VERSION ""

NS_ :

BS_:

BU_: AHLM ASBS CBC DIAGNOST DPDM DTCM ECM EHPS ESC ESL ESM ETM GPF HCP IC IRCM OCM ORC PTS RF_HUB SCCM SGW TBM TCM TPM

BO_ 1026 NM_IC: 8 IC
 SG_ Awake_Diag_Actv m15 : 33|1@1+ (1,0) [0|0] ""  CBC,EHPS,ESC,ESL,ESM,HCP,IC,RF_HUB,SCCM,SGW,TPM
 SG_ Awake_NwSt m15 : 32|1@1+ (1,0) [0|0] ""  CBC,EHPS,ESC,ESL,ESM,HCP,IC,RF_HUB,SCCM,SGW,TPM
 SG_ NM_Mode : 0|8@1+ (1,0) [0|0] ""  CBC,EHPS,ESC,ESL,ESM,HCP,IC,RF_HUB,SCCM,SGW,TPM
 SG_ NM_Sleep_Ack : 22|1@1+ (1,0) [0|0] ""  CBC,EHPS,ESC,ESL,ESM,HCP,IC,RF_HUB,SCCM,SGW,TPM
 SG_ NM_Sleep_Ind : 23|1@1+ (1,0) [0|0] ""  CBC,EHPS,ESC,ESL,ESM,HCP,IC,RF_HUB,SCCM,SGW,TPM
 SG_ NM_Successor : 8|8@1+ (1,0) [0|63] ""  CBC,EHPS,ESC,ESL,ESM,HCP,IC,RF_HUB,SCCM,SGW,TPM
 SG_ NM_Ud_Launch : 16|6@1+ (1,0) [0|0] ""  CBC,EHPS,ESC,ESL,ESM,HCP,IC,RF_HUB,SCCM,SGW,TPM
 SG_ NM_Ud_Srv M : 24|8@1+ (1,0) [0|0] ""  CBC,EHPS,ESC,ESL,ESM,HCP,IC,RF_HUB,SCCM,SGW,TPM
 SG_ Nw_Id : 56|8@1+ (1,0) [0|0] ""  CBC,EHPS,ESC,ESL,ESM,HCP,IC,RF_HUB,SCCM,SGW,TPM
 SG_ WakeupCnt m2 : 40|8@1+ (1,0) [0|254] ""  CBC,EHPS,ESC,ESL,ESM,HCP,IC,RF_HUB,SCCM,SGW,TPM
 SG_ WakeupRsn_IC m2 : 32|8@1+ (1,0) [0|0] ""  CBC,EHPS,ESC,ESL,ESM,HCP,IC,RF_HUB,SCCM,SGW,TPM

BO_ 1024 NM_RF_HUB: 8 RF_HUB
 SG_ Awake_Diag_Actv m15 : 33|1@1+ (1,0) [0|0] ""  CBC,EHPS,ESC,ESL,ESM,HCP,IC,RF_HUB,SCCM,SGW,TPM
 SG_ Awake_NwSt m15 : 32|1@1+ (1,0) [0|0] ""  CBC,EHPS,ESC,ESL,ESM,HCP,IC,RF_HUB,SCCM,SGW,TPM
 SG_ NM_Mode : 0|8@1+ (1,0) [0|0] ""  CBC,EHPS,ESC,ESL,ESM,HCP,IC,RF_HUB,SCCM,SGW,TPM
 SG_ NM_Sleep_Ack : 22|1@1+ (1,0) [0|0] ""  CBC,EHPS,ESC,ESL,ESM,HCP,IC,RF_HUB,SCCM,SGW,TPM
 SG_ NM_Sleep_Ind : 23|1@1+ (1,0) [0|0] ""  CBC,EHPS,ESC,ESL,ESM,HCP,IC,RF_HUB,SCCM,SGW,TPM
 SG_ NM_Successor : 8|8@1+ (1,0) [0|63] ""  CBC,EHPS,ESC,ESL,ESM,HCP,IC,RF_HUB,SCCM,SGW,TPM
 SG_ NM_Ud_Launch : 16|6@1+ (1,0) [0|0] ""  CBC,EHPS,ESC,ESL,ESM,HCP,IC,RF_HUB,SCCM,SGW,TPM
 SG_ NM_Ud_Srv M : 24|8@1+ (1,0) [0|0] ""  CBC,EHPS,ESC,ESL,ESM,HCP,IC,RF_HUB,SCCM,SGW,TPM
 SG_ Nw_Id : 56|8@1+ (1,0) [0|0] ""  CBC,EHPS,ESC,ESL,ESM,HCP,IC,RF_HUB,SCCM,SGW,TPM
 SG_ WakeupCnt m2 : 40|8@1+ (1,0) [0|254] ""  CBC,EHPS,ESC,ESL,ESM,HCP,IC,RF_HUB,SCCM,SGW,TPM
 SG_ WakeupRsn_RF_HUB m2 : 32|8@1+ (1,0) [0|0] ""  CBC,EHPS,ESC,ESL,ESM,HCP,IC,RF_HUB,SCCM,SGW,TPM

BO_ 1033 NM_SBWM: 8 ESM
 SG_ Awake_Diag_Actv m15 : 33|1@1+ (1,0) [0|0] ""  CBC,EHPS,ESC,ESL,ESM,HCP,IC,RF_HUB,SCCM,SGW,TPM
 SG_ Awake_EEPROM m15 : 35|1@1+ (1,0) [0|0] ""  CBC,EHPS,ESC,ESL,ESM,HCP,IC,RF_HUB,SCCM,SGW,TPM
 SG_ Awake_Ignition_On m15 : 34|1@1+ (1,0) [0|0] ""  CBC,EHPS,ESC,ESL,ESM,HCP,IC,RF_HUB,SCCM,SGW,TPM
 SG_ Awake_NwSt m15 : 32|1@1+ (1,0) [0|0] ""  CBC,EHPS,ESC,ESL,ESM,HCP,IC,RF_HUB,SCCM,SGW,TPM
 SG_ Awake_URS m15 : 36|1@1+ (1,0) [0|0] ""  CBC,EHPS,ESC,ESL,ESM,HCP,IC,RF_HUB,SCCM,SGW,TPM
 SG_ NM_Mode : 0|8@1+ (1,0) [0|0] ""  CBC,EHPS,ESC,ESL,ESM,HCP,IC,RF_HUB,SCCM,SGW,TPM
 SG_ NM_Sleep_Ack : 22|1@1+ (1,0) [0|0] ""  CBC,EHPS,ESC,ESL,ESM,HCP,IC,RF_HUB,SCCM,SGW,TPM
 SG_ NM_Sleep_Ind : 23|1@1+ (1,0) [0|0] ""  CBC,EHPS,ESC,ESL,ESM,HCP,IC,RF_HUB,SCCM,SGW,TPM
 SG_ NM_Successor : 8|8@1+ (1,0) [0|63] ""  CBC,EHPS,ESC,ESL,ESM,HCP,IC,RF_HUB,SCCM,SGW,TPM
 SG_ NM_Ud_Launch : 16|6@1+ (1,0) [0|0] ""  CBC,EHPS,ESC,ESL,ESM,HCP,IC,RF_HUB,SCCM,SGW,TPM
 SG_ NM_Ud_Srv M : 24|8@1+ (1,0) [0|0] ""  CBC,EHPS,ESC,ESL,ESM,HCP,IC,RF_HUB,SCCM,SGW,TPM
 SG_ Nw_Id : 56|8@1+ (1,0) [0|0] ""  CBC,EHPS,ESC,ESL,ESM,HCP,IC,RF_HUB,SCCM,SGW,TPM
 SG_ WakeupCnt m2 : 40|8@1+ (1,0) [0|254] ""  CBC,EHPS,ESC,ESL,ESM,HCP,IC,RF_HUB,SCCM,SGW,TPM
 SG_ WakeupRsn_SBWM m2 : 32|8@1+ (1,0) [0|0] ""  CBC,EHPS,ESC,ESL,ESM,HCP,IC,RF_HUB,SCCM,SGW,TPM

BO_ 1059 NM_SCCM: 8 SCCM
 SG_ Awake_Diag_Actv m15 : 33|1@1+ (1,0) [0|0] ""  CBC,EHPS,ESC,ESL,ESM,HCP,IC,RF_HUB,SCCM,SGW,TPM
 SG_ Awake_EEPROM m15 : 36|1@1+ (1,0) [0|0] ""  CBC,EHPS,ESC,ESL,ESM,HCP,IC,RF_HUB,SCCM,SGW,TPM
 SG_ Awake_FTP_Psd m15 : 38|1@1+ (1,0) [0|0] ""  CBC,EHPS,ESC,ESL,ESM,HCP,IC,RF_HUB,SCCM,SGW,TPM
 SG_ Awake_HrnSwt_Actv m15 : 39|1@1+ (1,0) [0|0] ""  CBC,EHPS,ESC,ESL,ESM,HCP,IC,RF_HUB,SCCM,SGW,TPM
 SG_ Awake_Ignition_On m15 : 35|1@1+ (1,0) [0|0] ""  CBC,EHPS,ESC,ESL,ESM,HCP,IC,RF_HUB,SCCM,SGW,TPM
 SG_ Awake_NwSt m15 : 32|1@1+ (1,0) [0|0] ""  CBC,EHPS,ESC,ESL,ESM,HCP,IC,RF_HUB,SCCM,SGW,TPM
 SG_ Awake_StwSw_Actv m15 : 34|1@1+ (1,0) [0|0] ""  CBC,EHPS,ESC,ESL,ESM,HCP,IC,RF_HUB,SCCM,SGW,TPM
 SG_ Awake_tilt_tel_Psd m15 : 37|1@1+ (1,0) [0|0] ""  CBC,EHPS,ESC,ESL,ESM,HCP,IC,RF_HUB,SCCM,SGW,TPM
 SG_ NM_Mode : 0|8@1+ (1,0) [0|0] ""  CBC,EHPS,ESC,ESL,ESM,HCP,IC,RF_HUB,SCCM,SGW,TPM
 SG_ NM_Sleep_Ack : 22|1@1+ (1,0) [0|0] ""  CBC,EHPS,ESC,ESL,ESM,HCP,IC,RF_HUB,SCCM,SGW,TPM
 SG_ NM_Sleep_Ind : 23|1@1+ (1,0) [0|0] ""  CBC,EHPS,ESC,ESL,ESM,HCP,IC,RF_HUB,SCCM,SGW,TPM
 SG_ NM_Successor : 8|8@1+ (1,0) [0|63] ""  CBC,EHPS,ESC,ESL,ESM,HCP,IC,RF_HUB,SCCM,SGW,TPM
 SG_ NM_Ud_Launch : 16|6@1+ (1,0) [0|0] ""  CBC,EHPS,ESC,ESL,ESM,HCP,IC,RF_HUB,SCCM,SGW,TPM
 SG_ NM_Ud_Srv M : 24|8@1+ (1,0) [0|0] ""  CBC,EHPS,ESC,ESL,ESM,HCP,IC,RF_HUB,SCCM,SGW,TPM
 SG_ Nw_Id : 56|8@1+ (1,0) [0|0] ""  CBC,EHPS,ESC,ESL,ESM,HCP,IC,RF_HUB,SCCM,SGW,TPM
 SG_ WakeupCnt m2 : 40|8@1+ (1,0) [0|254] ""  CBC,EHPS,ESC,ESL,ESM,HCP,IC,RF_HUB,SCCM,SGW,TPM
 SG_ WakeupRsn_SCCM m2 : 32|8@1+ (1,0) [0|0] ""  CBC,EHPS,ESC,ESL,ESM,HCP,IC,RF_HUB,SCCM,SGW,TPM

BO_ 1027 NM_TPM: 8 TPM
 SG_ Awake_Diag_Actv m15 : 33|1@1+ (1,0) [0|0] ""  CBC,EHPS,ESC,ESL,ESM,HCP,IC,RF_HUB,SCCM,SGW,TPM
 SG_ Awake_NwSt m15 : 32|1@1+ (1,0) [0|0] ""  CBC,EHPS,ESC,ESL,ESM,HCP,IC,RF_HUB,SCCM,SGW,TPM
 SG_ NM_Mode : 0|8@1+ (1,0) [0|0] ""  CBC,EHPS,ESC,ESL,ESM,HCP,IC,RF_HUB,SCCM,SGW,TPM
 SG_ NM_Sleep_Ack : 22|1@1+ (1,0) [0|0] ""  CBC,EHPS,ESC,ESL,ESM,HCP,IC,RF_HUB,SCCM,SGW,TPM
 SG_ NM_Sleep_Ind : 23|1@1+ (1,0) [0|0] ""  CBC,EHPS,ESC,ESL,ESM,HCP,IC,RF_HUB,SCCM,SGW,TPM
 SG_ NM_Successor : 8|8@1+ (1,0) [0|63] ""  CBC,EHPS,ESC,ESL,ESM,HCP,IC,RF_HUB,SCCM,SGW,TPM
 SG_ NM_Ud_Launch : 16|6@1+ (1,0) [0|0] ""  CBC,EHPS,ESC,ESL,ESM,HCP,IC,RF_HUB,SCCM,SGW,TPM
 SG_ NM_Ud_Srv M : 24|8@1+ (1,0) [0|0] ""  CBC,EHPS,ESC,ESL,ESM,HCP,IC,RF_HUB,SCCM,SGW,TPM
 SG_ Nw_Id : 56|8@1+ (1,0) [0|0] ""  CBC,EHPS,ESC,ESL,ESM,HCP,IC,RF_HUB,SCCM,SGW,TPM
 SG_ WakeupCnt m2 : 40|8@1+ (1,0) [0|254] ""  CBC,EHPS,ESC,ESL,ESM,HCP,IC,RF_HUB,SCCM,SGW,TPM
 SG_ WakeupRsn_TPM m2 : 32|8@1+ (1,0) [0|0] ""  CBC,EHPS,ESC,ESL,ESM,HCP,IC,RF_HUB,SCCM,SGW,TPM

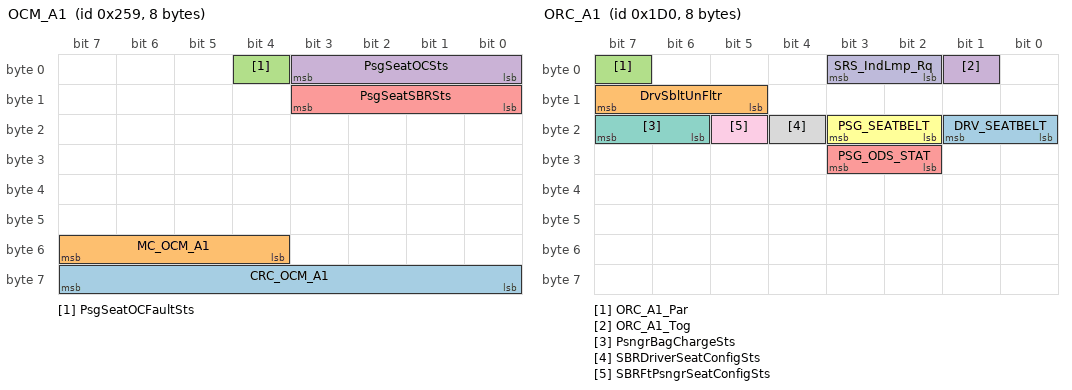
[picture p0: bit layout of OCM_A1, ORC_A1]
BO_ 601 OCM_A1: 8 OCM
 SG_ CRC_OCM_A1 : 56|8@1+ (1,0) [0|0] ""  ORC,SGW
 SG_ MC_OCM_A1 : 52|4@1+ (1,0) [0|15] ""  ORC,SGW
 SG_ PsgSeatOCFaultSts : 4|1@1+ (1,0) [0|0] ""  ORC,SGW
 SG_ PsgSeatOCSts : 0|4@1+ (1,0) [0|0] ""  ORC,RF_HUB,SGW
 SG_ PsgSeatSBRSts : 8|4@1+ (1,0) [0|0] ""  ORC,SGW

BO_ 464 ORC_A1: 8 ORC
 SG_ DRV_SEATBELT : 16|2@1+ (1,0) [0|0] ""  ESC,ETM,HCP,IC,IRCM,SGW,TBM,TCM
 SG_ DrvSbltUnFltr : 13|3@1+ (1,0) [0|0] ""  ECM,SGW
 SG_ ORC_A1_Par : 7|1@1+ (1,0) [0|0] ""  IRCM,SGW
 SG_ ORC_A1_Tog : 1|1@1+ (1,0) [0|0] ""  IRCM,SGW
 SG_ PSG_ODS_STAT : 26|2@1+ (1,0) [0|0] ""  ETM,IC,RF_HUB,SGW,TBM
 SG_ PSG_SEATBELT : 18|2@1+ (1,0) [0|0] ""  ESC,ETM,IC,OCM,SGW,TBM
 SG_ PsngrBagChargeSts : 22|2@1+ (1,0) [0|0] ""  IC,SGW
 SG_ SBRDriverSeatConfigSts : 20|1@1+ (1,0) [0|0] ""  IC,SGW
 SG_ SBRFtPsngrSeatConfigSts : 21|1@1+ (1,0) [0|0] ""  IC,SGW
 SG_ SRS_IndLmp_Rq : 2|2@1+ (1,0) [0|0] ""  ETM,IC,SGW,TBM

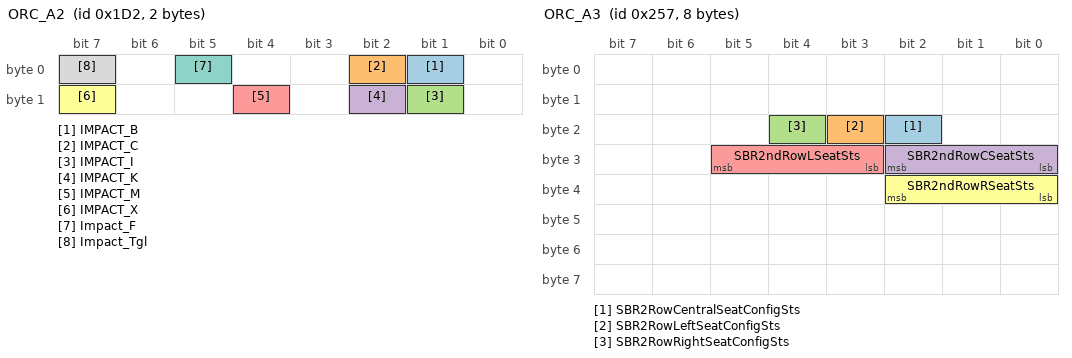
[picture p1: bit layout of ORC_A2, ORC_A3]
BO_ 466 ORC_A2: 2 ORC
 SG_ IMPACT_B : 1|1@1+ (1,0) [0|0] ""  ETM,SGW,TBM
 SG_ IMPACT_C : 2|1@1+ (1,0) [0|0] ""  ETM,SGW,TBM
 SG_ IMPACT_I : 9|1@1+ (1,0) [0|0] ""  ETM,SGW,TBM
 SG_ IMPACT_K : 10|1@1+ (1,0) [0|0] ""  ETM,SGW,TBM
 SG_ IMPACT_M : 12|1@1+ (1,0) [0|0] ""  ETM,SGW,TBM
 SG_ IMPACT_X : 15|1@1+ (1,0) [0|0] ""  CBC,ECM,ETM,HCP,OCM,SGW,TBM
 SG_ Impact_F : 5|1@1+ (1,0) [0|0] ""  ETM,SGW,TBM
 SG_ Impact_Tgl : 7|1@1+ (1,0) [0|0] ""  CBC,ECM,ETM,HCP,OCM,SGW,TBM

BO_ 599 ORC_A3: 8 ORC
 SG_ SBR2RowCentralSeatConfigSts : 18|1@1+ (1,0) [0|0] ""  IC,SGW
 SG_ SBR2RowLeftSeatConfigSts : 19|1@1+ (1,0) [0|0] ""  IC,SGW
 SG_ SBR2RowRightSeatConfigSts : 20|1@1+ (1,0) [0|0] ""  IC,SGW
 SG_ SBR2ndRowCSeatSts : 24|3@1+ (1,0) [0|0] ""  IC,SGW
 SG_ SBR2ndRowLSeatSts : 27|3@1+ (1,0) [0|0] ""  IC,SGW
 SG_ SBR2ndRowRSeatSts : 32|3@1+ (1,0) [0|0] ""  IC,SGW

BO_ 469 ORC_A4: 8 ORC
 SG_ ORC_Health : 23|1@1+ (1,0) [0|0] ""  HCP,SGW

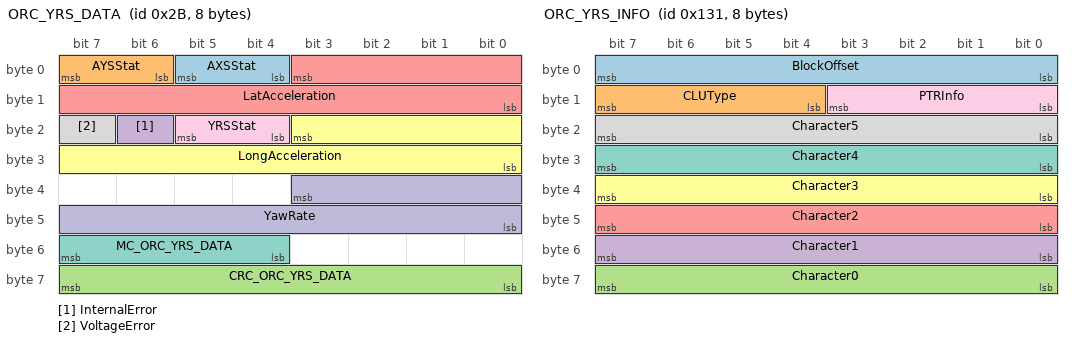
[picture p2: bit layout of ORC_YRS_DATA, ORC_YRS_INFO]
BO_ 43 ORC_YRS_DATA: 8 ORC
 SG_ AXSStat : 4|2@1+ (1,0) [0|0] ""  ESC,HCP,SGW
 SG_ AYSStat : 6|2@1+ (1,0) [0|0] ""  ESC,SGW
 SG_ CRC_ORC_YRS_DATA : 56|8@1+ (1,0) [0|0] ""  ESC,SGW
 SG_ InternalError : 22|1@1+ (1,0) [0|0] ""  ESC,SGW
 SG_ LatAcceleration : 3|12@0+ (0.02,-40.96) [-40.96|40.92] "m/s²"  ESC,SGW
 SG_ LongAcceleration : 19|12@0+ (0.02,-40.96) [-40.96|40.92] "m/s²"  ESC,HCP,SGW
 SG_ MC_ORC_YRS_DATA : 52|4@1+ (1,0) [0|15] ""  ESC,SGW
 SG_ VoltageError : 23|1@1+ (1,0) [0|0] ""  ESC,SGW
 SG_ YRSStat : 20|2@1+ (1,0) [0|0] ""  ESC,SGW
 SG_ YawRate : 35|12@0+ (0.08,-163.84) [-163.84|163.68] "°/s"  ESC,SGW

BO_ 305 ORC_YRS_INFO: 8 ORC
 SG_ BlockOffset : 0|8@1+ (1,0) [0|0] ""  ESC,SGW
 SG_ CLUType : 12|4@1+ (1,0) [0|0] ""  ESC,SGW
 SG_ Character0 : 56|8@1+ (1,0) [0|0] ""  ESC,SGW
 SG_ Character1 : 48|8@1+ (1,0) [0|0] ""  ESC,SGW
 SG_ Character2 : 40|8@1+ (1,0) [0|0] ""  ESC,SGW
 SG_ Character3 : 32|8@1+ (1,0) [0|0] ""  ESC,SGW
 SG_ Character4 : 24|8@1+ (1,0) [0|0] ""  ESC,SGW
 SG_ Character5 : 16|8@1+ (1,0) [0|0] ""  ESC,SGW
 SG_ PTRInfo : 8|4@1+ (1,0) [0|0] ""  ESC,SGW

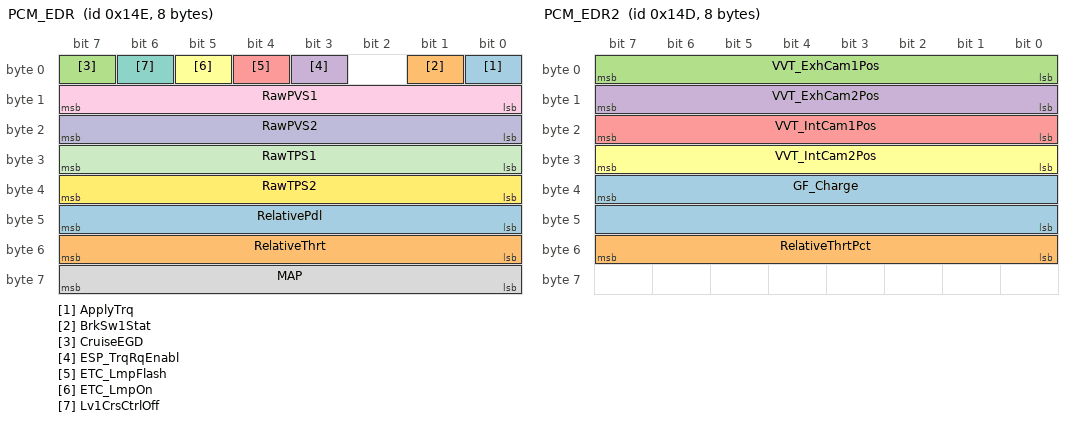
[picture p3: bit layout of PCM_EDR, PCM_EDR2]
BO_ 334 PCM_EDR: 8 ECM
 SG_ ApplyTrq : 0|1@1+ (1,0) [0|0] ""  SGW
 SG_ BrkSw1Stat : 1|1@1+ (1,0) [0|0] ""  ETM,SGW,TBM
 SG_ CruiseEGD : 7|1@1+ (1,0) [0|0] ""  SGW
 SG_ ESP_TrqRqEnabl : 3|1@1+ (1,0) [0|0] ""  ORC,SGW
 SG_ ETC_LmpFlash : 4|1@1+ (1,0) [0|0] ""  ORC,SGW
 SG_ ETC_LmpOn : 5|1@1+ (1,0) [0|0] ""  ORC,SGW
 SG_ Lv1CrsCtrlOff : 6|1@1+ (1,0) [0|0] ""  ORC,SGW
 SG_ MAP : 56|8@1+ (0.8,0) [0|203.2] "kPa"  ESC,SGW
 SG_ RawPVS1 : 8|8@1+ (0.019607843,0) [0|4.98] "Volts"  ORC,SGW
 SG_ RawPVS2 : 16|8@1+ (0.019607843,0) [0|4.98] "Volts"  ORC,SGW
 SG_ RawTPS1 : 24|8@1+ (0.019607843,0) [0|4.98] "Volts"  ORC,SGW
 SG_ RawTPS2 : 32|8@1+ (0.019607843,0) [0|4.98] "Volts"  ORC,SGW
 SG_ RelativePdl : 40|8@1+ (0.019607843,0) [0|4.98] "Volts"  SGW
 SG_ RelativeThrt : 48|8@1+ (0.019607843,0) [0|4.98] "Volts"  SGW

BO_ 333 PCM_EDR2: 8 ECM
 SG_ GF_Charge : 39|16@0+ (0.2,0) [0|13106.8] "mg/cycle/cyl"  ETM,ORC,SGW,TBM
 SG_ RelativeThrtPct : 48|8@1+ (0.4,0) [0|100] "%"  ORC,SGW
 SG_ VVT_ExhCam1Pos : 0|8@1+ (1,0) [1|255] "Degrees"  SGW
 SG_ VVT_ExhCam2Pos : 8|8@1+ (1,0) [1|255] "Degrees"  SGW
 SG_ VVT_IntCam1Pos : 16|8@1+ (1,0) [1|255] "Degrees"  SGW
 SG_ VVT_IntCam2Pos : 24|8@1+ (1,0) [1|255] "Degrees"  SGW

BO_ 584 PN14_STAT: 8 CBC
 SG_ Batt_ST_Crit : 42|1@1+ (1,0) [0|0] ""  IC,SGW
 SG_ PN14_LS_Actv : 0|1@1+ (1,0) [0|0] ""  IC,SGW

BO_ 502 PTS_1: 8 PTS
 SG_ PTS_AlrFC : 40|4@1+ (1,0) [0|0] ""  IC,SGW
 SG_ PTS_AlrFL : 8|4@1+ (1,0) [0|0] ""  IC,SGW
 SG_ PTS_AlrFR : 16|4@1+ (1,0) [0|0] ""  IC,SGW
 SG_ PTS_AlrRC : 48|4@1+ (1,0) [0|0] ""  CBC,IC,SGW
 SG_ PTS_AlrRL : 24|4@1+ (1,0) [0|0] ""  CBC,IC,SGW
 SG_ PTS_AlrRR : 32|4@1+ (1,0) [0|0] ""  CBC,IC,SGW
 SG_ PTS_CFG_STAT : 1|2@1+ (1,0) [0|0] ""  CBC,SGW
 SG_ PTS_FT_NA : 3|1@1+ (1,0) [0|0] ""  IC,SGW
 SG_ PTS_FT_SRV : 58|1@1+ (1,0) [0|0] ""  ETM,IC,SGW,TBM
 SG_ PTS_GraphicFC : 46|2@1+ (1,0) [0|0] ""  IC,SGW
 SG_ PTS_GraphicFL : 14|2@1+ (1,0) [0|0] ""  IC,SGW
 SG_ PTS_GraphicFR : 22|2@1+ (1,0) [0|0] ""  IC,SGW
 SG_ PTS_GraphicRC : 54|2@1+ (1,0) [0|0] ""  IC,SGW
 SG_ PTS_GraphicRL : 30|2@1+ (1,0) [0|0] ""  IC,SGW
 SG_ PTS_GraphicRR : 38|2@1+ (1,0) [0|0] ""  IC,SGW
 SG_ PTS_RR_NA : 4|1@1+ (1,0) [0|0] ""  IC,SGW
 SG_ PTS_RR_SRV : 59|1@1+ (1,0) [0|0] ""  ETM,IC,SGW,TBM
 SG_ PTS_SRV_RQ : 5|1@1+ (1,0) [0|0] ""  IC,SGW
 SG_ PTS_STAT : 60|2@1+ (1,0) [0|0] ""  CBC,SGW

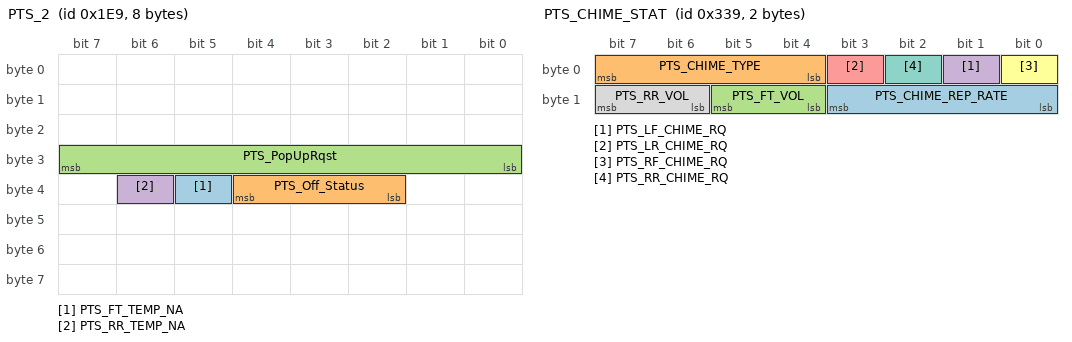
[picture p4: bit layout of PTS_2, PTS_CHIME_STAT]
BO_ 489 PTS_2: 8 PTS
 SG_ PTS_FT_TEMP_NA : 37|1@1+ (1,0) [0|0] ""  IC,SGW
 SG_ PTS_Off_Status : 34|3@1+ (1,0) [0|0] ""  IC,SGW
 SG_ PTS_PopUpRqst : 24|8@1+ (1,0) [0|0] ""  IC,SGW
 SG_ PTS_RR_TEMP_NA : 38|1@1+ (1,0) [0|0] ""  IC,SGW

BO_ 825 PTS_CHIME_STAT: 2 PTS
 SG_ PTS_CHIME_REP_RATE : 8|4@1+ (1,0) [0|15] "Hz"  CBC,SGW
 SG_ PTS_CHIME_TYPE : 4|4@1+ (1,0) [0|0] ""  CBC,SGW
 SG_ PTS_FT_VOL : 12|2@1+ (1,0) [0|0] ""  CBC,SGW
 SG_ PTS_LF_CHIME_RQ : 1|1@1+ (1,0) [0|0] ""  CBC,SGW
 SG_ PTS_LR_CHIME_RQ : 3|1@1+ (1,0) [0|0] ""  CBC,SGW
 SG_ PTS_RF_CHIME_RQ : 0|1@1+ (1,0) [0|0] ""  CBC,SGW
 SG_ PTS_RR_CHIME_RQ : 2|1@1+ (1,0) [0|0] ""  CBC,SGW
 SG_ PTS_RR_VOL : 14|2@1+ (1,0) [0|0] ""  CBC,SGW

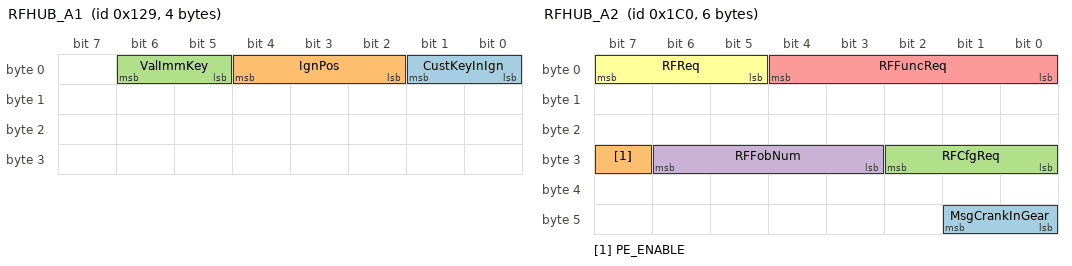
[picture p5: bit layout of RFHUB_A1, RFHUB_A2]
BO_ 297 RFHUB_A1: 4 RF_HUB
 SG_ CustKeyInIgn : 0|2@1+ (1,0) [0|0] ""  CBC,ETM,SGW,TBM
 SG_ IgnPos : 2|3@1+ (1,0) [0|0] ""  CBC,ETM,SGW,TBM
 SG_ ValImmKey : 5|2@1+ (1,0) [0|0] ""  SGW

BO_ 448 RFHUB_A2: 6 RF_HUB
 SG_ MsgCrankInGear : 40|2@1+ (1,0) [0|0] ""  IC,SGW
 SG_ PE_ENABLE : 31|1@1+ (1,0) [0|0] ""  CBC,SGW
 SG_ RFCfgReq : 24|3@1+ (1,0) [0|0] ""  CBC,SGW
 SG_ RFFobNum : 27|4@1+ (1,0) [0|0] ""  CBC,SGW
 SG_ RFFuncReq : 0|5@1+ (1,0) [0|0] ""  CBC,ETM,IC,SGW,TBM
 SG_ RFReq : 5|3@1+ (1,0) [0|0] ""  CBC,ETM,IC,SGW,TBM

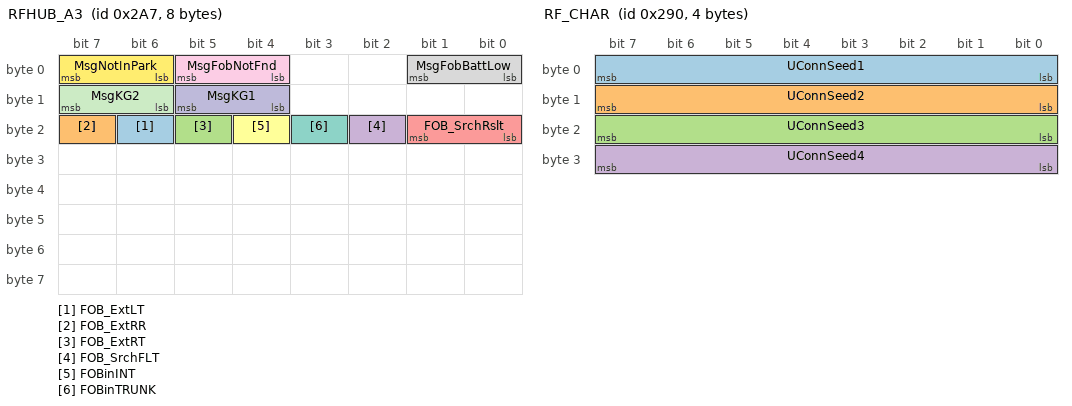
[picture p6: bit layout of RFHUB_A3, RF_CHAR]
BO_ 679 RFHUB_A3: 8 RF_HUB
 SG_ FOB_ExtLT : 22|1@1+ (1,0) [0|0] ""  CBC,SGW
 SG_ FOB_ExtRR : 23|1@1+ (1,0) [0|0] ""  CBC,SGW
 SG_ FOB_ExtRT : 21|1@1+ (1,0) [0|0] ""  CBC,SGW
 SG_ FOB_SrchFLT : 18|1@1+ (1,0) [0|0] ""  CBC,SGW
 SG_ FOB_SrchRslt : 16|2@1+ (1,0) [0|0] ""  CBC,SGW
 SG_ FOBinINT : 20|1@1+ (1,0) [0|0] ""  CBC,SGW
 SG_ FOBinTRUNK : 19|1@1+ (1,0) [0|0] ""  SGW
 SG_ MsgFobBattLow : 0|2@1+ (1,0) [0|0] ""  IC,SGW
 SG_ MsgFobNotFnd : 4|2@1+ (1,0) [0|0] ""  IC,SGW
 SG_ MsgKG1 : 12|2@1+ (1,0) [0|0] ""  IC,SGW
 SG_ MsgKG2 : 14|2@1+ (1,0) [0|0] ""  IC,SGW
 SG_ MsgNotInPark : 6|2@1+ (1,0) [0|0] ""  IC,SGW

BO_ 656 RF_CHAR: 4 RF_HUB
 SG_ UConnSeed1 : 0|8@1+ (1,0) [0|0] ""  ETM,SGW,TBM
 SG_ UConnSeed2 : 8|8@1+ (1,0) [0|0] ""  ETM,SGW,TBM
 SG_ UConnSeed3 : 16|8@1+ (1,0) [0|0] ""  ETM,SGW,TBM
 SG_ UConnSeed4 : 24|8@1+ (1,0) [0|0] ""  ETM,SGW,TBM

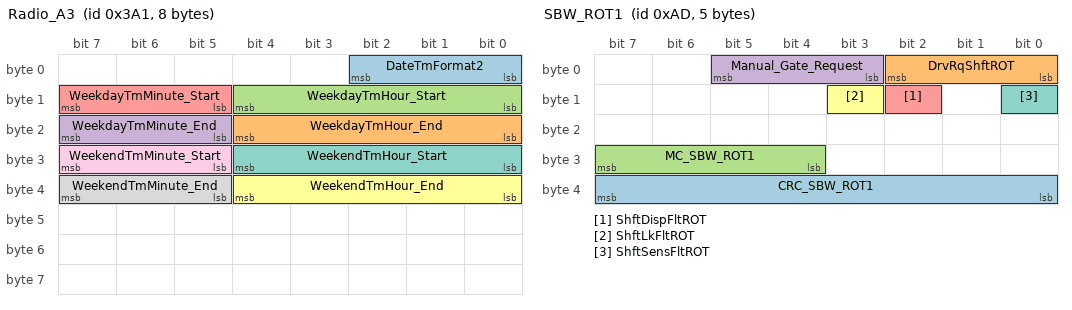
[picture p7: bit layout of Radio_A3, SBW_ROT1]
BO_ 929 Radio_A3: 8 CBC
 SG_ DateTmFormat2 : 0|3@1+ (1,0) [0|0] ""  HCP,IC,SGW
 SG_ WeekdayTmHour_End : 16|5@1+ (1,0) [0|24] "Hours"  IC,SGW
 SG_ WeekdayTmHour_Start : 8|5@1+ (1,0) [0|24] "Hours"  IC,SGW
 SG_ WeekdayTmMinute_End : 21|3@1+ (1,0) [0|0] "min"  IC,SGW
 SG_ WeekdayTmMinute_Start : 13|3@1+ (1,0) [0|0] "min"  IC,SGW
 SG_ WeekendTmHour_End : 32|5@1+ (1,0) [0|24] "Hours"  IC,SGW
 SG_ WeekendTmHour_Start : 24|5@1+ (1,0) [0|24] "Hours"  IC,SGW
 SG_ WeekendTmMinute_End : 37|3@1+ (1,0) [0|0] "min"  IC,SGW
 SG_ WeekendTmMinute_Start : 29|3@1+ (1,0) [0|0] "min"  IC,SGW

BO_ 302 Radio_A4: 8 CBC
 SG_ STFAFtAlertPress : 0|8@1+ (1,0) [0|126] "psi"  SGW,TPM
 SG_ STFARrAlertPress : 8|8@1+ (1,0) [0|126] "psi"  SGW,TPM

BO_ 173 SBW_ROT1: 5 ESM
 SG_ CRC_SBW_ROT1 : 32|8@1+ (1,0) [0|0] ""  ECM,HCP,SGW,TCM
 SG_ DrvRqShftROT : 0|3@1+ (1,0) [0|0] ""  CBC,DTCM,ECM,ETM,HCP,RF_HUB,SGW,TBM,TCM
 SG_ MC_SBW_ROT1 : 28|4@1+ (1,0) [0|15] ""  ECM,HCP,SGW,TCM
 SG_ Manual_Gate_Request : 3|3@1+ (1,0) [0|0] ""  ECM,SGW,TCM
 SG_ ShftDispFltROT : 10|1@1+ (1,0) [0|0] ""  SGW,TCM
 SG_ ShftLkFltROT : 11|1@1+ (1,0) [0|0] ""  SGW,TCM
 SG_ ShftSensFltROT : 8|1@1+ (1,0) [0|0] ""  IC,SGW,TCM

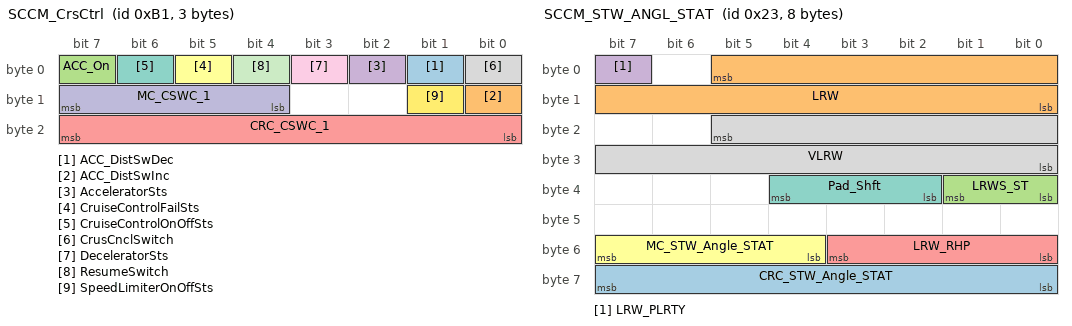
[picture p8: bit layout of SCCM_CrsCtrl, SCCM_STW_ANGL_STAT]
BO_ 177 SCCM_CrsCtrl: 3 SCCM
 SG_ ACC_DistSwDec : 1|1@1+ (1,0) [0|0] ""  ECM,ETM,IRCM,SGW,TBM
 SG_ ACC_DistSwInc : 8|1@1+ (1,0) [0|0] ""  ECM,ETM,IRCM,SGW,TBM
 SG_ ACC_On : 7|1@1+ (1,0) [0|0] ""  ECM,ESC,ETM,IRCM,SGW,TBM
 SG_ AcceleratorSts : 2|1@1+ (1,0) [0|0] ""  ECM,ESC,ETM,IRCM,SGW,TBM
 SG_ CRC_CSWC_1 : 16|8@1+ (1,0) [0|0] ""  ECM,IRCM,SGW
 SG_ CruiseControlFailSts : 5|1@1+ (1,0) [0|0] ""  ECM,ESC,IRCM,SGW
 SG_ CruiseControlOnOffSts : 6|1@1+ (1,0) [0|0] ""  ECM,ESC,ETM,IRCM,SGW,TBM
 SG_ CrusCnclSwitch : 0|1@1+ (1,0) [0|0] ""  ECM,ESC,ETM,IRCM,SGW,TBM
 SG_ DeceleratorSts : 3|1@1+ (1,0) [0|0] ""  ECM,ESC,ETM,IRCM,SGW,TBM
 SG_ MC_CSWC_1 : 12|4@1+ (1,0) [0|15] ""  ECM,IRCM,SGW
 SG_ ResumeSwitch : 4|1@1+ (1,0) [0|0] ""  ECM,ESC,ETM,IRCM,SGW,TBM
 SG_ SpeedLimiterOnOffSts : 9|1@1+ (1,0) [0|0] ""  ECM,IRCM,SGW

BO_ 35 SCCM_STW_ANGL_STAT: 8 SCCM
 SG_ CRC_STW_Angle_STAT : 56|8@1+ (1,0) [0|0] ""  ECM,ESC,ETM,IRCM,ORC,SGW,TCM
 SG_ LRW : 5|14@0+ (0.5,-2048) [-2048|2047] "Degrees"  CBC,DTCM,ECM,EHPS,ESC,IC,IRCM,ORC,SGW,TCM
 SG_ LRWS_ST : 32|2@1+ (1,0) [0|0] ""  CBC,DTCM,ECM,ESC,IC,IRCM,ORC,SGW
 SG_ LRW_PLRTY : 7|1@1+ (1,0) [0|0] ""  ESC,ETM,IC,IRCM,ORC,SGW
 SG_ LRW_RHP : 48|4@1+ (0.1,-0.4) [-0.4|0.4] "Degrees"  EHPS,SGW
 SG_ MC_STW_Angle_STAT : 52|4@1+ (1,0) [0|15] ""  ECM,ESC,ETM,IRCM,ORC,SGW,TCM
 SG_ Pad_Shft : 34|3@1+ (1,0) [0|0] ""  SGW,TCM
 SG_ VLRW : 21|14@0+ (0.5,-2048) [-2048|2047] "°/s"  DTCM,ECM,EHPS,ESC,IRCM,SGW

BO_ 1577 SD_RS_AHLM: 8 AHLM
 SG_ SD_RS_AHLM : 7|64@0+ (1,0) [0|0] ""  ETM,SGW,TBM

BO_ 1546 SD_RS_ASBS: 8 ASBS
 SG_ SD_RS_ASBS : 7|64@0+ (1,0) [0|0] ""  ETM,SGW,TBM

BO_ 1596 SD_RS_BSMO: 8 ESC
 SG_ SD_RS_BSMO : 7|64@0+ (1,0) [0|0] ""  ETM,SGW,TBM

BO_ 1537 SD_RS_CBC: 8 CBC
 SG_ SD_RS_CBC : 7|64@0+ (1,0) [0|0] ""  ETM,SGW,TBM

BO_ 1555 SD_RS_DASM: 8 IRCM
 SG_ SD_RS_DASM : 7|64@0+ (1,0) [0|0] ""  ETM,SGW,TBM

BO_ 1553 SD_RS_DPDM: 8 DPDM
 SG_ SD_RS_DPDM : 7|64@0+ (1,0) [0|0] ""  ETM,SGW,TBM

BO_ 1547 SD_RS_DTCM: 8 DTCM
 SG_ SD_RS_DTCM : 7|64@0+ (1,0) [0|0] ""  ETM,SGW,TBM

BO_ 1592 SD_RS_ECM: 8 ECM
 SG_ SD_RS_ECM : 7|64@0+ (1,0) [0|0] ""  DIAGNOST,ETM,SGW,TBM

CM_ SG_ 1026 Awake_Diag_Actv "Stay awake for diagnostics active; True = [1]";
CM_ SG_ 1026 Awake_NwSt "Stay awake for network startup; True = [1]";
CM_ SG_ 1026 NM_Mode "Network management mode";
CM_ SG_ 1026 NM_Sleep_Ack "Network management sleep acknowledge; True = [1]";
CM_ SG_ 1026 NM_Sleep_Ind "Network management sleep indication; True = [1]";
CM_ SG_ 1026 NM_Successor "Network management logical successor";
CM_ SG_ 1026 NM_Ud_Launch "Network management userdata launch type";
CM_ SG_ 1026 NM_Ud_Srv "Network management userdata service no.";
CM_ SG_ 1026 Nw_Id "Network identification no.";
CM_ SG_ 1026 WakeupCnt "Counter for module wakeup states during network sleep";
CM_ SG_ 1026 WakeupRsn_IC "Wakeup reason IC";
CM_ SG_ 1024 Awake_Diag_Actv "Stay awake for diagnostics active; True = [1]";
CM_ SG_ 1024 Awake_NwSt "Stay awake for network startup; True = [1]";
CM_ SG_ 1024 NM_Mode "Network management mode";
CM_ SG_ 1024 NM_Sleep_Ack "Network management sleep acknowledge; True = [1]";
CM_ SG_ 1024 NM_Sleep_Ind "Network management sleep indication; True = [1]";
CM_ SG_ 1024 NM_Successor "Network management logical successor";
CM_ SG_ 1024 NM_Ud_Launch "Network management userdata launch type";
CM_ SG_ 1024 NM_Ud_Srv "Network management userdata service no.";
CM_ SG_ 1024 Nw_Id "Network identification no.";
CM_ SG_ 1024 WakeupCnt "Counter for module wakeup states during network sleep";
CM_ SG_ 1024 WakeupRsn_RF_HUB "Wakeup reason RF_HUB";
CM_ SG_ 1033 Awake_Diag_Actv "Stay awake for diagnostics active; True = [1]";
CM_ SG_ 1033 Awake_EEPROM "Stay awake for EEPROM write access; True = [1]";
CM_ SG_ 1033 Awake_Ignition_On "Stay awake for ignition on; True = [1]";
CM_ SG_ 1033 Awake_NwSt "Stay awake for network startup; True = [1]";
CM_ SG_ 1033 Awake_URS "Stay awake for 'Unlock Run Start' hardwired input; True = [1]";
CM_ SG_ 1033 NM_Mode "Network management mode";
CM_ SG_ 1033 NM_Sleep_Ack "Network management sleep acknowledge; True = [1]";
CM_ SG_ 1033 NM_Sleep_Ind "Network management sleep indication; True = [1]";
CM_ SG_ 1033 NM_Successor "Network management logical successor";
CM_ SG_ 1033 NM_Ud_Launch "Network management userdata launch type";
CM_ SG_ 1033 NM_Ud_Srv "Network management userdata service no.";
CM_ SG_ 1033 Nw_Id "Network identification no.";
CM_ SG_ 1033 WakeupCnt "Counter for module wakeup states during network sleep";
CM_ SG_ 1033 WakeupRsn_SBWM "Wakeup reason SBWM";
CM_ SG_ 1059 Awake_Diag_Actv "Stay awake for diagnostics active; True = [1]";
CM_ SG_ 1059 Awake_EEPROM "Stay awake for EEPROM write access; True = [1]";
CM_ SG_ 1059 Awake_FTP_Psd "Stay awake for flash to pass lever actuated; True = [1]";
CM_ SG_ 1059 Awake_HrnSwt_Actv "Stay awake for  horn switch active; True = [1]";
CM_ SG_ 1059 Awake_Ignition_On "Stay awake for ignition on; True = [1]";
CM_ SG_ 1059 Awake_NwSt "Stay awake for network startup; True = [1]";
CM_ SG_ 1059 Awake_StwSw_Actv "Stay awake for steering wheel switches active; True = [1]";
CM_ SG_ 1059 Awake_tilt_tel_Psd "Stay awake for tilt/telescope switch actuated; True = [1]";
CM_ SG_ 1059 NM_Mode "Network management mode";
CM_ SG_ 1059 NM_Sleep_Ack "Network management sleep acknowledge; True = [1]";
CM_ SG_ 1059 NM_Sleep_Ind "Network management sleep indication; True = [1]";
CM_ SG_ 1059 NM_Successor "Network management logical successor";
CM_ SG_ 1059 NM_Ud_Launch "Network management userdata launch type";
CM_ SG_ 1059 NM_Ud_Srv "Network management userdata service no.";
CM_ SG_ 1059 Nw_Id "Network identification no.";
CM_ SG_ 1059 WakeupCnt "Counter for module wakeup states during network sleep";
CM_ SG_ 1059 WakeupRsn_SCCM "Wakeup reason SCCM";
CM_ SG_ 1027 Awake_Diag_Actv "Stay awake for diagnostics active; True = [1]";
CM_ SG_ 1027 Awake_NwSt "Stay awake for network startup; True = [1]";
CM_ SG_ 1027 NM_Mode "Network management mode";
CM_ SG_ 1027 NM_Sleep_Ack "Network management sleep acknowledge; True = [1]";
CM_ SG_ 1027 NM_Sleep_Ind "Network management sleep indication; True = [1]";
CM_ SG_ 1027 NM_Successor "Network management logical successor";
CM_ SG_ 1027 NM_Ud_Launch "Network management userdata launch type";
CM_ SG_ 1027 NM_Ud_Srv "Network management userdata service no.";
CM_ SG_ 1027 Nw_Id "Network identification no.";
CM_ SG_ 1027 WakeupCnt "Counter for module wakeup states during network sleep";
CM_ SG_ 1027 WakeupRsn_TPM "Wakeup reason TPM";
CM_ SG_ 601 CRC_OCM_A1 "CRC-checksum byte 1 to 7 according to SAE J1850";
CM_ SG_ 601 MC_OCM_A1 "Message counter";
CM_ SG_ 601 PsgSeatOCFaultSts "Passenger occupant classification fault; True = [1]";
CM_ SG_ 601 PsgSeatOCSts "Occupant classification passenger";
CM_ SG_ 601 PsgSeatSBRSts "Passenger seatbelt reminder status";
CM_ SG_ 464 DRV_SEATBELT "Drivers seat belt status";
CM_ SG_ 464 DrvSbltUnFltr "Drivers seat belt fault status - unfiltered";
CM_ SG_ 464 ORC_A1_Par "ORC_A1 even parity bit";
CM_ SG_ 464 ORC_A1_Tog "ORC_A1 toggle bit";
CM_ SG_ 464 PSG_ODS_STAT "Passenger Occupant Detection Sensor Status";
CM_ SG_ 464 PSG_SEATBELT "Passengers seat belt status";
CM_ SG_ 464 PsngrBagChargeSts "Passenger airbag charge status";
CM_ SG_ 464 SBRDriverSeatConfigSts "Driver seatbelt switch configuration; seat checked = [1]";
CM_ SG_ 464 SBRFtPsngrSeatConfigSts "Front passenger seatbelt switch configuration; seat checked = [1]";
CM_ SG_ 464 SRS_IndLmp_Rq "SRS indication lamp request";
CM_ SG_ 466 IMPACT_B "EARS Rear Event; actuate = [1]; do_not_actuate = [0]";
CM_ SG_ 466 IMPACT_C "EARS higher severity front event; actuate = [1]; do_not_actuate = [0]";
CM_ SG_ 466 IMPACT_I "EARS Rollover Event; actuate = [1]; do_not_actuate = [0]";
CM_ SG_ 466 IMPACT_K "EARS left side event; actuate = [1]; do_not_actuate = [0]";
CM_ SG_ 466 IMPACT_M "EARS right side event; actuate = [1]; do_not_actuate = [0]";
CM_ SG_ 466 IMPACT_X "Any impact event; actuate = [1]; do_not_actuate = [0]";
CM_ SG_ 466 Impact_F "EARS lower severity front event; actuate = [1]; do_not_actuate = [0]";
CM_ SG_ 466 Impact_Tgl "Toggle bit for all impact events; See Signal Description Document";
CM_ SG_ 599 SBR2RowCentralSeatConfigSts "Second row central seatbelt switch configuration; Seat checked = [1]";
CM_ SG_ 599 SBR2RowLeftSeatConfigSts "Second row left seatbelt switch configuration; Seat checked = [1]";
CM_ SG_ 599 SBR2RowRightSeatConfigSts "Second row right seatbelt switch configuration; Seat checked = [1]";
CM_ SG_ 599 SBR2ndRowCSeatSts "Second row central seatbelt reminder status";
CM_ SG_ 599 SBR2ndRowLSeatSts "Second row left seatbelt reminder status";
CM_ SG_ 599 SBR2ndRowRSeatSts "Second row right seatbelt reminder status";
CM_ SG_ 469 ORC_Health "ORC alive and active; True = [1]";
CM_ SG_ 43 AXSStat "Longitudinal signal status";
CM_ SG_ 43 AYSStat "Latitudinal signal status";
CM_ SG_ 43 CRC_ORC_YRS_DATA "CRC-checksum byte 1 to 7 according to SAE J1850";
CM_ SG_ 43 InternalError "ORC ESC internal error; True = [1]";
CM_ SG_ 43 LatAcceleration "Raw lateral acceleration";
CM_ SG_ 43 LongAcceleration "Raw longitudinal acceleration";
CM_ SG_ 43 MC_ORC_YRS_DATA "Message counter";
CM_ SG_ 43 VoltageError "ORC ESC voltage error; True = [1]";
CM_ SG_ 43 YRSStat "Yaw rate signal status";
CM_ SG_ 43 YawRate "Raw yaw acceleration";
CM_ SG_ 305 BlockOffset "Part number block offset";
CM_ SG_ 305 CLUType "Part number CLU type";
CM_ SG_ 305 Character0 "Part number character 0";
CM_ SG_ 305 Character1 "Part number character 1";
CM_ SG_ 305 Character2 "Part number character 2";
CM_ SG_ 305 Character3 "Part number character 3";
CM_ SG_ 305 Character4 "Part number character 4";
CM_ SG_ 305 Character5 "Part number character 5";
CM_ SG_ 305 PTRInfo "Part number PTR information";
CM_ SG_ 334 ApplyTrq "EDR ONLY - Torque may be applied to the wheels";
CM_ SG_ 334 BrkSw1Stat "EDR ONLY - Brake switch1 status, off = [0]";
CM_ SG_ 334 CruiseEGD "EDR ONLY - Cruise system is engaged";
CM_ SG_ 334 ESP_TrqRqEnabl "EDR ONLY - ESP torque requests are allowed = [1]";
CM_ SG_ 334 ETC_LmpFlash "EDR ONLY - ETC lamp is flashing";
CM_ SG_ 334 ETC_LmpOn "EDR ONLY - ETC lamp is on";
CM_ SG_ 334 Lv1CrsCtrlOff "EDR ONLY - Level is requested cruise off";
CM_ SG_ 334 MAP "EDR ONLY - Intake manifold pressure";
CM_ SG_ 334 RawPVS1 "EDR ONLY - Raw pedal value sensor #1";
CM_ SG_ 334 RawPVS2 "EDR ONLY - Raw pedal value sensor #2";
CM_ SG_ 334 RawTPS1 "EDR ONLY - Raw throttle position sensor #1";
CM_ SG_ 334 RawTPS2 "EDR ONLY - Raw throttle position sensor #2";
CM_ SG_ 334 RelativePdl "EDR ONLY - Relative pedal value";
CM_ SG_ 334 RelativeThrt "EDR ONLY - Relative throttle value";
CM_ SG_ 333 GF_Charge "EDR ONLY - Port flow per cylinder per stroke";
CM_ SG_ 333 RelativeThrtPct "EDR ONLY - Relative throttle percent";
CM_ SG_ 333 VVT_ExhCam1Pos "EDR ONLY - Centerline position for exhaust cam on bank 1";
CM_ SG_ 333 VVT_ExhCam2Pos "EDR ONLY - Centerline position for exhaust cam on bank 2";
CM_ SG_ 333 VVT_IntCam1Pos "EDR ONLY - Centerline position for intake cam on bank 1";
CM_ SG_ 333 VVT_IntCam2Pos "EDR ONLY - Centerline position for intake cam on bank 2";
CM_ SG_ 584 Batt_ST_Crit "Battery reached critical state";
CM_ SG_ 584 PN14_LS_Actv "14 V powernet Load Shed active";
CM_ SG_ 502 PTS_AlrFC "PTS alert front center";
CM_ SG_ 502 PTS_AlrFL "PTS alert front left";
CM_ SG_ 502 PTS_AlrFR "PTS alert front right";
CM_ SG_ 502 PTS_AlrRC "PTS alert rear center";
CM_ SG_ 502 PTS_AlrRL "PTS alert rear left";
CM_ SG_ 502 PTS_AlrRR "PTS alert rear right";
CM_ SG_ 502 PTS_CFG_STAT "Park assist configuration status";
CM_ SG_ 502 PTS_FT_NA "Front park assist not available - blinded sensor; True = [1]";
CM_ SG_ 502 PTS_FT_SRV "Front PTS sensor service request; True = [1]";
CM_ SG_ 502 PTS_GraphicFC "PTS graphic flash rate front center";
CM_ SG_ 502 PTS_GraphicFL "PTS graphic flash rate front left";
CM_ SG_ 502 PTS_GraphicFR "PTS graphic flash rate front right";
CM_ SG_ 502 PTS_GraphicRC "PTS graphic flash rate rear center";
CM_ SG_ 502 PTS_GraphicRL "PTS graphic flash rate rear left";
CM_ SG_ 502 PTS_GraphicRR "PTS graphic flash rate rear right";
CM_ SG_ 502 PTS_RR_NA "Rear park assist not available - blinded sensor; True = [1]";
CM_ SG_ 502 PTS_RR_SRV "Rear PTS sensor service request; True = [1]";
CM_ SG_ 502 PTS_SRV_RQ "PTS service warning request; True = [1]";
CM_ SG_ 502 PTS_STAT "Park Assist System - LED control status";
CM_ SG_ 489 PTS_FT_TEMP_NA "ParkSense front system temporarily not available; True = [1]";
CM_ SG_ 489 PTS_Off_Status "ParkSense system on/off status indication";
CM_ SG_ 489 PTS_PopUpRqst "ParkSense HMI pop-up message request";
CM_ SG_ 489 PTS_RR_TEMP_NA "ParkSense rear system temporarily not available; True = [1]";
CM_ SG_ 825 PTS_CHIME_REP_RATE "PTS chime repetition rate";
CM_ SG_ 825 PTS_CHIME_TYPE "PTS chime type";
CM_ SG_ 825 PTS_FT_VOL "PTS Front Volume Setting";
CM_ SG_ 825 PTS_LF_CHIME_RQ "PTS left front chime on request; True = [1]";
CM_ SG_ 825 PTS_LR_CHIME_RQ "PTS left rear chime on request; True = [1]";
CM_ SG_ 825 PTS_RF_CHIME_RQ "PTS right front chime on request; True = [1]";
CM_ SG_ 825 PTS_RR_CHIME_RQ "PTS right rear chime on request; True = [1]";
CM_ SG_ 825 PTS_RR_VOL "PTS Rear Volume Setting";
CM_ SG_ 297 CustKeyInIgn "Driver's request, key-in-ignition";
CM_ SG_ 297 IgnPos "Drivers request, ignition position";
CM_ SG_ 297 ValImmKey "Drivers request, immobilizer results";
CM_ SG_ 448 MsgCrankInGear "Crank in gear HMI message";
CM_ SG_ 448 PE_ENABLE "Passive entry feature enabled; [1] = True";
CM_ SG_ 448 RFCfgReq "Change customer programmable items by RKE";
CM_ SG_ 448 RFFobNum "FOB number making the request";
CM_ SG_ 448 RFFuncReq "Basic request (RKE, PE, Remstart)";
CM_ SG_ 448 RFReq "Who's asking for the request";
CM_ SG_ 679 FOB_ExtLT "FOB is in zone exterior left";
CM_ SG_ 679 FOB_ExtRR "FOB is in zone exterior rear";
CM_ SG_ 679 FOB_ExtRT "FOB is in zone exterior right";
CM_ SG_ 679 FOB_SrchFLT "FOB search fault";
CM_ SG_ 679 FOB_SrchRslt "FOB search result";
CM_ SG_ 679 FOBinINT "FOB is in zone interior";
CM_ SG_ 679 FOBinTRUNK "FOB is in zone trunk";
CM_ SG_ 679 MsgFobBattLow "Indicates battery low on FOBIK last used for RKE purposes";
CM_ SG_ 679 MsgFobNotFnd "FOB Not Detected.";
CM_ SG_ 679 MsgKG1 "Place holder for future.";
CM_ SG_ 679 MsgKG2 "Place holder for future.";
CM_ SG_ 679 MsgNotInPark "Vehicle was not in Park.";
CM_ SG_ 656 UConnSeed1 "Character 1";
CM_ SG_ 656 UConnSeed2 "Character 2";
CM_ SG_ 656 UConnSeed3 "Character 3";
CM_ SG_ 656 UConnSeed4 "Character 4";
CM_ SG_ 929 DateTmFormat2 "Date and Time Format";
CM_ SG_ 929 WeekdayTmHour_End "Time of day during the weekday: Hours";
CM_ SG_ 929 WeekdayTmHour_Start "Time of day during the weekday: Hours";
CM_ SG_ 929 WeekdayTmMinute_End "Time of day during the weekday: Minutes";
CM_ SG_ 929 WeekdayTmMinute_Start "Time of day during the weekday: Minutes";
CM_ SG_ 929 WeekendTmHour_End "Time of day during the weekend: Hours";
CM_ SG_ 929 WeekendTmHour_Start "Time of day during the weekend: Hours";
CM_ SG_ 929 WeekendTmMinute_End "Time of day during the weekend: Minutes";
CM_ SG_ 929 WeekendTmMinute_Start "Time of day during the weekend: Minutes";
CM_ SG_ 302 STFAFtAlertPress "Selectable Tire Fill Alert Front Alert Pressure";
CM_ SG_ 302 STFARrAlertPress "Selectable Tire Fill Alert Rear Alert Pressure";
CM_ SG_ 173 CRC_SBW_ROT1 "CRC-checksum byte 1 to 4 according to SAE J1850";
CM_ SG_ 173 DrvRqShftROT "Driver requested gear shift position";
CM_ SG_ 173 MC_SBW_ROT1 "Message counter";
CM_ SG_ 173 Manual_Gate_Request "Manual gate request";
CM_ SG_ 173 ShftDispFltROT "Gear shifter display/trigger fault status - rotary shifter, 1=fault";
CM_ SG_ 173 ShftLkFltROT "Shift lock fault - rotary shifter, 1=fault";
CM_ SG_ 173 ShftSensFltROT "Shift sensor single fault - rotary shifter, 1=fault";
CM_ SG_ 177 ACC_DistSwDec "Cruise Switch: Distance Decrease pressed";
CM_ SG_ 177 ACC_DistSwInc "Cruise Switch: Distance Increase pressed";
CM_ SG_ 177 ACC_On "Cruise Switch: ACC or ESC mode pressed";
CM_ SG_ 177 AcceleratorSts "Cruise Switch: Set/Accel Pressed";
CM_ SG_ 177 CRC_CSWC_1 "CRC-checksum byte 1 to 2 according to SAE J1850";
CM_ SG_ 177 CruiseControlFailSts "Cruise Switch: Implausible State=1";
CM_ SG_ 177 CruiseControlOnOffSts "Cruise Switch: On/Off  Pressed";
CM_ SG_ 177 CrusCnclSwitch "Cruise Switch: Cancel Pressed";
CM_ SG_ 177 DeceleratorSts "Cruise Switch: Coast or Set/Decel Pressed";
CM_ SG_ 177 MC_CSWC_1 "Message counter";
CM_ SG_ 177 ResumeSwitch "Cruise Switch: Resume Pressed";
CM_ SG_ 177 SpeedLimiterOnOffSts "Cruise Switch:Speed Limiter On/Off Pressed";
CM_ SG_ 35 CRC_STW_Angle_STAT "CRC-checksum byte 1 to 7 according to SAE J1850";
CM_ SG_ 35 LRW "Steering wheel angle";
CM_ SG_ 35 LRWS_ST "Steering wheel angle sensor status";
CM_ SG_ 35 LRW_PLRTY "Steering angle polarity (0=ISO 8855 Polarity and CCW = Positive)";
CM_ SG_ 35 LRW_RHP "Steering wheel angle remainder high precision";
CM_ SG_ 35 MC_STW_Angle_STAT "Message counter";
CM_ SG_ 35 Pad_Shft "Paddle Shift";
CM_ SG_ 35 VLRW "Delta steering wheel angle";
CM_ SG_ 1577 SD_RS_AHLM "Response on Event - light";
CM_ SG_ 1546 SD_RS_ASBS "Response on Event - light";
CM_ SG_ 1596 SD_RS_BSMO "Response on Event - light";
CM_ SG_ 1537 SD_RS_CBC "Response on Event - light";
CM_ SG_ 1555 SD_RS_DASM "Response on Event - light";
CM_ SG_ 1553 SD_RS_DPDM "Response on Event - light";
CM_ SG_ 1547 SD_RS_DTCM "Response on Event - light";
CM_ SG_ 1592 SD_RS_ECM "Response on Event - light";
BA_DEF_ BO_  "App-Botschaft" ENUM  "nein","ja";
BA_DEF_ BO_  "CanMsgMinLen" INT 0 8;
BA_DEF_ BO_  "DiagRequest" ENUM  "nein","ja";
BA_DEF_ BO_  "DiagResponse" ENUM  "nein","ja";
BA_DEF_ BO_  "DiagState" ENUM  "nein","ja";
BA_DEF_ BO_  "GenMsgCycleTime" INT 0 65535;
BA_DEF_ BO_  "GenMsgCycleTimeActive" INT 0 65535;
BA_DEF_ BO_  "GenMsgDelayTime" INT 0 65535;
BA_DEF_ BO_  "GenMsgNrOfRepetitions" INT 0 65535;
BA_DEF_ BO_  "GenMsgSendType" ENUM  "cyclicX","spontanX","cyclicIfActiveX","spontanWithDelay","cyclicAndSpontanX","cyclicAndSpontanWithDelay","spontanWithRepitition","cyclicIfActiveAndSpontanWD","cyclicIfActiveFast","cyclicWithRepeatOnDemand","none";
BA_DEF_ BO_  "GenMsgStartDelayTime" INT 0 65535;
BA_DEF_ BO_  "GenMsgStartValue" STRING ;
BA_DEF_ BO_  "NWM-Botschaft" ENUM  "nein","ja";
BA_DEF_ BO_  "TpTxIndex" INT 0 99;
BA_DEF_ SG_  "FlexKomComment" STRING ;
BA_DEF_ SG_  "FlexKomIsMotorola" ENUM  "nein","ja";
BA_DEF_ SG_  "FlexKomSID" INT 0 2147483647;
BA_DEF_ SG_  "FlexKomSigLaenge" INT 0 64;
BA_DEF_ SG_  "FlexKomSigName" STRING ;
BA_DEF_ SG_  "FlexKomSigStartPos" INT 0 63;
BA_DEF_ SG_  "FlexKomSigStartValue" STRING ;
BA_DEF_ SG_  "GenSigCycleTime" INT 0 65535;
BA_DEF_ SG_  "GenSigCycleTimeActive" INT 0 65535;
BA_DEF_ SG_  "GenSigSendType" ENUM  "cyclicX","spontanX","cyclicIfActiveX","spontanWithDelay","cyclicAndSpontanX","cyclicAndSpontanWithDelay","spontanWithRepitition","cyclicIfActiveAndSpontanWD","cyclicIfActiveFast","cyclicWithRepeatOnDemand","none";
BA_DEF_ SG_  "GenSigSNA" STRING ;
BA_DEF_ SG_  "GenSigStartValue" HEX 0 2147483648;
BA_DEF_ SG_  "GenSigTimeout_AHLM" INT 0 65535;
BA_DEF_ SG_  "GenSigTimeout_ASBS" INT 0 65535;
BA_DEF_ SG_  "GenSigTimeout_CBC" INT 0 65535;
BA_DEF_ SG_  "GenSigTimeout_DPDM" INT 0 65535;
BA_DEF_ SG_  "GenSigTimeout_DTCM" INT 0 65535;
BA_DEF_ SG_  "GenSigTimeout_EHPS" INT 0 65535;
BA_DEF_ SG_  "GenSigTimeout_ESC" INT 0 65535;
BA_DEF_ SG_  "GenSigTimeout_ESL" INT 0 65535;
BA_DEF_ SG_  "GenSigTimeout_ESM" INT 0 65535;
BA_DEF_ SG_  "GenSigTimeout_ETM" INT 0 65535;
BA_DEF_ SG_  "GenSigTimeout_IC" INT 0 65535;
BA_DEF_ SG_  "GenSigTimeout_OCM" INT 0 65535;
BA_DEF_ SG_  "GenSigTimeout_ORC" INT 0 65535;
BA_DEF_ SG_  "GenSigTimeout_PTS" INT 0 65535;
BA_DEF_ SG_  "GenSigTimeout_RF_HUB" INT 0 65535;
BA_DEF_ SG_  "GenSigTimeout_SCCM" INT 0 65535;
BA_DEF_ SG_  "GenSigTimeout_TBM" INT 0 65535;
BA_DEF_ SG_  "GenSigTimeout_TCM" INT 0 65535;
BA_DEF_ SG_  "GenSigTimeout_TPM" INT 0 65535;
BA_DEF_ SG_  "RID" STRING ;
BA_DEF_ SG_  "SystemSignalLongSymbol" STRING ;
BA_DEF_DEF_  "App-Botschaft" "nein";
BA_DEF_DEF_  "CanMsgMinLen" 0;
BA_DEF_DEF_  "DiagRequest" "nein";
BA_DEF_DEF_  "DiagResponse" "nein";
BA_DEF_DEF_  "DiagState" "nein";
BA_DEF_DEF_  "GenMsgCycleTime" 0;
BA_DEF_DEF_  "GenMsgCycleTimeActive" 0;
BA_DEF_DEF_  "GenMsgDelayTime" 0;
BA_DEF_DEF_  "GenMsgNrOfRepetitions" 0;
BA_DEF_DEF_  "GenMsgSendType" "cyclicX";
BA_DEF_DEF_  "GenMsgStartDelayTime" 0;
BA_DEF_DEF_  "GenMsgStartValue" "";
BA_DEF_DEF_  "NWM-Botschaft" "nein";
BA_DEF_DEF_  "TpTxIndex" 0;
BA_DEF_DEF_  "FlexKomComment" "";
BA_DEF_DEF_  "FlexKomIsMotorola" "nein";
BA_DEF_DEF_  "FlexKomSID" 0;
BA_DEF_DEF_  "FlexKomSigLaenge" 0;
BA_DEF_DEF_  "FlexKomSigName" "";
BA_DEF_DEF_  "FlexKomSigStartPos" 0;
BA_DEF_DEF_  "FlexKomSigStartValue" "";
BA_DEF_DEF_  "GenSigCycleTime" 0;
BA_DEF_DEF_  "GenSigCycleTimeActive" 0;
BA_DEF_DEF_  "GenSigSendType" "cyclicX";
BA_DEF_DEF_  "GenSigSNA" "";
BA_DEF_DEF_  "GenSigStartValue" 0;
BA_DEF_DEF_  "GenSigTimeout_AHLM" 0;
BA_DEF_DEF_  "GenSigTimeout_ASBS" 0;
BA_DEF_DEF_  "GenSigTimeout_CBC" 0;
BA_DEF_DEF_  "GenSigTimeout_DPDM" 0;
BA_DEF_DEF_  "GenSigTimeout_DTCM" 0;
BA_DEF_DEF_  "GenSigTimeout_EHPS" 0;
BA_DEF_DEF_  "GenSigTimeout_ESC" 0;
BA_DEF_DEF_  "GenSigTimeout_ESL" 0;
BA_DEF_DEF_  "GenSigTimeout_ESM" 0;
BA_DEF_DEF_  "GenSigTimeout_ETM" 0;
BA_DEF_DEF_  "GenSigTimeout_IC" 0;
BA_DEF_DEF_  "GenSigTimeout_OCM" 0;
BA_DEF_DEF_  "GenSigTimeout_ORC" 0;
BA_DEF_DEF_  "GenSigTimeout_PTS" 0;
BA_DEF_DEF_  "GenSigTimeout_RF_HUB" 0;
BA_DEF_DEF_  "GenSigTimeout_SCCM" 0;
BA_DEF_DEF_  "GenSigTimeout_TBM" 0;
BA_DEF_DEF_  "GenSigTimeout_TCM" 0;
BA_DEF_DEF_  "GenSigTimeout_TPM" 0;
BA_DEF_DEF_  "RID" "";
BA_DEF_DEF_  "SystemSignalLongSymbol" "";
BA_ "NWM-Botschaft" BO_ 1026 1;
BA_ "GenMsgStartValue" BO_ 1026 "FFFFFFFF000000FFh";
BA_ "GenMsgSendType" BO_ 1026 1;
BA_ "GenMsgNrOfRepetitions" BO_ 1026 2;
BA_ "GenMsgDelayTime" BO_ 1026 20;
BA_ "NWM-Botschaft" BO_ 1024 1;
BA_ "GenMsgStartValue" BO_ 1024 "FFFFFFFF000000FFh";
BA_ "GenMsgSendType" BO_ 1024 1;
BA_ "GenMsgNrOfRepetitions" BO_ 1024 2;
BA_ "GenMsgDelayTime" BO_ 1024 20;
BA_ "NWM-Botschaft" BO_ 1033 1;
BA_ "GenMsgStartValue" BO_ 1033 "FFFFFFFF000000FFh";
BA_ "GenMsgSendType" BO_ 1033 1;
BA_ "GenMsgNrOfRepetitions" BO_ 1033 2;
BA_ "GenMsgDelayTime" BO_ 1033 20;
BA_ "NWM-Botschaft" BO_ 1059 1;
BA_ "GenMsgStartValue" BO_ 1059 "FFFFFFFF000000FFh";
BA_ "GenMsgSendType" BO_ 1059 1;
BA_ "GenMsgNrOfRepetitions" BO_ 1059 2;
BA_ "GenMsgDelayTime" BO_ 1059 20;
BA_ "NWM-Botschaft" BO_ 1027 1;
BA_ "GenMsgStartValue" BO_ 1027 "FFFFFFFF000000FFh";
BA_ "GenMsgSendType" BO_ 1027 1;
BA_ "GenMsgNrOfRepetitions" BO_ 1027 2;
BA_ "GenMsgDelayTime" BO_ 1027 20;
BA_ "GenMsgStartValue" BO_ 601 "0F0F0000000000FFh";
BA_ "GenMsgSendType" BO_ 601 5;
BA_ "GenMsgNrOfRepetitions" BO_ 601 2;
BA_ "GenMsgDelayTime" BO_ 601 20;
BA_ "GenMsgCycleTime" BO_ 601 1000;
BA_ "GenMsgStartValue" BO_ 464 "44E70F0F00070000h";
BA_ "GenMsgSendType" BO_ 464 5;
BA_ "GenMsgNrOfRepetitions" BO_ 464 2;
BA_ "GenMsgDelayTime" BO_ 464 20;
BA_ "GenMsgCycleTime" BO_ 464 1000;
BA_ "GenMsgStartValue" BO_ 466 "0000h";
BA_ "GenMsgSendType" BO_ 466 2;
BA_ "GenMsgNrOfRepetitions" BO_ 466 2;
BA_ "GenMsgDelayTime" BO_ 466 20;
BA_ "GenMsgCycleTimeActive" BO_ 466 20;
BA_ "GenMsgStartValue" BO_ 599 "FF0F000000000000h";
BA_ "GenMsgSendType" BO_ 599 5;
BA_ "GenMsgNrOfRepetitions" BO_ 599 2;
BA_ "GenMsgDelayTime" BO_ 599 20;
BA_ "GenMsgCycleTime" BO_ 599 1000;
BA_ "GenMsgStartValue" BO_ 469 "0000000000000000h";
BA_ "GenMsgSendType" BO_ 469 5;
BA_ "GenMsgNrOfRepetitions" BO_ 469 2;
BA_ "GenMsgDelayTime" BO_ 469 20;
BA_ "GenMsgCycleTime" BO_ 469 250;
BA_ "GenMsgStartValue" BO_ 43 "000000000FFF00FFh";
BA_ "GenMsgNrOfRepetitions" BO_ 43 2;
BA_ "GenMsgDelayTime" BO_ 43 20;
BA_ "GenMsgCycleTime" BO_ 43 10;
BA_ "GenMsgStartValue" BO_ 305 "0000000000000000h";
BA_ "GenMsgSendType" BO_ 305 9;
BA_ "GenMsgNrOfRepetitions" BO_ 305 3;
BA_ "GenMsgDelayTime" BO_ 305 100;
BA_ "GenMsgCycleTime" BO_ 305 100;
BA_ "GenMsgStartValue" BO_ 334 "00FFFFFFFFFFFFFFh";
BA_ "GenMsgNrOfRepetitions" BO_ 334 2;
BA_ "GenMsgDelayTime" BO_ 334 20;
BA_ "GenMsgCycleTime" BO_ 334 100;
BA_ "GenMsgStartValue" BO_ 333 "FFFFFFFF0000FF00h";
BA_ "GenMsgNrOfRepetitions" BO_ 333 2;
BA_ "GenMsgDelayTime" BO_ 333 20;
BA_ "GenMsgCycleTime" BO_ 333 100;
BA_ "GenMsgStartValue" BO_ 584 "0000FFFFFF03FFFFh";
BA_ "GenMsgStartDelayTime" BO_ 584 70;
BA_ "GenMsgSendType" BO_ 584 5;
BA_ "GenMsgNrOfRepetitions" BO_ 584 2;
BA_ "GenMsgDelayTime" BO_ 584 20;
BA_ "GenMsgCycleTime" BO_ 584 500;
BA_ "GenMsgStartValue" BO_ 502 "00F0F0F0F0F0F000h";
BA_ "GenMsgSendType" BO_ 502 5;
BA_ "GenMsgNrOfRepetitions" BO_ 502 2;
BA_ "GenMsgDelayTime" BO_ 502 20;
BA_ "GenMsgCycleTime" BO_ 502 500;
BA_ "GenMsgStartValue" BO_ 489 "FF001400000004FFh";
BA_ "GenMsgSendType" BO_ 489 5;
BA_ "GenMsgNrOfRepetitions" BO_ 489 2;
BA_ "GenMsgDelayTime" BO_ 489 20;
BA_ "GenMsgCycleTime" BO_ 489 500;
BA_ "GenMsgStartValue" BO_ 825 "0050h";
BA_ "GenMsgSendType" BO_ 825 5;
BA_ "GenMsgNrOfRepetitions" BO_ 825 2;
BA_ "GenMsgDelayTime" BO_ 825 20;
BA_ "GenMsgCycleTime" BO_ 825 500;
BA_ "GenMsgStartValue" BO_ 297 "1C000000h";
BA_ "GenMsgSendType" BO_ 297 5;
BA_ "GenMsgNrOfRepetitions" BO_ 297 2;
BA_ "GenMsgDelayTime" BO_ 297 20;
BA_ "GenMsgCycleTime" BO_ 297 100;
BA_ "GenMsgStartValue" BO_ 448 "000000000000h";
BA_ "GenMsgSendType" BO_ 448 5;
BA_ "GenMsgNrOfRepetitions" BO_ 448 2;
BA_ "GenMsgDelayTime" BO_ 448 20;
BA_ "GenMsgCycleTime" BO_ 448 200;
BA_ "GenMsgStartValue" BO_ 679 "0000000000000000h";
BA_ "GenMsgSendType" BO_ 679 5;
BA_ "GenMsgNrOfRepetitions" BO_ 679 2;
BA_ "GenMsgDelayTime" BO_ 679 20;
BA_ "GenMsgCycleTime" BO_ 679 1000;
BA_ "GenMsgStartValue" BO_ 656 "00000000h";
BA_ "GenMsgSendType" BO_ 656 1;
BA_ "GenMsgNrOfRepetitions" BO_ 656 2;
BA_ "GenMsgDelayTime" BO_ 656 20;
BA_ "GenMsgStartValue" BO_ 929 "07FFFFFFFF004000h";
BA_ "GenMsgSendType" BO_ 929 5;
BA_ "GenMsgNrOfRepetitions" BO_ 929 2;
BA_ "GenMsgDelayTime" BO_ 929 20;
BA_ "GenMsgCycleTime" BO_ 929 1000;
BA_ "GenMsgStartValue" BO_ 302 "FFFF000032000000h";
BA_ "GenMsgSendType" BO_ 302 1;
BA_ "GenMsgNrOfRepetitions" BO_ 302 2;
BA_ "GenMsgDelayTime" BO_ 302 20;
BA_ "GenMsgStartValue" BO_ 173 "00000000FFh";
BA_ "GenMsgNrOfRepetitions" BO_ 173 2;
BA_ "GenMsgDelayTime" BO_ 173 20;
BA_ "GenMsgCycleTime" BO_ 173 20;
BA_ "GenMsgStartValue" BO_ 177 "0000FFh";
BA_ "GenMsgSendType" BO_ 177 1;
BA_ "GenMsgNrOfRepetitions" BO_ 177 2;
BA_ "GenMsgDelayTime" BO_ 177 20;
BA_ "GenMsgStartValue" BO_ 35 "3FFF3FFF030000FFh";
BA_ "GenMsgNrOfRepetitions" BO_ 35 2;
BA_ "GenMsgDelayTime" BO_ 35 20;
BA_ "GenMsgCycleTime" BO_ 35 10;
BA_ "GenMsgStartValue" BO_ 1577 "0000000000000000h";
BA_ "GenMsgStartDelayTime" BO_ 1577 800;
BA_ "GenMsgSendType" BO_ 1577 9;
BA_ "GenMsgDelayTime" BO_ 1577 200;
BA_ "GenMsgCycleTime" BO_ 1577 200;
BA_ "GenMsgStartValue" BO_ 1546 "0000000000000000h";
BA_ "GenMsgStartDelayTime" BO_ 1546 800;
BA_ "GenMsgSendType" BO_ 1546 9;
BA_ "GenMsgDelayTime" BO_ 1546 200;
BA_ "GenMsgCycleTime" BO_ 1546 200;
BA_ "GenMsgStartValue" BO_ 1596 "0000000000000000h";
BA_ "GenMsgStartDelayTime" BO_ 1596 870;
BA_ "GenMsgSendType" BO_ 1596 9;
BA_ "GenMsgDelayTime" BO_ 1596 200;
BA_ "GenMsgCycleTime" BO_ 1596 200;
BA_ "GenMsgStartValue" BO_ 1537 "0000000000000000h";
BA_ "GenMsgStartDelayTime" BO_ 1537 810;
BA_ "GenMsgSendType" BO_ 1537 9;
BA_ "GenMsgDelayTime" BO_ 1537 200;
BA_ "GenMsgCycleTime" BO_ 1537 200;
BA_ "GenMsgStartValue" BO_ 1555 "0000000000000000h";
BA_ "GenMsgStartDelayTime" BO_ 1555 800;
BA_ "GenMsgSendType" BO_ 1555 9;
BA_ "GenMsgDelayTime" BO_ 1555 200;
BA_ "GenMsgCycleTime" BO_ 1555 200;
BA_ "GenMsgStartValue" BO_ 1553 "0000000000000000h";
BA_ "GenMsgStartDelayTime" BO_ 1553 800;
BA_ "GenMsgSendType" BO_ 1553 9;
BA_ "GenMsgDelayTime" BO_ 1553 200;
BA_ "GenMsgCycleTime" BO_ 1553 200;
BA_ "GenMsgStartValue" BO_ 1547 "0000000000000000h";
BA_ "GenMsgStartDelayTime" BO_ 1547 800;
BA_ "GenMsgSendType" BO_ 1547 9;
BA_ "GenMsgDelayTime" BO_ 1547 200;
BA_ "GenMsgCycleTime" BO_ 1547 200;
BA_ "GenMsgStartValue" BO_ 1592 "0000000000000000h";
BA_ "GenMsgStartDelayTime" BO_ 1592 800;
BA_ "GenMsgSendType" BO_ 1592 9;
BA_ "GenMsgDelayTime" BO_ 1592 200;
BA_ "GenMsgCycleTime" BO_ 1592 200;
BA_ "GenSigSNA" SG_ 1026 Awake_Diag_Actv "0h";
BA_ "GenSigSendType" SG_ 1026 Awake_Diag_Actv 1;
BA_ "FlexKomSigStartValue" SG_ 1026 Awake_Diag_Actv "000000h";
BA_ "FlexKomSigStartPos" SG_ 1026 Awake_Diag_Actv 39;
BA_ "FlexKomSigName" SG_ 1026 Awake_Diag_Actv "Awake_IC";
BA_ "FlexKomSigLaenge" SG_ 1026 Awake_Diag_Actv 24;
BA_ "FlexKomSID" SG_ 1026 Awake_Diag_Actv 512;
BA_ "FlexKomIsMotorola" SG_ 1026 Awake_Diag_Actv 1;
BA_ "FlexKomComment" SG_ 1026 Awake_Diag_Actv "Mode 15 of NM_Ud_Srv";
BA_ "GenSigSNA" SG_ 1026 Awake_NwSt "0h";
BA_ "GenSigSendType" SG_ 1026 Awake_NwSt 1;
BA_ "FlexKomSigStartValue" SG_ 1026 Awake_NwSt "000000h";
BA_ "FlexKomSigStartPos" SG_ 1026 Awake_NwSt 39;
BA_ "FlexKomSigName" SG_ 1026 Awake_NwSt "Awake_IC";
BA_ "FlexKomSigLaenge" SG_ 1026 Awake_NwSt 24;
BA_ "FlexKomSID" SG_ 1026 Awake_NwSt 512;
BA_ "FlexKomIsMotorola" SG_ 1026 Awake_NwSt 1;
BA_ "FlexKomComment" SG_ 1026 Awake_NwSt "Mode 15 of NM_Ud_Srv";
BA_ "GenSigStartValue" SG_ 1026 NM_Mode 255;
BA_ "GenSigSNA" SG_ 1026 NM_Mode "FFh";
BA_ "GenSigSendType" SG_ 1026 NM_Mode 1;
BA_ "FlexKomSigStartValue" SG_ 1026 NM_Mode "FFFFFFFFh";
BA_ "FlexKomSigStartPos" SG_ 1026 NM_Mode 7;
BA_ "FlexKomSigName" SG_ 1026 NM_Mode "NM";
BA_ "FlexKomSigLaenge" SG_ 1026 NM_Mode 32;
BA_ "FlexKomSID" SG_ 1026 NM_Mode 472;
BA_ "FlexKomIsMotorola" SG_ 1026 NM_Mode 1;
BA_ "FlexKomComment" SG_ 1026 NM_Mode "Network management state";
BA_ "GenSigStartValue" SG_ 1026 NM_Sleep_Ack 1;
BA_ "GenSigSNA" SG_ 1026 NM_Sleep_Ack "1h";
BA_ "GenSigSendType" SG_ 1026 NM_Sleep_Ack 1;
BA_ "FlexKomSigStartValue" SG_ 1026 NM_Sleep_Ack "FFFFFFFFh";
BA_ "FlexKomSigStartPos" SG_ 1026 NM_Sleep_Ack 7;
BA_ "FlexKomSigName" SG_ 1026 NM_Sleep_Ack "NM";
BA_ "FlexKomSigLaenge" SG_ 1026 NM_Sleep_Ack 32;
BA_ "FlexKomSID" SG_ 1026 NM_Sleep_Ack 472;
BA_ "FlexKomIsMotorola" SG_ 1026 NM_Sleep_Ack 1;
BA_ "FlexKomComment" SG_ 1026 NM_Sleep_Ack "Network management state";
BA_ "GenSigStartValue" SG_ 1026 NM_Sleep_Ind 1;
BA_ "GenSigSNA" SG_ 1026 NM_Sleep_Ind "1h";
BA_ "GenSigSendType" SG_ 1026 NM_Sleep_Ind 1;
BA_ "FlexKomSigStartValue" SG_ 1026 NM_Sleep_Ind "FFFFFFFFh";
BA_ "FlexKomSigStartPos" SG_ 1026 NM_Sleep_Ind 7;
BA_ "FlexKomSigName" SG_ 1026 NM_Sleep_Ind "NM";
BA_ "FlexKomSigLaenge" SG_ 1026 NM_Sleep_Ind 32;
BA_ "FlexKomSID" SG_ 1026 NM_Sleep_Ind 472;
BA_ "FlexKomIsMotorola" SG_ 1026 NM_Sleep_Ind 1;
BA_ "FlexKomComment" SG_ 1026 NM_Sleep_Ind "Network management state";
BA_ "GenSigStartValue" SG_ 1026 NM_Successor 255;
BA_ "GenSigSNA" SG_ 1026 NM_Successor "FFh";
BA_ "GenSigSendType" SG_ 1026 NM_Successor 1;
BA_ "FlexKomSigStartValue" SG_ 1026 NM_Successor "FFFFFFFFh";
BA_ "FlexKomSigStartPos" SG_ 1026 NM_Successor 7;
BA_ "FlexKomSigName" SG_ 1026 NM_Successor "NM";
BA_ "FlexKomSigLaenge" SG_ 1026 NM_Successor 32;
BA_ "FlexKomSID" SG_ 1026 NM_Successor 472;
BA_ "FlexKomIsMotorola" SG_ 1026 NM_Successor 1;
BA_ "FlexKomComment" SG_ 1026 NM_Successor "Network management state";
BA_ "GenSigStartValue" SG_ 1026 NM_Ud_Launch 63;
BA_ "GenSigSNA" SG_ 1026 NM_Ud_Launch "3Fh";
BA_ "GenSigSendType" SG_ 1026 NM_Ud_Launch 1;
BA_ "FlexKomSigStartValue" SG_ 1026 NM_Ud_Launch "FFFFFFFFh";
BA_ "FlexKomSigStartPos" SG_ 1026 NM_Ud_Launch 7;
BA_ "FlexKomSigName" SG_ 1026 NM_Ud_Launch "NM";
BA_ "FlexKomSigLaenge" SG_ 1026 NM_Ud_Launch 32;
BA_ "FlexKomSID" SG_ 1026 NM_Ud_Launch 472;
BA_ "FlexKomIsMotorola" SG_ 1026 NM_Ud_Launch 1;
BA_ "FlexKomComment" SG_ 1026 NM_Ud_Launch "Network management state";
BA_ "GenSigStartValue" SG_ 1026 NM_Ud_Srv 255;
BA_ "GenSigSNA" SG_ 1026 NM_Ud_Srv "FFh";
BA_ "GenSigSendType" SG_ 1026 NM_Ud_Srv 1;
BA_ "FlexKomSigStartValue" SG_ 1026 NM_Ud_Srv "FFFFFFFFh";
BA_ "FlexKomSigStartPos" SG_ 1026 NM_Ud_Srv 7;
BA_ "FlexKomSigName" SG_ 1026 NM_Ud_Srv "NM";
BA_ "FlexKomSigLaenge" SG_ 1026 NM_Ud_Srv 32;
BA_ "FlexKomSID" SG_ 1026 NM_Ud_Srv 472;
BA_ "FlexKomIsMotorola" SG_ 1026 NM_Ud_Srv 1;
BA_ "FlexKomComment" SG_ 1026 NM_Ud_Srv "Network management state";
BA_ "GenSigStartValue" SG_ 1026 Nw_Id 255;
BA_ "GenSigSNA" SG_ 1026 Nw_Id "FFh";
BA_ "GenSigSendType" SG_ 1026 Nw_Id 1;
BA_ "FlexKomSigStartValue" SG_ 1026 Nw_Id "FFh";
BA_ "FlexKomSigStartPos" SG_ 1026 Nw_Id 63;
BA_ "FlexKomSigName" SG_ 1026 Nw_Id "Nw_Id";
BA_ "FlexKomSigLaenge" SG_ 1026 Nw_Id 8;
BA_ "FlexKomSID" SG_ 1026 Nw_Id 535;
BA_ "FlexKomIsMotorola" SG_ 1026 Nw_Id 1;
BA_ "FlexKomComment" SG_ 1026 Nw_Id "Network identification no.";
BA_ "GenSigStartValue" SG_ 1026 WakeupCnt 255;
BA_ "GenSigSNA" SG_ 1026 WakeupCnt "FFh";
BA_ "GenSigSendType" SG_ 1026 WakeupCnt 1;
BA_ "FlexKomSigStartValue" SG_ 1026 WakeupCnt "FFFF00h";
BA_ "FlexKomSigStartPos" SG_ 1026 WakeupCnt 39;
BA_ "FlexKomSigName" SG_ 1026 WakeupCnt "Wakeup_IC";
BA_ "FlexKomSigLaenge" SG_ 1026 WakeupCnt 24;
BA_ "FlexKomSID" SG_ 1026 WakeupCnt 482;
BA_ "FlexKomIsMotorola" SG_ 1026 WakeupCnt 1;
BA_ "FlexKomComment" SG_ 1026 WakeupCnt "Mode 2 of NM_Ud_Srv";
BA_ "GenSigStartValue" SG_ 1026 WakeupRsn_IC 255;
BA_ "GenSigSNA" SG_ 1026 WakeupRsn_IC "FFh";
BA_ "GenSigSendType" SG_ 1026 WakeupRsn_IC 1;
BA_ "FlexKomSigStartValue" SG_ 1026 WakeupRsn_IC "FFFF00h";
BA_ "FlexKomSigStartPos" SG_ 1026 WakeupRsn_IC 39;
BA_ "FlexKomSigName" SG_ 1026 WakeupRsn_IC "Wakeup_IC";
BA_ "FlexKomSigLaenge" SG_ 1026 WakeupRsn_IC 24;
BA_ "FlexKomSID" SG_ 1026 WakeupRsn_IC 482;
BA_ "FlexKomIsMotorola" SG_ 1026 WakeupRsn_IC 1;
BA_ "FlexKomComment" SG_ 1026 WakeupRsn_IC "Mode 2 of NM_Ud_Srv";
BA_ "GenSigSNA" SG_ 1024 Awake_Diag_Actv "0h";
BA_ "GenSigSendType" SG_ 1024 Awake_Diag_Actv 1;
BA_ "FlexKomSigStartValue" SG_ 1024 Awake_Diag_Actv "000000h";
BA_ "FlexKomSigStartPos" SG_ 1024 Awake_Diag_Actv 39;
BA_ "FlexKomSigName" SG_ 1024 Awake_Diag_Actv "Awake_RF_HUB";
BA_ "FlexKomSigLaenge" SG_ 1024 Awake_Diag_Actv 24;
BA_ "FlexKomSID" SG_ 1024 Awake_Diag_Actv 619;
BA_ "FlexKomIsMotorola" SG_ 1024 Awake_Diag_Actv 1;
BA_ "FlexKomComment" SG_ 1024 Awake_Diag_Actv "Mode 15 of NM_Ud_Srv";
BA_ "GenSigSNA" SG_ 1024 Awake_NwSt "0h";
BA_ "GenSigSendType" SG_ 1024 Awake_NwSt 1;
BA_ "FlexKomSigStartValue" SG_ 1024 Awake_NwSt "000000h";
BA_ "FlexKomSigStartPos" SG_ 1024 Awake_NwSt 39;
BA_ "FlexKomSigName" SG_ 1024 Awake_NwSt "Awake_RF_HUB";
BA_ "FlexKomSigLaenge" SG_ 1024 Awake_NwSt 24;
BA_ "FlexKomSID" SG_ 1024 Awake_NwSt 619;
BA_ "FlexKomIsMotorola" SG_ 1024 Awake_NwSt 1;
BA_ "FlexKomComment" SG_ 1024 Awake_NwSt "Mode 15 of NM_Ud_Srv";
BA_ "GenSigStartValue" SG_ 1024 NM_Mode 255;
BA_ "GenSigSNA" SG_ 1024 NM_Mode "FFh";
BA_ "GenSigSendType" SG_ 1024 NM_Mode 1;
BA_ "FlexKomSigStartValue" SG_ 1024 NM_Mode "FFFFFFFFh";
BA_ "FlexKomSigStartPos" SG_ 1024 NM_Mode 7;
BA_ "FlexKomSigName" SG_ 1024 NM_Mode "NM";
BA_ "FlexKomSigLaenge" SG_ 1024 NM_Mode 32;
BA_ "FlexKomSID" SG_ 1024 NM_Mode 472;
BA_ "FlexKomIsMotorola" SG_ 1024 NM_Mode 1;
BA_ "FlexKomComment" SG_ 1024 NM_Mode "Network management state";
BA_ "GenSigStartValue" SG_ 1024 NM_Sleep_Ack 1;
BA_ "GenSigSNA" SG_ 1024 NM_Sleep_Ack "1h";
BA_ "GenSigSendType" SG_ 1024 NM_Sleep_Ack 1;
BA_ "FlexKomSigStartValue" SG_ 1024 NM_Sleep_Ack "FFFFFFFFh";
BA_ "FlexKomSigStartPos" SG_ 1024 NM_Sleep_Ack 7;
BA_ "FlexKomSigName" SG_ 1024 NM_Sleep_Ack "NM";
BA_ "FlexKomSigLaenge" SG_ 1024 NM_Sleep_Ack 32;
BA_ "FlexKomSID" SG_ 1024 NM_Sleep_Ack 472;
BA_ "FlexKomIsMotorola" SG_ 1024 NM_Sleep_Ack 1;
BA_ "FlexKomComment" SG_ 1024 NM_Sleep_Ack "Network management state";
BA_ "GenSigStartValue" SG_ 1024 NM_Sleep_Ind 1;
BA_ "GenSigSNA" SG_ 1024 NM_Sleep_Ind "1h";
BA_ "GenSigSendType" SG_ 1024 NM_Sleep_Ind 1;
BA_ "FlexKomSigStartValue" SG_ 1024 NM_Sleep_Ind "FFFFFFFFh";
BA_ "FlexKomSigStartPos" SG_ 1024 NM_Sleep_Ind 7;
BA_ "FlexKomSigName" SG_ 1024 NM_Sleep_Ind "NM";
BA_ "FlexKomSigLaenge" SG_ 1024 NM_Sleep_Ind 32;
BA_ "FlexKomSID" SG_ 1024 NM_Sleep_Ind 472;
BA_ "FlexKomIsMotorola" SG_ 1024 NM_Sleep_Ind 1;
BA_ "FlexKomComment" SG_ 1024 NM_Sleep_Ind "Network management state";
BA_ "GenSigStartValue" SG_ 1024 NM_Successor 255;
BA_ "GenSigSNA" SG_ 1024 NM_Successor "FFh";
BA_ "GenSigSendType" SG_ 1024 NM_Successor 1;
BA_ "FlexKomSigStartValue" SG_ 1024 NM_Successor "FFFFFFFFh";
BA_ "FlexKomSigStartPos" SG_ 1024 NM_Successor 7;
BA_ "FlexKomSigName" SG_ 1024 NM_Successor "NM";
BA_ "FlexKomSigLaenge" SG_ 1024 NM_Successor 32;
BA_ "FlexKomSID" SG_ 1024 NM_Successor 472;
BA_ "FlexKomIsMotorola" SG_ 1024 NM_Successor 1;
BA_ "FlexKomComment" SG_ 1024 NM_Successor "Network management state";
BA_ "GenSigStartValue" SG_ 1024 NM_Ud_Launch 63;
BA_ "GenSigSNA" SG_ 1024 NM_Ud_Launch "3Fh";
BA_ "GenSigSendType" SG_ 1024 NM_Ud_Launch 1;
BA_ "FlexKomSigStartValue" SG_ 1024 NM_Ud_Launch "FFFFFFFFh";
BA_ "FlexKomSigStartPos" SG_ 1024 NM_Ud_Launch 7;
BA_ "FlexKomSigName" SG_ 1024 NM_Ud_Launch "NM";
BA_ "FlexKomSigLaenge" SG_ 1024 NM_Ud_Launch 32;
BA_ "FlexKomSID" SG_ 1024 NM_Ud_Launch 472;
BA_ "FlexKomIsMotorola" SG_ 1024 NM_Ud_Launch 1;
BA_ "FlexKomComment" SG_ 1024 NM_Ud_Launch "Network management state";
BA_ "GenSigStartValue" SG_ 1024 NM_Ud_Srv 255;
BA_ "GenSigSNA" SG_ 1024 NM_Ud_Srv "FFh";
BA_ "GenSigSendType" SG_ 1024 NM_Ud_Srv 1;
BA_ "FlexKomSigStartValue" SG_ 1024 NM_Ud_Srv "FFFFFFFFh";
BA_ "FlexKomSigStartPos" SG_ 1024 NM_Ud_Srv 7;
BA_ "FlexKomSigName" SG_ 1024 NM_Ud_Srv "NM";
BA_ "FlexKomSigLaenge" SG_ 1024 NM_Ud_Srv 32;
BA_ "FlexKomSID" SG_ 1024 NM_Ud_Srv 472;
BA_ "FlexKomIsMotorola" SG_ 1024 NM_Ud_Srv 1;
BA_ "FlexKomComment" SG_ 1024 NM_Ud_Srv "Network management state";
BA_ "GenSigStartValue" SG_ 1024 Nw_Id 255;
BA_ "GenSigSNA" SG_ 1024 Nw_Id "FFh";
BA_ "GenSigSendType" SG_ 1024 Nw_Id 1;
BA_ "FlexKomSigStartValue" SG_ 1024 Nw_Id "FFh";
BA_ "FlexKomSigStartPos" SG_ 1024 Nw_Id 63;
BA_ "FlexKomSigName" SG_ 1024 Nw_Id "Nw_Id";
BA_ "FlexKomSigLaenge" SG_ 1024 Nw_Id 8;
BA_ "FlexKomSID" SG_ 1024 Nw_Id 535;
BA_ "FlexKomIsMotorola" SG_ 1024 Nw_Id 1;
BA_ "FlexKomComment" SG_ 1024 Nw_Id "Network identification no.";
BA_ "GenSigStartValue" SG_ 1024 WakeupCnt 255;
BA_ "GenSigSNA" SG_ 1024 WakeupCnt "FFh";
BA_ "GenSigSendType" SG_ 1024 WakeupCnt 1;
BA_ "FlexKomSigStartValue" SG_ 1024 WakeupCnt "FFFF00h";
BA_ "FlexKomSigStartPos" SG_ 1024 WakeupCnt 39;
BA_ "FlexKomSigName" SG_ 1024 WakeupCnt "Wakeup_RF_HUB";
BA_ "FlexKomSigLaenge" SG_ 1024 WakeupCnt 24;
BA_ "FlexKomSID" SG_ 1024 WakeupCnt 620;
BA_ "FlexKomIsMotorola" SG_ 1024 WakeupCnt 1;
BA_ "FlexKomComment" SG_ 1024 WakeupCnt "Mode 2 of NM_Ud_Srv";
BA_ "GenSigStartValue" SG_ 1024 WakeupRsn_RF_HUB 255;
BA_ "GenSigSNA" SG_ 1024 WakeupRsn_RF_HUB "FFh";
BA_ "GenSigSendType" SG_ 1024 WakeupRsn_RF_HUB 1;
BA_ "FlexKomSigStartValue" SG_ 1024 WakeupRsn_RF_HUB "FFFF00h";
BA_ "FlexKomSigStartPos" SG_ 1024 WakeupRsn_RF_HUB 39;
BA_ "FlexKomSigName" SG_ 1024 WakeupRsn_RF_HUB "Wakeup_RF_HUB";
BA_ "FlexKomSigLaenge" SG_ 1024 WakeupRsn_RF_HUB 24;
BA_ "FlexKomSID" SG_ 1024 WakeupRsn_RF_HUB 620;
BA_ "FlexKomIsMotorola" SG_ 1024 WakeupRsn_RF_HUB 1;
BA_ "FlexKomComment" SG_ 1024 WakeupRsn_RF_HUB "Mode 2 of NM_Ud_Srv";
BA_ "GenSigSNA" SG_ 1033 Awake_Diag_Actv "0h";
BA_ "GenSigSendType" SG_ 1033 Awake_Diag_Actv 1;
BA_ "FlexKomSigStartValue" SG_ 1033 Awake_Diag_Actv "000000h";
BA_ "FlexKomSigStartPos" SG_ 1033 Awake_Diag_Actv 39;
BA_ "FlexKomSigName" SG_ 1033 Awake_Diag_Actv "Awake_SBWM";
BA_ "FlexKomSigLaenge" SG_ 1033 Awake_Diag_Actv 24;
BA_ "FlexKomSID" SG_ 1033 Awake_Diag_Actv 1370;
BA_ "FlexKomIsMotorola" SG_ 1033 Awake_Diag_Actv 1;
BA_ "FlexKomComment" SG_ 1033 Awake_Diag_Actv "Mode 15 of NM_Ud_Srv";
BA_ "GenSigSNA" SG_ 1033 Awake_EEPROM "0h";
BA_ "GenSigSendType" SG_ 1033 Awake_EEPROM 1;
BA_ "FlexKomSigStartValue" SG_ 1033 Awake_EEPROM "000000h";
BA_ "FlexKomSigStartPos" SG_ 1033 Awake_EEPROM 39;
BA_ "FlexKomSigName" SG_ 1033 Awake_EEPROM "Awake_SBWM";
BA_ "FlexKomSigLaenge" SG_ 1033 Awake_EEPROM 24;
BA_ "FlexKomSID" SG_ 1033 Awake_EEPROM 1370;
BA_ "FlexKomIsMotorola" SG_ 1033 Awake_EEPROM 1;
BA_ "FlexKomComment" SG_ 1033 Awake_EEPROM "Mode 15 of NM_Ud_Srv";
BA_ "GenSigSNA" SG_ 1033 Awake_Ignition_On "0h";
BA_ "GenSigSendType" SG_ 1033 Awake_Ignition_On 1;
BA_ "FlexKomSigStartValue" SG_ 1033 Awake_Ignition_On "000000h";
BA_ "FlexKomSigStartPos" SG_ 1033 Awake_Ignition_On 39;
BA_ "FlexKomSigName" SG_ 1033 Awake_Ignition_On "Awake_SBWM";
BA_ "FlexKomSigLaenge" SG_ 1033 Awake_Ignition_On 24;
BA_ "FlexKomSID" SG_ 1033 Awake_Ignition_On 1370;
BA_ "FlexKomIsMotorola" SG_ 1033 Awake_Ignition_On 1;
BA_ "FlexKomComment" SG_ 1033 Awake_Ignition_On "Mode 15 of NM_Ud_Srv";
BA_ "GenSigSNA" SG_ 1033 Awake_NwSt "0h";
BA_ "GenSigSendType" SG_ 1033 Awake_NwSt 1;
BA_ "FlexKomSigStartValue" SG_ 1033 Awake_NwSt "000000h";
BA_ "FlexKomSigStartPos" SG_ 1033 Awake_NwSt 39;
BA_ "FlexKomSigName" SG_ 1033 Awake_NwSt "Awake_SBWM";
BA_ "FlexKomSigLaenge" SG_ 1033 Awake_NwSt 24;
BA_ "FlexKomSID" SG_ 1033 Awake_NwSt 1370;
BA_ "FlexKomIsMotorola" SG_ 1033 Awake_NwSt 1;
BA_ "FlexKomComment" SG_ 1033 Awake_NwSt "Mode 15 of NM_Ud_Srv";
BA_ "GenSigSNA" SG_ 1033 Awake_URS "0h";
BA_ "GenSigSendType" SG_ 1033 Awake_URS 1;
BA_ "FlexKomSigStartValue" SG_ 1033 Awake_URS "000000h";
BA_ "FlexKomSigStartPos" SG_ 1033 Awake_URS 39;
BA_ "FlexKomSigName" SG_ 1033 Awake_URS "Awake_SBWM";
BA_ "FlexKomSigLaenge" SG_ 1033 Awake_URS 24;
BA_ "FlexKomSID" SG_ 1033 Awake_URS 1370;
BA_ "FlexKomIsMotorola" SG_ 1033 Awake_URS 1;
BA_ "FlexKomComment" SG_ 1033 Awake_URS "Mode 15 of NM_Ud_Srv";
BA_ "GenSigStartValue" SG_ 1033 NM_Mode 255;
BA_ "GenSigSNA" SG_ 1033 NM_Mode "FFh";
BA_ "GenSigSendType" SG_ 1033 NM_Mode 1;
BA_ "FlexKomSigStartValue" SG_ 1033 NM_Mode "FFFFFFFFh";
BA_ "FlexKomSigStartPos" SG_ 1033 NM_Mode 7;
BA_ "FlexKomSigName" SG_ 1033 NM_Mode "NM";
BA_ "FlexKomSigLaenge" SG_ 1033 NM_Mode 32;
BA_ "FlexKomSID" SG_ 1033 NM_Mode 472;
BA_ "FlexKomIsMotorola" SG_ 1033 NM_Mode 1;
BA_ "FlexKomComment" SG_ 1033 NM_Mode "Network management state";
BA_ "GenSigStartValue" SG_ 1033 NM_Sleep_Ack 1;
BA_ "GenSigSNA" SG_ 1033 NM_Sleep_Ack "1h";
BA_ "GenSigSendType" SG_ 1033 NM_Sleep_Ack 1;
BA_ "FlexKomSigStartValue" SG_ 1033 NM_Sleep_Ack "FFFFFFFFh";
BA_ "FlexKomSigStartPos" SG_ 1033 NM_Sleep_Ack 7;
BA_ "FlexKomSigName" SG_ 1033 NM_Sleep_Ack "NM";
BA_ "FlexKomSigLaenge" SG_ 1033 NM_Sleep_Ack 32;
BA_ "FlexKomSID" SG_ 1033 NM_Sleep_Ack 472;
BA_ "FlexKomIsMotorola" SG_ 1033 NM_Sleep_Ack 1;
BA_ "FlexKomComment" SG_ 1033 NM_Sleep_Ack "Network management state";
BA_ "GenSigStartValue" SG_ 1033 NM_Sleep_Ind 1;
BA_ "GenSigSNA" SG_ 1033 NM_Sleep_Ind "1h";
BA_ "GenSigSendType" SG_ 1033 NM_Sleep_Ind 1;
BA_ "FlexKomSigStartValue" SG_ 1033 NM_Sleep_Ind "FFFFFFFFh";
BA_ "FlexKomSigStartPos" SG_ 1033 NM_Sleep_Ind 7;
BA_ "FlexKomSigName" SG_ 1033 NM_Sleep_Ind "NM";
BA_ "FlexKomSigLaenge" SG_ 1033 NM_Sleep_Ind 32;
BA_ "FlexKomSID" SG_ 1033 NM_Sleep_Ind 472;
BA_ "FlexKomIsMotorola" SG_ 1033 NM_Sleep_Ind 1;
BA_ "FlexKomComment" SG_ 1033 NM_Sleep_Ind "Network management state";
BA_ "GenSigStartValue" SG_ 1033 NM_Successor 255;
BA_ "GenSigSNA" SG_ 1033 NM_Successor "FFh";
BA_ "GenSigSendType" SG_ 1033 NM_Successor 1;
BA_ "FlexKomSigStartValue" SG_ 1033 NM_Successor "FFFFFFFFh";
BA_ "FlexKomSigStartPos" SG_ 1033 NM_Successor 7;
BA_ "FlexKomSigName" SG_ 1033 NM_Successor "NM";
BA_ "FlexKomSigLaenge" SG_ 1033 NM_Successor 32;
BA_ "FlexKomSID" SG_ 1033 NM_Successor 472;
BA_ "FlexKomIsMotorola" SG_ 1033 NM_Successor 1;
BA_ "FlexKomComment" SG_ 1033 NM_Successor "Network management state";
BA_ "GenSigStartValue" SG_ 1033 NM_Ud_Launch 63;
BA_ "GenSigSNA" SG_ 1033 NM_Ud_Launch "3Fh";
BA_ "GenSigSendType" SG_ 1033 NM_Ud_Launch 1;
BA_ "FlexKomSigStartValue" SG_ 1033 NM_Ud_Launch "FFFFFFFFh";
BA_ "FlexKomSigStartPos" SG_ 1033 NM_Ud_Launch 7;
BA_ "FlexKomSigName" SG_ 1033 NM_Ud_Launch "NM";
BA_ "FlexKomSigLaenge" SG_ 1033 NM_Ud_Launch 32;
BA_ "FlexKomSID" SG_ 1033 NM_Ud_Launch 472;
BA_ "FlexKomIsMotorola" SG_ 1033 NM_Ud_Launch 1;
BA_ "FlexKomComment" SG_ 1033 NM_Ud_Launch "Network management state";
BA_ "GenSigStartValue" SG_ 1033 NM_Ud_Srv 255;
BA_ "GenSigSNA" SG_ 1033 NM_Ud_Srv "FFh";
BA_ "GenSigSendType" SG_ 1033 NM_Ud_Srv 1;
BA_ "FlexKomSigStartValue" SG_ 1033 NM_Ud_Srv "FFFFFFFFh";
BA_ "FlexKomSigStartPos" SG_ 1033 NM_Ud_Srv 7;
BA_ "FlexKomSigName" SG_ 1033 NM_Ud_Srv "NM";
BA_ "FlexKomSigLaenge" SG_ 1033 NM_Ud_Srv 32;
BA_ "FlexKomSID" SG_ 1033 NM_Ud_Srv 472;
BA_ "FlexKomIsMotorola" SG_ 1033 NM_Ud_Srv 1;
BA_ "FlexKomComment" SG_ 1033 NM_Ud_Srv "Network management state";
BA_ "GenSigStartValue" SG_ 1033 Nw_Id 255;
BA_ "GenSigSNA" SG_ 1033 Nw_Id "FFh";
BA_ "GenSigSendType" SG_ 1033 Nw_Id 1;
BA_ "FlexKomSigStartValue" SG_ 1033 Nw_Id "FFh";
BA_ "FlexKomSigStartPos" SG_ 1033 Nw_Id 63;
BA_ "FlexKomSigName" SG_ 1033 Nw_Id "Nw_Id";
BA_ "FlexKomSigLaenge" SG_ 1033 Nw_Id 8;
BA_ "FlexKomSID" SG_ 1033 Nw_Id 535;
BA_ "FlexKomIsMotorola" SG_ 1033 Nw_Id 1;
BA_ "FlexKomComment" SG_ 1033 Nw_Id "Network identification no.";
BA_ "GenSigStartValue" SG_ 1033 WakeupCnt 255;
BA_ "GenSigSNA" SG_ 1033 WakeupCnt "FFh";
BA_ "GenSigSendType" SG_ 1033 WakeupCnt 1;
BA_ "FlexKomSigStartValue" SG_ 1033 WakeupCnt "FFFF00h";
BA_ "FlexKomSigStartPos" SG_ 1033 WakeupCnt 39;
BA_ "FlexKomSigName" SG_ 1033 WakeupCnt "Wakeup_SBWM";
BA_ "FlexKomSigLaenge" SG_ 1033 WakeupCnt 24;
BA_ "FlexKomSID" SG_ 1033 WakeupCnt 1371;
BA_ "FlexKomIsMotorola" SG_ 1033 WakeupCnt 1;
BA_ "FlexKomComment" SG_ 1033 WakeupCnt "Mode 2 of NM_Ud_Srv";
BA_ "GenSigStartValue" SG_ 1033 WakeupRsn_SBWM 255;
BA_ "GenSigSNA" SG_ 1033 WakeupRsn_SBWM "FFh";
BA_ "GenSigSendType" SG_ 1033 WakeupRsn_SBWM 1;
BA_ "FlexKomSigStartValue" SG_ 1033 WakeupRsn_SBWM "FFFF00h";
BA_ "FlexKomSigStartPos" SG_ 1033 WakeupRsn_SBWM 39;
BA_ "FlexKomSigName" SG_ 1033 WakeupRsn_SBWM "Wakeup_SBWM";
BA_ "FlexKomSigLaenge" SG_ 1033 WakeupRsn_SBWM 24;
BA_ "FlexKomSID" SG_ 1033 WakeupRsn_SBWM 1371;
BA_ "FlexKomIsMotorola" SG_ 1033 WakeupRsn_SBWM 1;
BA_ "FlexKomComment" SG_ 1033 WakeupRsn_SBWM "Mode 2 of NM_Ud_Srv";
BA_ "GenSigSNA" SG_ 1059 Awake_Diag_Actv "0h";
BA_ "GenSigSendType" SG_ 1059 Awake_Diag_Actv 1;
BA_ "FlexKomSigStartValue" SG_ 1059 Awake_Diag_Actv "000000h";
BA_ "FlexKomSigStartPos" SG_ 1059 Awake_Diag_Actv 39;
BA_ "FlexKomSigName" SG_ 1059 Awake_Diag_Actv "Awake_SCCM_Pkt";
BA_ "FlexKomSigLaenge" SG_ 1059 Awake_Diag_Actv 24;
BA_ "FlexKomSID" SG_ 1059 Awake_Diag_Actv 524;
BA_ "FlexKomIsMotorola" SG_ 1059 Awake_Diag_Actv 1;
BA_ "FlexKomComment" SG_ 1059 Awake_Diag_Actv "Mode 15 of NM_Ud_Srv";
BA_ "GenSigSNA" SG_ 1059 Awake_EEPROM "0h";
BA_ "GenSigSendType" SG_ 1059 Awake_EEPROM 1;
BA_ "FlexKomSigStartValue" SG_ 1059 Awake_EEPROM "000000h";
BA_ "FlexKomSigStartPos" SG_ 1059 Awake_EEPROM 39;
BA_ "FlexKomSigName" SG_ 1059 Awake_EEPROM "Awake_SCCM_Pkt";
BA_ "FlexKomSigLaenge" SG_ 1059 Awake_EEPROM 24;
BA_ "FlexKomSID" SG_ 1059 Awake_EEPROM 524;
BA_ "FlexKomIsMotorola" SG_ 1059 Awake_EEPROM 1;
BA_ "FlexKomComment" SG_ 1059 Awake_EEPROM "Mode 15 of NM_Ud_Srv";
BA_ "GenSigSNA" SG_ 1059 Awake_FTP_Psd "0h";
BA_ "GenSigSendType" SG_ 1059 Awake_FTP_Psd 1;
BA_ "FlexKomSigStartValue" SG_ 1059 Awake_FTP_Psd "000000h";
BA_ "FlexKomSigStartPos" SG_ 1059 Awake_FTP_Psd 39;
BA_ "FlexKomSigName" SG_ 1059 Awake_FTP_Psd "Awake_SCCM_Pkt";
BA_ "FlexKomSigLaenge" SG_ 1059 Awake_FTP_Psd 24;
BA_ "FlexKomSID" SG_ 1059 Awake_FTP_Psd 524;
BA_ "FlexKomIsMotorola" SG_ 1059 Awake_FTP_Psd 1;
BA_ "FlexKomComment" SG_ 1059 Awake_FTP_Psd "Mode 15 of NM_Ud_Srv";
BA_ "GenSigSNA" SG_ 1059 Awake_HrnSwt_Actv "0h";
BA_ "GenSigSendType" SG_ 1059 Awake_HrnSwt_Actv 1;
BA_ "FlexKomSigStartValue" SG_ 1059 Awake_HrnSwt_Actv "000000h";
BA_ "FlexKomSigStartPos" SG_ 1059 Awake_HrnSwt_Actv 39;
BA_ "FlexKomSigName" SG_ 1059 Awake_HrnSwt_Actv "Awake_SCCM_Pkt";
BA_ "FlexKomSigLaenge" SG_ 1059 Awake_HrnSwt_Actv 24;
BA_ "FlexKomSID" SG_ 1059 Awake_HrnSwt_Actv 524;
BA_ "FlexKomIsMotorola" SG_ 1059 Awake_HrnSwt_Actv 1;
BA_ "FlexKomComment" SG_ 1059 Awake_HrnSwt_Actv "Mode 15 of NM_Ud_Srv";
BA_ "GenSigSNA" SG_ 1059 Awake_Ignition_On "0h";
BA_ "GenSigSendType" SG_ 1059 Awake_Ignition_On 1;
BA_ "FlexKomSigStartValue" SG_ 1059 Awake_Ignition_On "000000h";
BA_ "FlexKomSigStartPos" SG_ 1059 Awake_Ignition_On 39;
BA_ "FlexKomSigName" SG_ 1059 Awake_Ignition_On "Awake_SCCM_Pkt";
BA_ "FlexKomSigLaenge" SG_ 1059 Awake_Ignition_On 24;
BA_ "FlexKomSID" SG_ 1059 Awake_Ignition_On 524;
BA_ "FlexKomIsMotorola" SG_ 1059 Awake_Ignition_On 1;
BA_ "FlexKomComment" SG_ 1059 Awake_Ignition_On "Mode 15 of NM_Ud_Srv";
BA_ "GenSigSNA" SG_ 1059 Awake_NwSt "0h";
BA_ "GenSigSendType" SG_ 1059 Awake_NwSt 1;
BA_ "FlexKomSigStartValue" SG_ 1059 Awake_NwSt "000000h";
BA_ "FlexKomSigStartPos" SG_ 1059 Awake_NwSt 39;
BA_ "FlexKomSigName" SG_ 1059 Awake_NwSt "Awake_SCCM_Pkt";
BA_ "FlexKomSigLaenge" SG_ 1059 Awake_NwSt 24;
BA_ "FlexKomSID" SG_ 1059 Awake_NwSt 524;
BA_ "FlexKomIsMotorola" SG_ 1059 Awake_NwSt 1;
BA_ "FlexKomComment" SG_ 1059 Awake_NwSt "Mode 15 of NM_Ud_Srv";
BA_ "GenSigSNA" SG_ 1059 Awake_StwSw_Actv "0h";
BA_ "GenSigSendType" SG_ 1059 Awake_StwSw_Actv 1;
BA_ "FlexKomSigStartValue" SG_ 1059 Awake_StwSw_Actv "000000h";
BA_ "FlexKomSigStartPos" SG_ 1059 Awake_StwSw_Actv 39;
BA_ "FlexKomSigName" SG_ 1059 Awake_StwSw_Actv "Awake_SCCM_Pkt";
BA_ "FlexKomSigLaenge" SG_ 1059 Awake_StwSw_Actv 24;
BA_ "FlexKomSID" SG_ 1059 Awake_StwSw_Actv 524;
BA_ "FlexKomIsMotorola" SG_ 1059 Awake_StwSw_Actv 1;
BA_ "FlexKomComment" SG_ 1059 Awake_StwSw_Actv "Mode 15 of NM_Ud_Srv";
BA_ "GenSigSNA" SG_ 1059 Awake_tilt_tel_Psd "0h";
BA_ "GenSigSendType" SG_ 1059 Awake_tilt_tel_Psd 1;
BA_ "FlexKomSigStartValue" SG_ 1059 Awake_tilt_tel_Psd "000000h";
BA_ "FlexKomSigStartPos" SG_ 1059 Awake_tilt_tel_Psd 39;
BA_ "FlexKomSigName" SG_ 1059 Awake_tilt_tel_Psd "Awake_SCCM_Pkt";
BA_ "FlexKomSigLaenge" SG_ 1059 Awake_tilt_tel_Psd 24;
BA_ "FlexKomSID" SG_ 1059 Awake_tilt_tel_Psd 524;
BA_ "FlexKomIsMotorola" SG_ 1059 Awake_tilt_tel_Psd 1;
BA_ "FlexKomComment" SG_ 1059 Awake_tilt_tel_Psd "Mode 15 of NM_Ud_Srv";
BA_ "GenSigStartValue" SG_ 1059 NM_Mode 255;
BA_ "GenSigSNA" SG_ 1059 NM_Mode "FFh";
BA_ "GenSigSendType" SG_ 1059 NM_Mode 1;
BA_ "FlexKomSigStartValue" SG_ 1059 NM_Mode "FFFFFFFFh";
BA_ "FlexKomSigStartPos" SG_ 1059 NM_Mode 7;
BA_ "FlexKomSigName" SG_ 1059 NM_Mode "NM";
BA_ "FlexKomSigLaenge" SG_ 1059 NM_Mode 32;
BA_ "FlexKomSID" SG_ 1059 NM_Mode 472;
BA_ "FlexKomIsMotorola" SG_ 1059 NM_Mode 1;
BA_ "FlexKomComment" SG_ 1059 NM_Mode "Network management state";
BA_ "GenSigStartValue" SG_ 1059 NM_Sleep_Ack 1;
BA_ "GenSigSNA" SG_ 1059 NM_Sleep_Ack "1h";
BA_ "GenSigSendType" SG_ 1059 NM_Sleep_Ack 1;
BA_ "FlexKomSigStartValue" SG_ 1059 NM_Sleep_Ack "FFFFFFFFh";
BA_ "FlexKomSigStartPos" SG_ 1059 NM_Sleep_Ack 7;
BA_ "FlexKomSigName" SG_ 1059 NM_Sleep_Ack "NM";
BA_ "FlexKomSigLaenge" SG_ 1059 NM_Sleep_Ack 32;
BA_ "FlexKomSID" SG_ 1059 NM_Sleep_Ack 472;
BA_ "FlexKomIsMotorola" SG_ 1059 NM_Sleep_Ack 1;
BA_ "FlexKomComment" SG_ 1059 NM_Sleep_Ack "Network management state";
BA_ "GenSigStartValue" SG_ 1059 NM_Sleep_Ind 1;
BA_ "GenSigSNA" SG_ 1059 NM_Sleep_Ind "1h";
BA_ "GenSigSendType" SG_ 1059 NM_Sleep_Ind 1;
BA_ "FlexKomSigStartValue" SG_ 1059 NM_Sleep_Ind "FFFFFFFFh";
BA_ "FlexKomSigStartPos" SG_ 1059 NM_Sleep_Ind 7;
BA_ "FlexKomSigName" SG_ 1059 NM_Sleep_Ind "NM";
BA_ "FlexKomSigLaenge" SG_ 1059 NM_Sleep_Ind 32;
BA_ "FlexKomSID" SG_ 1059 NM_Sleep_Ind 472;
BA_ "FlexKomIsMotorola" SG_ 1059 NM_Sleep_Ind 1;
BA_ "FlexKomComment" SG_ 1059 NM_Sleep_Ind "Network management state";
BA_ "GenSigStartValue" SG_ 1059 NM_Successor 255;
BA_ "GenSigSNA" SG_ 1059 NM_Successor "FFh";
BA_ "GenSigSendType" SG_ 1059 NM_Successor 1;
BA_ "FlexKomSigStartValue" SG_ 1059 NM_Successor "FFFFFFFFh";
BA_ "FlexKomSigStartPos" SG_ 1059 NM_Successor 7;
BA_ "FlexKomSigName" SG_ 1059 NM_Successor "NM";
BA_ "FlexKomSigLaenge" SG_ 1059 NM_Successor 32;
BA_ "FlexKomSID" SG_ 1059 NM_Successor 472;
BA_ "FlexKomIsMotorola" SG_ 1059 NM_Successor 1;
BA_ "FlexKomComment" SG_ 1059 NM_Successor "Network management state";
BA_ "GenSigStartValue" SG_ 1059 NM_Ud_Launch 63;
BA_ "GenSigSNA" SG_ 1059 NM_Ud_Launch "3Fh";
BA_ "GenSigSendType" SG_ 1059 NM_Ud_Launch 1;
BA_ "FlexKomSigStartValue" SG_ 1059 NM_Ud_Launch "FFFFFFFFh";
BA_ "FlexKomSigStartPos" SG_ 1059 NM_Ud_Launch 7;
BA_ "FlexKomSigName" SG_ 1059 NM_Ud_Launch "NM";
BA_ "FlexKomSigLaenge" SG_ 1059 NM_Ud_Launch 32;
BA_ "FlexKomSID" SG_ 1059 NM_Ud_Launch 472;
BA_ "FlexKomIsMotorola" SG_ 1059 NM_Ud_Launch 1;
BA_ "FlexKomComment" SG_ 1059 NM_Ud_Launch "Network management state";
BA_ "GenSigStartValue" SG_ 1059 NM_Ud_Srv 255;
BA_ "GenSigSNA" SG_ 1059 NM_Ud_Srv "FFh";
BA_ "GenSigSendType" SG_ 1059 NM_Ud_Srv 1;
BA_ "FlexKomSigStartValue" SG_ 1059 NM_Ud_Srv "FFFFFFFFh";
BA_ "FlexKomSigStartPos" SG_ 1059 NM_Ud_Srv 7;
BA_ "FlexKomSigName" SG_ 1059 NM_Ud_Srv "NM";
BA_ "FlexKomSigLaenge" SG_ 1059 NM_Ud_Srv 32;
BA_ "FlexKomSID" SG_ 1059 NM_Ud_Srv 472;
BA_ "FlexKomIsMotorola" SG_ 1059 NM_Ud_Srv 1;
BA_ "FlexKomComment" SG_ 1059 NM_Ud_Srv "Network management state";
BA_ "GenSigStartValue" SG_ 1059 Nw_Id 255;
BA_ "GenSigSNA" SG_ 1059 Nw_Id "FFh";
BA_ "GenSigSendType" SG_ 1059 Nw_Id 1;
BA_ "FlexKomSigStartValue" SG_ 1059 Nw_Id "FFh";
BA_ "FlexKomSigStartPos" SG_ 1059 Nw_Id 63;
BA_ "FlexKomSigName" SG_ 1059 Nw_Id "Nw_Id";
BA_ "FlexKomSigLaenge" SG_ 1059 Nw_Id 8;
BA_ "FlexKomSID" SG_ 1059 Nw_Id 535;
BA_ "FlexKomIsMotorola" SG_ 1059 Nw_Id 1;
BA_ "FlexKomComment" SG_ 1059 Nw_Id "Network identification no.";
BA_ "GenSigStartValue" SG_ 1059 WakeupCnt 255;
BA_ "GenSigSNA" SG_ 1059 WakeupCnt "FFh";
BA_ "GenSigSendType" SG_ 1059 WakeupCnt 1;
BA_ "FlexKomSigStartValue" SG_ 1059 WakeupCnt "FFFF00h";
BA_ "FlexKomSigStartPos" SG_ 1059 WakeupCnt 39;
BA_ "FlexKomSigName" SG_ 1059 WakeupCnt "Wakeup_SCCM_Pkt";
BA_ "FlexKomSigLaenge" SG_ 1059 WakeupCnt 24;
BA_ "FlexKomSID" SG_ 1059 WakeupCnt 494;
BA_ "FlexKomIsMotorola" SG_ 1059 WakeupCnt 1;
BA_ "FlexKomComment" SG_ 1059 WakeupCnt "Mode 2 of NM_Ud_Srv";
BA_ "GenSigStartValue" SG_ 1059 WakeupRsn_SCCM 255;
BA_ "GenSigSNA" SG_ 1059 WakeupRsn_SCCM "FFh";
BA_ "GenSigSendType" SG_ 1059 WakeupRsn_SCCM 1;
BA_ "FlexKomSigStartValue" SG_ 1059 WakeupRsn_SCCM "FFFF00h";
BA_ "FlexKomSigStartPos" SG_ 1059 WakeupRsn_SCCM 39;
BA_ "FlexKomSigName" SG_ 1059 WakeupRsn_SCCM "Wakeup_SCCM_Pkt";
BA_ "FlexKomSigLaenge" SG_ 1059 WakeupRsn_SCCM 24;
BA_ "FlexKomSID" SG_ 1059 WakeupRsn_SCCM 494;
BA_ "FlexKomIsMotorola" SG_ 1059 WakeupRsn_SCCM 1;
BA_ "FlexKomComment" SG_ 1059 WakeupRsn_SCCM "Mode 2 of NM_Ud_Srv";
BA_ "GenSigSNA" SG_ 1027 Awake_Diag_Actv "0h";
BA_ "GenSigSendType" SG_ 1027 Awake_Diag_Actv 1;
BA_ "FlexKomSigStartValue" SG_ 1027 Awake_Diag_Actv "000000h";
BA_ "FlexKomSigStartPos" SG_ 1027 Awake_Diag_Actv 39;
BA_ "FlexKomSigName" SG_ 1027 Awake_Diag_Actv "Awake_TPM";
BA_ "FlexKomSigLaenge" SG_ 1027 Awake_Diag_Actv 24;
BA_ "FlexKomSID" SG_ 1027 Awake_Diag_Actv 529;
BA_ "FlexKomIsMotorola" SG_ 1027 Awake_Diag_Actv 1;
BA_ "FlexKomComment" SG_ 1027 Awake_Diag_Actv "Mode 15 of NM_Ud_Srv";
BA_ "GenSigSNA" SG_ 1027 Awake_NwSt "0h";
BA_ "GenSigSendType" SG_ 1027 Awake_NwSt 1;
BA_ "FlexKomSigStartValue" SG_ 1027 Awake_NwSt "000000h";
BA_ "FlexKomSigStartPos" SG_ 1027 Awake_NwSt 39;
BA_ "FlexKomSigName" SG_ 1027 Awake_NwSt "Awake_TPM";
BA_ "FlexKomSigLaenge" SG_ 1027 Awake_NwSt 24;
BA_ "FlexKomSID" SG_ 1027 Awake_NwSt 529;
BA_ "FlexKomIsMotorola" SG_ 1027 Awake_NwSt 1;
BA_ "FlexKomComment" SG_ 1027 Awake_NwSt "Mode 15 of NM_Ud_Srv";
BA_ "GenSigStartValue" SG_ 1027 NM_Mode 255;
BA_ "GenSigSNA" SG_ 1027 NM_Mode "FFh";
BA_ "GenSigSendType" SG_ 1027 NM_Mode 1;
BA_ "FlexKomSigStartValue" SG_ 1027 NM_Mode "FFFFFFFFh";
BA_ "FlexKomSigStartPos" SG_ 1027 NM_Mode 7;
BA_ "FlexKomSigName" SG_ 1027 NM_Mode "NM";
BA_ "FlexKomSigLaenge" SG_ 1027 NM_Mode 32;
BA_ "FlexKomSID" SG_ 1027 NM_Mode 472;
BA_ "FlexKomIsMotorola" SG_ 1027 NM_Mode 1;
BA_ "FlexKomComment" SG_ 1027 NM_Mode "Network management state";
BA_ "GenSigStartValue" SG_ 1027 NM_Sleep_Ack 1;
BA_ "GenSigSNA" SG_ 1027 NM_Sleep_Ack "1h";
BA_ "GenSigSendType" SG_ 1027 NM_Sleep_Ack 1;
BA_ "FlexKomSigStartValue" SG_ 1027 NM_Sleep_Ack "FFFFFFFFh";
BA_ "FlexKomSigStartPos" SG_ 1027 NM_Sleep_Ack 7;
BA_ "FlexKomSigName" SG_ 1027 NM_Sleep_Ack "NM";
BA_ "FlexKomSigLaenge" SG_ 1027 NM_Sleep_Ack 32;
BA_ "FlexKomSID" SG_ 1027 NM_Sleep_Ack 472;
BA_ "FlexKomIsMotorola" SG_ 1027 NM_Sleep_Ack 1;
BA_ "FlexKomComment" SG_ 1027 NM_Sleep_Ack "Network management state";
BA_ "GenSigStartValue" SG_ 1027 NM_Sleep_Ind 1;
BA_ "GenSigSNA" SG_ 1027 NM_Sleep_Ind "1h";
BA_ "GenSigSendType" SG_ 1027 NM_Sleep_Ind 1;
BA_ "FlexKomSigStartValue" SG_ 1027 NM_Sleep_Ind "FFFFFFFFh";
BA_ "FlexKomSigStartPos" SG_ 1027 NM_Sleep_Ind 7;
BA_ "FlexKomSigName" SG_ 1027 NM_Sleep_Ind "NM";
BA_ "FlexKomSigLaenge" SG_ 1027 NM_Sleep_Ind 32;
BA_ "FlexKomSID" SG_ 1027 NM_Sleep_Ind 472;
BA_ "FlexKomIsMotorola" SG_ 1027 NM_Sleep_Ind 1;
BA_ "FlexKomComment" SG_ 1027 NM_Sleep_Ind "Network management state";
BA_ "GenSigStartValue" SG_ 1027 NM_Successor 255;
BA_ "GenSigSNA" SG_ 1027 NM_Successor "FFh";
BA_ "GenSigSendType" SG_ 1027 NM_Successor 1;
BA_ "FlexKomSigStartValue" SG_ 1027 NM_Successor "FFFFFFFFh";
BA_ "FlexKomSigStartPos" SG_ 1027 NM_Successor 7;
BA_ "FlexKomSigName" SG_ 1027 NM_Successor "NM";
BA_ "FlexKomSigLaenge" SG_ 1027 NM_Successor 32;
BA_ "FlexKomSID" SG_ 1027 NM_Successor 472;
BA_ "FlexKomIsMotorola" SG_ 1027 NM_Successor 1;
BA_ "FlexKomComment" SG_ 1027 NM_Successor "Network management state";
BA_ "GenSigStartValue" SG_ 1027 NM_Ud_Launch 63;
BA_ "GenSigSNA" SG_ 1027 NM_Ud_Launch "3Fh";
BA_ "GenSigSendType" SG_ 1027 NM_Ud_Launch 1;
BA_ "FlexKomSigStartValue" SG_ 1027 NM_Ud_Launch "FFFFFFFFh";
BA_ "FlexKomSigStartPos" SG_ 1027 NM_Ud_Launch 7;
BA_ "FlexKomSigName" SG_ 1027 NM_Ud_Launch "NM";
BA_ "FlexKomSigLaenge" SG_ 1027 NM_Ud_Launch 32;
BA_ "FlexKomSID" SG_ 1027 NM_Ud_Launch 472;
BA_ "FlexKomIsMotorola" SG_ 1027 NM_Ud_Launch 1;
BA_ "FlexKomComment" SG_ 1027 NM_Ud_Launch "Network management state";
BA_ "GenSigStartValue" SG_ 1027 NM_Ud_Srv 255;
BA_ "GenSigSNA" SG_ 1027 NM_Ud_Srv "FFh";
BA_ "GenSigSendType" SG_ 1027 NM_Ud_Srv 1;
BA_ "FlexKomSigStartValue" SG_ 1027 NM_Ud_Srv "FFFFFFFFh";
BA_ "FlexKomSigStartPos" SG_ 1027 NM_Ud_Srv 7;
BA_ "FlexKomSigName" SG_ 1027 NM_Ud_Srv "NM";
BA_ "FlexKomSigLaenge" SG_ 1027 NM_Ud_Srv 32;
BA_ "FlexKomSID" SG_ 1027 NM_Ud_Srv 472;
BA_ "FlexKomIsMotorola" SG_ 1027 NM_Ud_Srv 1;
BA_ "FlexKomComment" SG_ 1027 NM_Ud_Srv "Network management state";
BA_ "GenSigStartValue" SG_ 1027 Nw_Id 255;
BA_ "GenSigSNA" SG_ 1027 Nw_Id "FFh";
BA_ "GenSigSendType" SG_ 1027 Nw_Id 1;
BA_ "FlexKomSigStartValue" SG_ 1027 Nw_Id "FFh";
BA_ "FlexKomSigStartPos" SG_ 1027 Nw_Id 63;
BA_ "FlexKomSigName" SG_ 1027 Nw_Id "Nw_Id";
BA_ "FlexKomSigLaenge" SG_ 1027 Nw_Id 8;
BA_ "FlexKomSID" SG_ 1027 Nw_Id 535;
BA_ "FlexKomIsMotorola" SG_ 1027 Nw_Id 1;
BA_ "FlexKomComment" SG_ 1027 Nw_Id "Network identification no.";
BA_ "GenSigStartValue" SG_ 1027 WakeupCnt 255;
BA_ "GenSigSNA" SG_ 1027 WakeupCnt "FFh";
BA_ "GenSigSendType" SG_ 1027 WakeupCnt 1;
BA_ "FlexKomSigStartValue" SG_ 1027 WakeupCnt "FFFF00h";
BA_ "FlexKomSigStartPos" SG_ 1027 WakeupCnt 39;
BA_ "FlexKomSigName" SG_ 1027 WakeupCnt "Wakeup_TPM";
BA_ "FlexKomSigLaenge" SG_ 1027 WakeupCnt 24;
BA_ "FlexKomSID" SG_ 1027 WakeupCnt 499;
BA_ "FlexKomIsMotorola" SG_ 1027 WakeupCnt 1;
BA_ "FlexKomComment" SG_ 1027 WakeupCnt "Mode 2 of NM_Ud_Srv";
BA_ "GenSigStartValue" SG_ 1027 WakeupRsn_TPM 255;
BA_ "GenSigSNA" SG_ 1027 WakeupRsn_TPM "FFh";
BA_ "GenSigSendType" SG_ 1027 WakeupRsn_TPM 1;
BA_ "FlexKomSigStartValue" SG_ 1027 WakeupRsn_TPM "FFFF00h";
BA_ "FlexKomSigStartPos" SG_ 1027 WakeupRsn_TPM 39;
BA_ "FlexKomSigName" SG_ 1027 WakeupRsn_TPM "Wakeup_TPM";
BA_ "FlexKomSigLaenge" SG_ 1027 WakeupRsn_TPM 24;
BA_ "FlexKomSID" SG_ 1027 WakeupRsn_TPM 499;
BA_ "FlexKomIsMotorola" SG_ 1027 WakeupRsn_TPM 1;
BA_ "FlexKomComment" SG_ 1027 WakeupRsn_TPM "Mode 2 of NM_Ud_Srv";
BA_ "GenSigTimeout_ORC" SG_ 601 CRC_OCM_A1 3500;
BA_ "GenSigStartValue" SG_ 601 CRC_OCM_A1 255;
BA_ "GenSigSNA" SG_ 601 CRC_OCM_A1 "FFh";
BA_ "GenSigSendType" SG_ 601 CRC_OCM_A1 5;
BA_ "GenSigCycleTime" SG_ 601 CRC_OCM_A1 1000;
BA_ "FlexKomSigStartValue" SG_ 601 CRC_OCM_A1 "0F0F0000000000FFh";
BA_ "FlexKomSigStartPos" SG_ 601 CRC_OCM_A1 7;
BA_ "FlexKomSigName" SG_ 601 CRC_OCM_A1 "OC_P_Stat";
BA_ "FlexKomSigLaenge" SG_ 601 CRC_OCM_A1 64;
BA_ "FlexKomSID" SG_ 601 CRC_OCM_A1 1586;
BA_ "FlexKomIsMotorola" SG_ 601 CRC_OCM_A1 1;
BA_ "FlexKomComment" SG_ 601 CRC_OCM_A1 "Passenger occupant classification system status";
BA_ "GenSigTimeout_ORC" SG_ 601 MC_OCM_A1 3500;
BA_ "GenSigSNA" SG_ 601 MC_OCM_A1 "0h";
BA_ "GenSigSendType" SG_ 601 MC_OCM_A1 5;
BA_ "GenSigCycleTime" SG_ 601 MC_OCM_A1 1000;
BA_ "FlexKomSigStartValue" SG_ 601 MC_OCM_A1 "0F0F0000000000FFh";
BA_ "FlexKomSigStartPos" SG_ 601 MC_OCM_A1 7;
BA_ "FlexKomSigName" SG_ 601 MC_OCM_A1 "OC_P_Stat";
BA_ "FlexKomSigLaenge" SG_ 601 MC_OCM_A1 64;
BA_ "FlexKomSID" SG_ 601 MC_OCM_A1 1586;
BA_ "FlexKomIsMotorola" SG_ 601 MC_OCM_A1 1;
BA_ "FlexKomComment" SG_ 601 MC_OCM_A1 "Passenger occupant classification system status";
BA_ "GenSigTimeout_ORC" SG_ 601 PsgSeatOCFaultSts 3500;
BA_ "GenSigSNA" SG_ 601 PsgSeatOCFaultSts "0h";
BA_ "GenSigSendType" SG_ 601 PsgSeatOCFaultSts 5;
BA_ "GenSigCycleTime" SG_ 601 PsgSeatOCFaultSts 1000;
BA_ "FlexKomSigStartValue" SG_ 601 PsgSeatOCFaultSts "0F0F0000000000FFh";
BA_ "FlexKomSigStartPos" SG_ 601 PsgSeatOCFaultSts 7;
BA_ "FlexKomSigName" SG_ 601 PsgSeatOCFaultSts "OC_P_Stat";
BA_ "FlexKomSigLaenge" SG_ 601 PsgSeatOCFaultSts 64;
BA_ "FlexKomSID" SG_ 601 PsgSeatOCFaultSts 1586;
BA_ "FlexKomIsMotorola" SG_ 601 PsgSeatOCFaultSts 1;
BA_ "FlexKomComment" SG_ 601 PsgSeatOCFaultSts "Passenger occupant classification system status";
BA_ "GenSigTimeout_ORC" SG_ 601 PsgSeatOCSts 3500;
BA_ "GenSigStartValue" SG_ 601 PsgSeatOCSts 15;
BA_ "GenSigSNA" SG_ 601 PsgSeatOCSts "Fh";
BA_ "GenSigSendType" SG_ 601 PsgSeatOCSts 5;
BA_ "GenSigCycleTime" SG_ 601 PsgSeatOCSts 1000;
BA_ "FlexKomSigStartValue" SG_ 601 PsgSeatOCSts "0F0F0000000000FFh";
BA_ "FlexKomSigStartPos" SG_ 601 PsgSeatOCSts 7;
BA_ "FlexKomSigName" SG_ 601 PsgSeatOCSts "OC_P_Stat";
BA_ "FlexKomSigLaenge" SG_ 601 PsgSeatOCSts 64;
BA_ "FlexKomSID" SG_ 601 PsgSeatOCSts 1586;
BA_ "FlexKomIsMotorola" SG_ 601 PsgSeatOCSts 1;
BA_ "FlexKomComment" SG_ 601 PsgSeatOCSts "Passenger occupant classification system status";
BA_ "GenSigTimeout_ORC" SG_ 601 PsgSeatSBRSts 3500;
BA_ "GenSigStartValue" SG_ 601 PsgSeatSBRSts 15;
BA_ "GenSigSNA" SG_ 601 PsgSeatSBRSts "Fh";
BA_ "GenSigSendType" SG_ 601 PsgSeatSBRSts 5;
BA_ "GenSigCycleTime" SG_ 601 PsgSeatSBRSts 1000;
BA_ "FlexKomSigStartValue" SG_ 601 PsgSeatSBRSts "0F0F0000000000FFh";
BA_ "FlexKomSigStartPos" SG_ 601 PsgSeatSBRSts 7;
BA_ "FlexKomSigName" SG_ 601 PsgSeatSBRSts "OC_P_Stat";
BA_ "FlexKomSigLaenge" SG_ 601 PsgSeatSBRSts 64;
BA_ "FlexKomSID" SG_ 601 PsgSeatSBRSts 1586;
BA_ "FlexKomIsMotorola" SG_ 601 PsgSeatSBRSts 1;
BA_ "FlexKomComment" SG_ 601 PsgSeatSBRSts "Passenger occupant classification system status";
BA_ "RID" SG_ 464 DRV_SEATBELT "1107";
BA_ "GenSigTimeout_TBM" SG_ 464 DRV_SEATBELT 10500;
BA_ "GenSigTimeout_PTS" SG_ 464 DRV_SEATBELT 10500;
BA_ "GenSigTimeout_IC" SG_ 464 DRV_SEATBELT 10500;
BA_ "GenSigTimeout_ETM" SG_ 464 DRV_SEATBELT 10500;
BA_ "GenSigTimeout_CBC" SG_ 464 DRV_SEATBELT 10500;
BA_ "GenSigStartValue" SG_ 464 DRV_SEATBELT 3;
BA_ "GenSigSNA" SG_ 464 DRV_SEATBELT "3h";
BA_ "GenSigSendType" SG_ 464 DRV_SEATBELT 5;
BA_ "GenSigCycleTime" SG_ 464 DRV_SEATBELT 1000;
BA_ "FlexKomSigStartValue" SG_ 464 DRV_SEATBELT "03h";
BA_ "FlexKomSigStartPos" SG_ 464 DRV_SEATBELT 17;
BA_ "FlexKomSigName" SG_ 464 DRV_SEATBELT "DRV_SEATBELT";
BA_ "FlexKomSigLaenge" SG_ 464 DRV_SEATBELT 2;
BA_ "FlexKomSID" SG_ 464 DRV_SEATBELT 330;
BA_ "FlexKomIsMotorola" SG_ 464 DRV_SEATBELT 1;
BA_ "FlexKomComment" SG_ 464 DRV_SEATBELT "Drivers seat belt status";
BA_ "RID" SG_ 464 DrvSbltUnFltr "1973";
BA_ "GenSigStartValue" SG_ 464 DrvSbltUnFltr 7;
BA_ "GenSigSNA" SG_ 464 DrvSbltUnFltr "7h";
BA_ "GenSigSendType" SG_ 464 DrvSbltUnFltr 5;
BA_ "GenSigCycleTime" SG_ 464 DrvSbltUnFltr 1000;
BA_ "FlexKomSigStartValue" SG_ 464 DrvSbltUnFltr "07h";
BA_ "FlexKomSigStartPos" SG_ 464 DrvSbltUnFltr 15;
BA_ "FlexKomSigName" SG_ 464 DrvSbltUnFltr "DrvSbltUnFltr";
BA_ "FlexKomSigLaenge" SG_ 464 DrvSbltUnFltr 3;
BA_ "FlexKomSID" SG_ 464 DrvSbltUnFltr 1814;
BA_ "FlexKomIsMotorola" SG_ 464 DrvSbltUnFltr 1;
BA_ "FlexKomComment" SG_ 464 DrvSbltUnFltr "Drivers seat belt fault status - unfiltered";
BA_ "RID" SG_ 464 ORC_A1_Par "1961";
BA_ "GenSigSNA" SG_ 464 ORC_A1_Par "0h";
BA_ "GenSigSendType" SG_ 464 ORC_A1_Par 5;
BA_ "GenSigCycleTime" SG_ 464 ORC_A1_Par 1000;
BA_ "FlexKomSigStartValue" SG_ 464 ORC_A1_Par "00h";
BA_ "FlexKomSigStartPos" SG_ 464 ORC_A1_Par 7;
BA_ "FlexKomSigName" SG_ 464 ORC_A1_Par "ORC_A1_Par";
BA_ "FlexKomSigLaenge" SG_ 464 ORC_A1_Par 1;
BA_ "FlexKomSID" SG_ 464 ORC_A1_Par 1903;
BA_ "FlexKomIsMotorola" SG_ 464 ORC_A1_Par 1;
BA_ "FlexKomComment" SG_ 464 ORC_A1_Par "ORC_A1 even parity bit";
BA_ "RID" SG_ 464 ORC_A1_Tog "1970";
BA_ "GenSigSNA" SG_ 464 ORC_A1_Tog "0h";
BA_ "GenSigSendType" SG_ 464 ORC_A1_Tog 5;
BA_ "GenSigCycleTime" SG_ 464 ORC_A1_Tog 1000;
BA_ "FlexKomSigStartValue" SG_ 464 ORC_A1_Tog "00h";
BA_ "FlexKomSigStartPos" SG_ 464 ORC_A1_Tog 1;
BA_ "FlexKomSigName" SG_ 464 ORC_A1_Tog "ORC_A1_Tog";
BA_ "FlexKomSigLaenge" SG_ 464 ORC_A1_Tog 1;
BA_ "FlexKomSID" SG_ 464 ORC_A1_Tog 1902;
BA_ "FlexKomIsMotorola" SG_ 464 ORC_A1_Tog 1;
BA_ "FlexKomComment" SG_ 464 ORC_A1_Tog "ORC_A1 toggle bit";
BA_ "RID" SG_ 464 PSG_ODS_STAT "1142";
BA_ "GenSigTimeout_IC" SG_ 464 PSG_ODS_STAT 10500;
BA_ "GenSigTimeout_ETM" SG_ 464 PSG_ODS_STAT 10500;
BA_ "GenSigTimeout_CBC" SG_ 464 PSG_ODS_STAT 10500;
BA_ "GenSigStartValue" SG_ 464 PSG_ODS_STAT 3;
BA_ "GenSigSNA" SG_ 464 PSG_ODS_STAT "3h";
BA_ "GenSigSendType" SG_ 464 PSG_ODS_STAT 5;
BA_ "GenSigCycleTime" SG_ 464 PSG_ODS_STAT 1000;
BA_ "FlexKomSigStartValue" SG_ 464 PSG_ODS_STAT "03h";
BA_ "FlexKomSigStartPos" SG_ 464 PSG_ODS_STAT 27;
BA_ "FlexKomSigName" SG_ 464 PSG_ODS_STAT "PSG_ODS_STAT";
BA_ "FlexKomSigLaenge" SG_ 464 PSG_ODS_STAT 2;
BA_ "FlexKomSID" SG_ 464 PSG_ODS_STAT 426;
BA_ "FlexKomIsMotorola" SG_ 464 PSG_ODS_STAT 1;
BA_ "FlexKomComment" SG_ 464 PSG_ODS_STAT "Passenger Occupant Detection Sensor Status";
BA_ "RID" SG_ 464 PSG_SEATBELT "1160";
BA_ "GenSigTimeout_TBM" SG_ 464 PSG_SEATBELT 10500;
BA_ "GenSigTimeout_IC" SG_ 464 PSG_SEATBELT 10500;
BA_ "GenSigTimeout_ETM" SG_ 464 PSG_SEATBELT 10500;
BA_ "GenSigTimeout_CBC" SG_ 464 PSG_SEATBELT 10500;
BA_ "GenSigStartValue" SG_ 464 PSG_SEATBELT 3;
BA_ "GenSigSNA" SG_ 464 PSG_SEATBELT "3h";
BA_ "GenSigSendType" SG_ 464 PSG_SEATBELT 5;
BA_ "GenSigCycleTime" SG_ 464 PSG_SEATBELT 1000;
BA_ "FlexKomSigStartValue" SG_ 464 PSG_SEATBELT "03h";
BA_ "FlexKomSigStartPos" SG_ 464 PSG_SEATBELT 19;
BA_ "FlexKomSigName" SG_ 464 PSG_SEATBELT "PSG_SEATBELT";
BA_ "FlexKomSigLaenge" SG_ 464 PSG_SEATBELT 2;
BA_ "FlexKomSID" SG_ 464 PSG_SEATBELT 331;
BA_ "FlexKomIsMotorola" SG_ 464 PSG_SEATBELT 1;
BA_ "FlexKomComment" SG_ 464 PSG_SEATBELT "Passengers seat belt status";
BA_ "RID" SG_ 464 PsngrBagChargeSts "5076";
BA_ "GenSigTimeout_IC" SG_ 464 PsngrBagChargeSts 10500;
BA_ "GenSigSNA" SG_ 464 PsngrBagChargeSts "3h";
BA_ "GenSigSendType" SG_ 464 PsngrBagChargeSts 5;
BA_ "GenSigCycleTime" SG_ 464 PsngrBagChargeSts 1000;
BA_ "FlexKomSigStartValue" SG_ 464 PsngrBagChargeSts "00h";
BA_ "FlexKomSigStartPos" SG_ 464 PsngrBagChargeSts 23;
BA_ "FlexKomSigName" SG_ 464 PsngrBagChargeSts "PsngrBagChargeSts";
BA_ "FlexKomSigLaenge" SG_ 464 PsngrBagChargeSts 2;
BA_ "FlexKomSID" SG_ 464 PsngrBagChargeSts 2642;
BA_ "FlexKomIsMotorola" SG_ 464 PsngrBagChargeSts 1;
BA_ "FlexKomComment" SG_ 464 PsngrBagChargeSts "Passenger airbag charge status";
BA_ "RID" SG_ 464 SBRDriverSeatConfigSts "1977";
BA_ "GenSigTimeout_IC" SG_ 464 SBRDriverSeatConfigSts 10500;
BA_ "GenSigSNA" SG_ 464 SBRDriverSeatConfigSts "0h";
BA_ "GenSigSendType" SG_ 464 SBRDriverSeatConfigSts 5;
BA_ "GenSigCycleTime" SG_ 464 SBRDriverSeatConfigSts 1000;
BA_ "FlexKomSigStartValue" SG_ 464 SBRDriverSeatConfigSts "00h";
BA_ "FlexKomSigStartPos" SG_ 464 SBRDriverSeatConfigSts 20;
BA_ "FlexKomSigName" SG_ 464 SBRDriverSeatConfigSts "SBRDriverSeatConfigSts";
BA_ "FlexKomSigLaenge" SG_ 464 SBRDriverSeatConfigSts 1;
BA_ "FlexKomSID" SG_ 464 SBRDriverSeatConfigSts 1967;
BA_ "FlexKomIsMotorola" SG_ 464 SBRDriverSeatConfigSts 1;
BA_ "FlexKomComment" SG_ 464 SBRDriverSeatConfigSts "Driver seatbelt switch configuration; seat checked";
BA_ "RID" SG_ 464 SBRFtPsngrSeatConfigSts "1962";
BA_ "GenSigTimeout_IC" SG_ 464 SBRFtPsngrSeatConfigSts 10500;
BA_ "GenSigSNA" SG_ 464 SBRFtPsngrSeatConfigSts "0h";
BA_ "GenSigSendType" SG_ 464 SBRFtPsngrSeatConfigSts 5;
BA_ "GenSigCycleTime" SG_ 464 SBRFtPsngrSeatConfigSts 1000;
BA_ "FlexKomSigStartValue" SG_ 464 SBRFtPsngrSeatConfigSts "00h";
BA_ "FlexKomSigStartPos" SG_ 464 SBRFtPsngrSeatConfigSts 21;
BA_ "FlexKomSigName" SG_ 464 SBRFtPsngrSeatConfigSts "SBRFtPsngrSeatConfigSts";
BA_ "FlexKomSigLaenge" SG_ 464 SBRFtPsngrSeatConfigSts 1;
BA_ "FlexKomSID" SG_ 464 SBRFtPsngrSeatConfigSts 1966;
BA_ "FlexKomIsMotorola" SG_ 464 SBRFtPsngrSeatConfigSts 1;
BA_ "FlexKomComment" SG_ 464 SBRFtPsngrSeatConfigSts "Front passenger seatbelt switch configuration; sea";
BA_ "RID" SG_ 464 SRS_IndLmp_Rq "1152 6546";
BA_ "GenSigTimeout_TBM" SG_ 464 SRS_IndLmp_Rq 10500;
BA_ "GenSigTimeout_IC" SG_ 464 SRS_IndLmp_Rq 10500;
BA_ "GenSigTimeout_ETM" SG_ 464 SRS_IndLmp_Rq 10500;
BA_ "GenSigTimeout_CBC" SG_ 464 SRS_IndLmp_Rq 5500;
BA_ "GenSigStartValue" SG_ 464 SRS_IndLmp_Rq 1;
BA_ "GenSigSNA" SG_ 464 SRS_IndLmp_Rq "3h";
BA_ "GenSigSendType" SG_ 464 SRS_IndLmp_Rq 5;
BA_ "GenSigCycleTime" SG_ 464 SRS_IndLmp_Rq 1000;
BA_ "FlexKomSigStartValue" SG_ 464 SRS_IndLmp_Rq "01h";
BA_ "FlexKomSigStartPos" SG_ 464 SRS_IndLmp_Rq 3;
BA_ "FlexKomSigName" SG_ 464 SRS_IndLmp_Rq "SRS_IndLmp_Rq";
BA_ "FlexKomSigLaenge" SG_ 464 SRS_IndLmp_Rq 2;
BA_ "FlexKomSID" SG_ 464 SRS_IndLmp_Rq 329;
BA_ "FlexKomIsMotorola" SG_ 464 SRS_IndLmp_Rq 1;
BA_ "FlexKomComment" SG_ 464 SRS_IndLmp_Rq "SRS indication lamp request";
BA_ "RID" SG_ 466 IMPACT_B "1278";
BA_ "GenSigSNA" SG_ 466 IMPACT_B "0h";
BA_ "GenSigSendType" SG_ 466 IMPACT_B 2;
BA_ "GenSigCycleTimeActive" SG_ 466 IMPACT_B 20;
BA_ "FlexKomSigStartValue" SG_ 466 IMPACT_B "0000h";
BA_ "FlexKomSigStartPos" SG_ 466 IMPACT_B 7;
BA_ "FlexKomSigName" SG_ 466 IMPACT_B "IMPACT";
BA_ "FlexKomSigLaenge" SG_ 466 IMPACT_B 16;
BA_ "FlexKomSID" SG_ 466 IMPACT_B 325;
BA_ "FlexKomIsMotorola" SG_ 466 IMPACT_B 1;
BA_ "FlexKomComment" SG_ 466 IMPACT_B "Impact events";
BA_ "RID" SG_ 466 IMPACT_C "1032";
BA_ "GenSigSNA" SG_ 466 IMPACT_C "0h";
BA_ "GenSigSendType" SG_ 466 IMPACT_C 2;
BA_ "GenSigCycleTimeActive" SG_ 466 IMPACT_C 20;
BA_ "FlexKomSigStartValue" SG_ 466 IMPACT_C "0000h";
BA_ "FlexKomSigStartPos" SG_ 466 IMPACT_C 7;
BA_ "FlexKomSigName" SG_ 466 IMPACT_C "IMPACT";
BA_ "FlexKomSigLaenge" SG_ 466 IMPACT_C 16;
BA_ "FlexKomSID" SG_ 466 IMPACT_C 325;
BA_ "FlexKomIsMotorola" SG_ 466 IMPACT_C 1;
BA_ "FlexKomComment" SG_ 466 IMPACT_C "Impact events";
BA_ "RID" SG_ 466 IMPACT_I "1034";
BA_ "GenSigSNA" SG_ 466 IMPACT_I "0h";
BA_ "GenSigSendType" SG_ 466 IMPACT_I 2;
BA_ "GenSigCycleTimeActive" SG_ 466 IMPACT_I 20;
BA_ "FlexKomSigStartValue" SG_ 466 IMPACT_I "0000h";
BA_ "FlexKomSigStartPos" SG_ 466 IMPACT_I 7;
BA_ "FlexKomSigName" SG_ 466 IMPACT_I "IMPACT";
BA_ "FlexKomSigLaenge" SG_ 466 IMPACT_I 16;
BA_ "FlexKomSID" SG_ 466 IMPACT_I 325;
BA_ "FlexKomIsMotorola" SG_ 466 IMPACT_I 1;
BA_ "FlexKomComment" SG_ 466 IMPACT_I "Impact events";
BA_ "RID" SG_ 466 IMPACT_K "1031";
BA_ "GenSigSNA" SG_ 466 IMPACT_K "0h";
BA_ "GenSigSendType" SG_ 466 IMPACT_K 2;
BA_ "GenSigCycleTimeActive" SG_ 466 IMPACT_K 20;
BA_ "FlexKomSigStartValue" SG_ 466 IMPACT_K "0000h";
BA_ "FlexKomSigStartPos" SG_ 466 IMPACT_K 7;
BA_ "FlexKomSigName" SG_ 466 IMPACT_K "IMPACT";
BA_ "FlexKomSigLaenge" SG_ 466 IMPACT_K 16;
BA_ "FlexKomSID" SG_ 466 IMPACT_K 325;
BA_ "FlexKomIsMotorola" SG_ 466 IMPACT_K 1;
BA_ "FlexKomComment" SG_ 466 IMPACT_K "Impact events";
BA_ "RID" SG_ 466 IMPACT_M "1229";
BA_ "GenSigSNA" SG_ 466 IMPACT_M "0h";
BA_ "GenSigSendType" SG_ 466 IMPACT_M 2;
BA_ "GenSigCycleTimeActive" SG_ 466 IMPACT_M 20;
BA_ "FlexKomSigStartValue" SG_ 466 IMPACT_M "0000h";
BA_ "FlexKomSigStartPos" SG_ 466 IMPACT_M 7;
BA_ "FlexKomSigName" SG_ 466 IMPACT_M "IMPACT";
BA_ "FlexKomSigLaenge" SG_ 466 IMPACT_M 16;
BA_ "FlexKomSID" SG_ 466 IMPACT_M 325;
BA_ "FlexKomIsMotorola" SG_ 466 IMPACT_M 1;
BA_ "FlexKomComment" SG_ 466 IMPACT_M "Impact events";
BA_ "RID" SG_ 466 IMPACT_X "1273 2130";
BA_ "GenSigSNA" SG_ 466 IMPACT_X "0h";
BA_ "GenSigSendType" SG_ 466 IMPACT_X 2;
BA_ "GenSigCycleTimeActive" SG_ 466 IMPACT_X 20;
BA_ "FlexKomSigStartValue" SG_ 466 IMPACT_X "0000h";
BA_ "FlexKomSigStartPos" SG_ 466 IMPACT_X 7;
BA_ "FlexKomSigName" SG_ 466 IMPACT_X "IMPACT";
BA_ "FlexKomSigLaenge" SG_ 466 IMPACT_X 16;
BA_ "FlexKomSID" SG_ 466 IMPACT_X 325;
BA_ "FlexKomIsMotorola" SG_ 466 IMPACT_X 1;
BA_ "FlexKomComment" SG_ 466 IMPACT_X "Impact events";
BA_ "RID" SG_ 466 Impact_F "1249";
BA_ "GenSigSNA" SG_ 466 Impact_F "0h";
BA_ "GenSigSendType" SG_ 466 Impact_F 2;
BA_ "GenSigCycleTimeActive" SG_ 466 Impact_F 20;
BA_ "FlexKomSigStartValue" SG_ 466 Impact_F "0000h";
BA_ "FlexKomSigStartPos" SG_ 466 Impact_F 7;
BA_ "FlexKomSigName" SG_ 466 Impact_F "IMPACT";
BA_ "FlexKomSigLaenge" SG_ 466 Impact_F 16;
BA_ "FlexKomSID" SG_ 466 Impact_F 325;
BA_ "FlexKomIsMotorola" SG_ 466 Impact_F 1;
BA_ "FlexKomComment" SG_ 466 Impact_F "Impact events";
BA_ "RID" SG_ 466 Impact_Tgl "1060 2149";
BA_ "GenSigSNA" SG_ 466 Impact_Tgl "0h";
BA_ "GenSigSendType" SG_ 466 Impact_Tgl 2;
BA_ "GenSigCycleTimeActive" SG_ 466 Impact_Tgl 20;
BA_ "FlexKomSigStartValue" SG_ 466 Impact_Tgl "0000h";
BA_ "FlexKomSigStartPos" SG_ 466 Impact_Tgl 7;
BA_ "FlexKomSigName" SG_ 466 Impact_Tgl "IMPACT";
BA_ "FlexKomSigLaenge" SG_ 466 Impact_Tgl 16;
BA_ "FlexKomSID" SG_ 466 Impact_Tgl 325;
BA_ "FlexKomIsMotorola" SG_ 466 Impact_Tgl 1;
BA_ "FlexKomComment" SG_ 466 Impact_Tgl "Impact events";
BA_ "GenSigTimeout_IC" SG_ 599 SBR2RowCentralSeatConfigSts 10500;
BA_ "GenSigSNA" SG_ 599 SBR2RowCentralSeatConfigSts "0h";
BA_ "GenSigSendType" SG_ 599 SBR2RowCentralSeatConfigSts 5;
BA_ "GenSigCycleTime" SG_ 599 SBR2RowCentralSeatConfigSts 1000;
BA_ "FlexKomSigStartValue" SG_ 599 SBR2RowCentralSeatConfigSts "00h";
BA_ "FlexKomSigStartPos" SG_ 599 SBR2RowCentralSeatConfigSts 18;
BA_ "FlexKomSigName" SG_ 599 SBR2RowCentralSeatConfigSts "SBR2RowCentralSeatConfigSts";
BA_ "FlexKomSigLaenge" SG_ 599 SBR2RowCentralSeatConfigSts 1;
BA_ "FlexKomSID" SG_ 599 SBR2RowCentralSeatConfigSts 1975;
BA_ "FlexKomIsMotorola" SG_ 599 SBR2RowCentralSeatConfigSts 1;
BA_ "FlexKomComment" SG_ 599 SBR2RowCentralSeatConfigSts "Second row central seatbelt switch configuration; ";
BA_ "GenSigTimeout_IC" SG_ 599 SBR2RowLeftSeatConfigSts 10500;
BA_ "GenSigSNA" SG_ 599 SBR2RowLeftSeatConfigSts "0h";
BA_ "GenSigSendType" SG_ 599 SBR2RowLeftSeatConfigSts 5;
BA_ "GenSigCycleTime" SG_ 599 SBR2RowLeftSeatConfigSts 1000;
BA_ "FlexKomSigStartValue" SG_ 599 SBR2RowLeftSeatConfigSts "00h";
BA_ "FlexKomSigStartPos" SG_ 599 SBR2RowLeftSeatConfigSts 19;
BA_ "FlexKomSigName" SG_ 599 SBR2RowLeftSeatConfigSts "SBR2RowLeftSeatConfigSts";
BA_ "FlexKomSigLaenge" SG_ 599 SBR2RowLeftSeatConfigSts 1;
BA_ "FlexKomSID" SG_ 599 SBR2RowLeftSeatConfigSts 1976;
BA_ "FlexKomIsMotorola" SG_ 599 SBR2RowLeftSeatConfigSts 1;
BA_ "FlexKomComment" SG_ 599 SBR2RowLeftSeatConfigSts "Second row left seatbelt switch configuration; Sea";
BA_ "GenSigTimeout_IC" SG_ 599 SBR2RowRightSeatConfigSts 10500;
BA_ "GenSigSNA" SG_ 599 SBR2RowRightSeatConfigSts "0h";
BA_ "GenSigSendType" SG_ 599 SBR2RowRightSeatConfigSts 5;
BA_ "GenSigCycleTime" SG_ 599 SBR2RowRightSeatConfigSts 1000;
BA_ "FlexKomSigStartValue" SG_ 599 SBR2RowRightSeatConfigSts "00h";
BA_ "FlexKomSigStartPos" SG_ 599 SBR2RowRightSeatConfigSts 20;
BA_ "FlexKomSigName" SG_ 599 SBR2RowRightSeatConfigSts "SBR2RowRightSeatConfigSts";
BA_ "FlexKomSigLaenge" SG_ 599 SBR2RowRightSeatConfigSts 1;
BA_ "FlexKomSID" SG_ 599 SBR2RowRightSeatConfigSts 1977;
BA_ "FlexKomIsMotorola" SG_ 599 SBR2RowRightSeatConfigSts 1;
BA_ "FlexKomComment" SG_ 599 SBR2RowRightSeatConfigSts "Second row right seatbelt switch configuration; Se";
BA_ "GenSigTimeout_IC" SG_ 599 SBR2ndRowCSeatSts 10500;
BA_ "GenSigStartValue" SG_ 599 SBR2ndRowCSeatSts 6;
BA_ "GenSigSNA" SG_ 599 SBR2ndRowCSeatSts "6h";
BA_ "GenSigSendType" SG_ 599 SBR2ndRowCSeatSts 5;
BA_ "GenSigCycleTime" SG_ 599 SBR2ndRowCSeatSts 1000;
BA_ "FlexKomSigStartValue" SG_ 599 SBR2ndRowCSeatSts "06h";
BA_ "FlexKomSigStartPos" SG_ 599 SBR2ndRowCSeatSts 26;
BA_ "FlexKomSigName" SG_ 599 SBR2ndRowCSeatSts "SBR2ndRowCSeatSts";
BA_ "FlexKomSigLaenge" SG_ 599 SBR2ndRowCSeatSts 3;
BA_ "FlexKomSID" SG_ 599 SBR2ndRowCSeatSts 2766;
BA_ "FlexKomIsMotorola" SG_ 599 SBR2ndRowCSeatSts 1;
BA_ "FlexKomComment" SG_ 599 SBR2ndRowCSeatSts "Second row central seatbelt reminder status";
BA_ "GenSigTimeout_IC" SG_ 599 SBR2ndRowLSeatSts 10500;
BA_ "GenSigStartValue" SG_ 599 SBR2ndRowLSeatSts 6;
BA_ "GenSigSNA" SG_ 599 SBR2ndRowLSeatSts "6h";
BA_ "GenSigSendType" SG_ 599 SBR2ndRowLSeatSts 5;
BA_ "GenSigCycleTime" SG_ 599 SBR2ndRowLSeatSts 1000;
BA_ "FlexKomSigStartValue" SG_ 599 SBR2ndRowLSeatSts "06h";
BA_ "FlexKomSigStartPos" SG_ 599 SBR2ndRowLSeatSts 29;
BA_ "FlexKomSigName" SG_ 599 SBR2ndRowLSeatSts "SBR2ndRowLSeatSts";
BA_ "FlexKomSigLaenge" SG_ 599 SBR2ndRowLSeatSts 3;
BA_ "FlexKomSID" SG_ 599 SBR2ndRowLSeatSts 2767;
BA_ "FlexKomIsMotorola" SG_ 599 SBR2ndRowLSeatSts 1;
BA_ "FlexKomComment" SG_ 599 SBR2ndRowLSeatSts "Second row left seatbelt reminder status";
BA_ "GenSigTimeout_IC" SG_ 599 SBR2ndRowRSeatSts 10500;
BA_ "GenSigStartValue" SG_ 599 SBR2ndRowRSeatSts 6;
BA_ "GenSigSNA" SG_ 599 SBR2ndRowRSeatSts "6h";
BA_ "GenSigSendType" SG_ 599 SBR2ndRowRSeatSts 5;
BA_ "GenSigCycleTime" SG_ 599 SBR2ndRowRSeatSts 1000;
BA_ "FlexKomSigStartValue" SG_ 599 SBR2ndRowRSeatSts "06h";
BA_ "FlexKomSigStartPos" SG_ 599 SBR2ndRowRSeatSts 34;
BA_ "FlexKomSigName" SG_ 599 SBR2ndRowRSeatSts "SBR2ndRowRSeatSts";
BA_ "FlexKomSigLaenge" SG_ 599 SBR2ndRowRSeatSts 3;
BA_ "FlexKomSID" SG_ 599 SBR2ndRowRSeatSts 2768;
BA_ "FlexKomIsMotorola" SG_ 599 SBR2ndRowRSeatSts 1;
BA_ "FlexKomComment" SG_ 599 SBR2ndRowRSeatSts "Second row right seatbelt reminder status";
BA_ "GenSigSNA" SG_ 469 ORC_Health "0h";
BA_ "GenSigSendType" SG_ 469 ORC_Health 5;
BA_ "GenSigCycleTime" SG_ 469 ORC_Health 250;
BA_ "FlexKomSigStartValue" SG_ 469 ORC_Health "0000000000000000h";
BA_ "FlexKomSigStartPos" SG_ 469 ORC_Health 7;
BA_ "FlexKomSigName" SG_ 469 ORC_Health "ORC_A4_Pkt";
BA_ "FlexKomSigLaenge" SG_ 469 ORC_Health 64;
BA_ "FlexKomSID" SG_ 469 ORC_Health 2442;
BA_ "FlexKomIsMotorola" SG_ 469 ORC_Health 1;
BA_ "FlexKomComment" SG_ 469 ORC_Health "ORC A4 packet";
BA_ "GenSigSNA" SG_ 43 AXSStat "0h";
BA_ "GenSigCycleTime" SG_ 43 AXSStat 10;
BA_ "FlexKomSigStartValue" SG_ 43 AXSStat "000000000FFF00FFh";
BA_ "FlexKomSigStartPos" SG_ 43 AXSStat 7;
BA_ "FlexKomSigName" SG_ 43 AXSStat "ORC_YRS_PKT";
BA_ "FlexKomSigLaenge" SG_ 43 AXSStat 64;
BA_ "FlexKomSID" SG_ 43 AXSStat 1587;
BA_ "FlexKomIsMotorola" SG_ 43 AXSStat 1;
BA_ "FlexKomComment" SG_ 43 AXSStat "Accelerometer data packet";
BA_ "GenSigSNA" SG_ 43 AYSStat "0h";
BA_ "GenSigCycleTime" SG_ 43 AYSStat 10;
BA_ "FlexKomSigStartValue" SG_ 43 AYSStat "000000000FFF00FFh";
BA_ "FlexKomSigStartPos" SG_ 43 AYSStat 7;
BA_ "FlexKomSigName" SG_ 43 AYSStat "ORC_YRS_PKT";
BA_ "FlexKomSigLaenge" SG_ 43 AYSStat 64;
BA_ "FlexKomSID" SG_ 43 AYSStat 1587;
BA_ "FlexKomIsMotorola" SG_ 43 AYSStat 1;
BA_ "FlexKomComment" SG_ 43 AYSStat "Accelerometer data packet";
BA_ "GenSigStartValue" SG_ 43 CRC_ORC_YRS_DATA 255;
BA_ "GenSigSNA" SG_ 43 CRC_ORC_YRS_DATA "FFh";
BA_ "GenSigCycleTime" SG_ 43 CRC_ORC_YRS_DATA 10;
BA_ "FlexKomSigStartValue" SG_ 43 CRC_ORC_YRS_DATA "000000000FFF00FFh";
BA_ "FlexKomSigStartPos" SG_ 43 CRC_ORC_YRS_DATA 7;
BA_ "FlexKomSigName" SG_ 43 CRC_ORC_YRS_DATA "ORC_YRS_PKT";
BA_ "FlexKomSigLaenge" SG_ 43 CRC_ORC_YRS_DATA 64;
BA_ "FlexKomSID" SG_ 43 CRC_ORC_YRS_DATA 1587;
BA_ "FlexKomIsMotorola" SG_ 43 CRC_ORC_YRS_DATA 1;
BA_ "FlexKomComment" SG_ 43 CRC_ORC_YRS_DATA "Accelerometer data packet";
BA_ "GenSigSNA" SG_ 43 InternalError "0h";
BA_ "GenSigCycleTime" SG_ 43 InternalError 10;
BA_ "FlexKomSigStartValue" SG_ 43 InternalError "000000000FFF00FFh";
BA_ "FlexKomSigStartPos" SG_ 43 InternalError 7;
BA_ "FlexKomSigName" SG_ 43 InternalError "ORC_YRS_PKT";
BA_ "FlexKomSigLaenge" SG_ 43 InternalError 64;
BA_ "FlexKomSID" SG_ 43 InternalError 1587;
BA_ "FlexKomIsMotorola" SG_ 43 InternalError 1;
BA_ "FlexKomComment" SG_ 43 InternalError "Accelerometer data packet";
BA_ "GenSigSNA" SG_ 43 LatAcceleration "FFFh";
BA_ "GenSigCycleTime" SG_ 43 LatAcceleration 10;
BA_ "FlexKomSigStartValue" SG_ 43 LatAcceleration "000000000FFF00FFh";
BA_ "FlexKomSigStartPos" SG_ 43 LatAcceleration 7;
BA_ "FlexKomSigName" SG_ 43 LatAcceleration "ORC_YRS_PKT";
BA_ "FlexKomSigLaenge" SG_ 43 LatAcceleration 64;
BA_ "FlexKomSID" SG_ 43 LatAcceleration 1587;
BA_ "FlexKomIsMotorola" SG_ 43 LatAcceleration 1;
BA_ "FlexKomComment" SG_ 43 LatAcceleration "Accelerometer data packet";
BA_ "GenSigSNA" SG_ 43 LongAcceleration "FFFh";
BA_ "GenSigCycleTime" SG_ 43 LongAcceleration 10;
BA_ "FlexKomSigStartValue" SG_ 43 LongAcceleration "000000000FFF00FFh";
BA_ "FlexKomSigStartPos" SG_ 43 LongAcceleration 7;
BA_ "FlexKomSigName" SG_ 43 LongAcceleration "ORC_YRS_PKT";
BA_ "FlexKomSigLaenge" SG_ 43 LongAcceleration 64;
BA_ "FlexKomSID" SG_ 43 LongAcceleration 1587;
BA_ "FlexKomIsMotorola" SG_ 43 LongAcceleration 1;
BA_ "FlexKomComment" SG_ 43 LongAcceleration "Accelerometer data packet";
BA_ "GenSigSNA" SG_ 43 MC_ORC_YRS_DATA "0h";
BA_ "GenSigCycleTime" SG_ 43 MC_ORC_YRS_DATA 10;
BA_ "FlexKomSigStartValue" SG_ 43 MC_ORC_YRS_DATA "000000000FFF00FFh";
BA_ "FlexKomSigStartPos" SG_ 43 MC_ORC_YRS_DATA 7;
BA_ "FlexKomSigName" SG_ 43 MC_ORC_YRS_DATA "ORC_YRS_PKT";
BA_ "FlexKomSigLaenge" SG_ 43 MC_ORC_YRS_DATA 64;
BA_ "FlexKomSID" SG_ 43 MC_ORC_YRS_DATA 1587;
BA_ "FlexKomIsMotorola" SG_ 43 MC_ORC_YRS_DATA 1;
BA_ "FlexKomComment" SG_ 43 MC_ORC_YRS_DATA "Accelerometer data packet";
BA_ "GenSigSNA" SG_ 43 VoltageError "0h";
BA_ "GenSigCycleTime" SG_ 43 VoltageError 10;
BA_ "FlexKomSigStartValue" SG_ 43 VoltageError "000000000FFF00FFh";
BA_ "FlexKomSigStartPos" SG_ 43 VoltageError 7;
BA_ "FlexKomSigName" SG_ 43 VoltageError "ORC_YRS_PKT";
BA_ "FlexKomSigLaenge" SG_ 43 VoltageError 64;
BA_ "FlexKomSID" SG_ 43 VoltageError 1587;
BA_ "FlexKomIsMotorola" SG_ 43 VoltageError 1;
BA_ "FlexKomComment" SG_ 43 VoltageError "Accelerometer data packet";
BA_ "GenSigSNA" SG_ 43 YRSStat "0h";
BA_ "GenSigCycleTime" SG_ 43 YRSStat 10;
BA_ "FlexKomSigStartValue" SG_ 43 YRSStat "000000000FFF00FFh";
BA_ "FlexKomSigStartPos" SG_ 43 YRSStat 7;
BA_ "FlexKomSigName" SG_ 43 YRSStat "ORC_YRS_PKT";
BA_ "FlexKomSigLaenge" SG_ 43 YRSStat 64;
BA_ "FlexKomSID" SG_ 43 YRSStat 1587;
BA_ "FlexKomIsMotorola" SG_ 43 YRSStat 1;
BA_ "FlexKomComment" SG_ 43 YRSStat "Accelerometer data packet";
BA_ "GenSigStartValue" SG_ 43 YawRate 4095;
BA_ "GenSigSNA" SG_ 43 YawRate "FFFh";
BA_ "GenSigCycleTime" SG_ 43 YawRate 10;
BA_ "FlexKomSigStartValue" SG_ 43 YawRate "000000000FFF00FFh";
BA_ "FlexKomSigStartPos" SG_ 43 YawRate 7;
BA_ "FlexKomSigName" SG_ 43 YawRate "ORC_YRS_PKT";
BA_ "FlexKomSigLaenge" SG_ 43 YawRate 64;
BA_ "FlexKomSID" SG_ 43 YawRate 1587;
BA_ "FlexKomIsMotorola" SG_ 43 YawRate 1;
BA_ "FlexKomComment" SG_ 43 YawRate "Accelerometer data packet";
BA_ "GenSigSNA" SG_ 305 BlockOffset "0h";
BA_ "GenSigSendType" SG_ 305 BlockOffset 9;
BA_ "GenSigCycleTime" SG_ 305 BlockOffset 100;
BA_ "FlexKomSigStartValue" SG_ 305 BlockOffset "0000000000000000h";
BA_ "FlexKomSigStartPos" SG_ 305 BlockOffset 7;
BA_ "FlexKomSigName" SG_ 305 BlockOffset "ORC_YRS_INFO";
BA_ "FlexKomSigLaenge" SG_ 305 BlockOffset 64;
BA_ "FlexKomSID" SG_ 305 BlockOffset 1588;
BA_ "FlexKomIsMotorola" SG_ 305 BlockOffset 1;
BA_ "FlexKomComment" SG_ 305 BlockOffset "Traceability - part number information packet";
BA_ "GenSigSNA" SG_ 305 CLUType "0h";
BA_ "GenSigSendType" SG_ 305 CLUType 9;
BA_ "GenSigCycleTime" SG_ 305 CLUType 100;
BA_ "FlexKomSigStartValue" SG_ 305 CLUType "0000000000000000h";
BA_ "FlexKomSigStartPos" SG_ 305 CLUType 7;
BA_ "FlexKomSigName" SG_ 305 CLUType "ORC_YRS_INFO";
BA_ "FlexKomSigLaenge" SG_ 305 CLUType 64;
BA_ "FlexKomSID" SG_ 305 CLUType 1588;
BA_ "FlexKomIsMotorola" SG_ 305 CLUType 1;
BA_ "FlexKomComment" SG_ 305 CLUType "Traceability - part number information packet";
BA_ "GenSigSNA" SG_ 305 Character0 "0h";
BA_ "GenSigSendType" SG_ 305 Character0 9;
BA_ "GenSigCycleTime" SG_ 305 Character0 100;
BA_ "FlexKomSigStartValue" SG_ 305 Character0 "0000000000000000h";
BA_ "FlexKomSigStartPos" SG_ 305 Character0 7;
BA_ "FlexKomSigName" SG_ 305 Character0 "ORC_YRS_INFO";
BA_ "FlexKomSigLaenge" SG_ 305 Character0 64;
BA_ "FlexKomSID" SG_ 305 Character0 1588;
BA_ "FlexKomIsMotorola" SG_ 305 Character0 1;
BA_ "FlexKomComment" SG_ 305 Character0 "Traceability - part number information packet";
BA_ "GenSigSNA" SG_ 305 Character1 "0h";
BA_ "GenSigSendType" SG_ 305 Character1 9;
BA_ "GenSigCycleTime" SG_ 305 Character1 100;
BA_ "FlexKomSigStartValue" SG_ 305 Character1 "0000000000000000h";
BA_ "FlexKomSigStartPos" SG_ 305 Character1 7;
BA_ "FlexKomSigName" SG_ 305 Character1 "ORC_YRS_INFO";
BA_ "FlexKomSigLaenge" SG_ 305 Character1 64;
BA_ "FlexKomSID" SG_ 305 Character1 1588;
BA_ "FlexKomIsMotorola" SG_ 305 Character1 1;
BA_ "FlexKomComment" SG_ 305 Character1 "Traceability - part number information packet";
BA_ "GenSigSNA" SG_ 305 Character2 "0h";
BA_ "GenSigSendType" SG_ 305 Character2 9;
BA_ "GenSigCycleTime" SG_ 305 Character2 100;
BA_ "FlexKomSigStartValue" SG_ 305 Character2 "0000000000000000h";
BA_ "FlexKomSigStartPos" SG_ 305 Character2 7;
BA_ "FlexKomSigName" SG_ 305 Character2 "ORC_YRS_INFO";
BA_ "FlexKomSigLaenge" SG_ 305 Character2 64;
BA_ "FlexKomSID" SG_ 305 Character2 1588;
BA_ "FlexKomIsMotorola" SG_ 305 Character2 1;
BA_ "FlexKomComment" SG_ 305 Character2 "Traceability - part number information packet";
BA_ "GenSigSNA" SG_ 305 Character3 "0h";
BA_ "GenSigSendType" SG_ 305 Character3 9;
BA_ "GenSigCycleTime" SG_ 305 Character3 100;
BA_ "FlexKomSigStartValue" SG_ 305 Character3 "0000000000000000h";
BA_ "FlexKomSigStartPos" SG_ 305 Character3 7;
BA_ "FlexKomSigName" SG_ 305 Character3 "ORC_YRS_INFO";
BA_ "FlexKomSigLaenge" SG_ 305 Character3 64;
BA_ "FlexKomSID" SG_ 305 Character3 1588;
BA_ "FlexKomIsMotorola" SG_ 305 Character3 1;
BA_ "FlexKomComment" SG_ 305 Character3 "Traceability - part number information packet";
BA_ "GenSigSNA" SG_ 305 Character4 "0h";
BA_ "GenSigSendType" SG_ 305 Character4 9;
BA_ "GenSigCycleTime" SG_ 305 Character4 100;
BA_ "FlexKomSigStartValue" SG_ 305 Character4 "0000000000000000h";
BA_ "FlexKomSigStartPos" SG_ 305 Character4 7;
BA_ "FlexKomSigName" SG_ 305 Character4 "ORC_YRS_INFO";
BA_ "FlexKomSigLaenge" SG_ 305 Character4 64;
BA_ "FlexKomSID" SG_ 305 Character4 1588;
BA_ "FlexKomIsMotorola" SG_ 305 Character4 1;
BA_ "FlexKomComment" SG_ 305 Character4 "Traceability - part number information packet";
BA_ "GenSigSNA" SG_ 305 Character5 "0h";
BA_ "GenSigSendType" SG_ 305 Character5 9;
BA_ "GenSigCycleTime" SG_ 305 Character5 100;
BA_ "FlexKomSigStartValue" SG_ 305 Character5 "0000000000000000h";
BA_ "FlexKomSigStartPos" SG_ 305 Character5 7;
BA_ "FlexKomSigName" SG_ 305 Character5 "ORC_YRS_INFO";
BA_ "FlexKomSigLaenge" SG_ 305 Character5 64;
BA_ "FlexKomSID" SG_ 305 Character5 1588;
BA_ "FlexKomIsMotorola" SG_ 305 Character5 1;
BA_ "FlexKomComment" SG_ 305 Character5 "Traceability - part number information packet";
BA_ "GenSigSNA" SG_ 305 PTRInfo "0h";
BA_ "GenSigSendType" SG_ 305 PTRInfo 9;
BA_ "GenSigCycleTime" SG_ 305 PTRInfo 100;
BA_ "FlexKomSigStartValue" SG_ 305 PTRInfo "0000000000000000h";
BA_ "FlexKomSigStartPos" SG_ 305 PTRInfo 7;
BA_ "FlexKomSigName" SG_ 305 PTRInfo "ORC_YRS_INFO";
BA_ "FlexKomSigLaenge" SG_ 305 PTRInfo 64;
BA_ "FlexKomSID" SG_ 305 PTRInfo 1588;
BA_ "FlexKomIsMotorola" SG_ 305 PTRInfo 1;
BA_ "FlexKomComment" SG_ 305 PTRInfo "Traceability - part number information packet";
BA_ "GenSigTimeout_ORC" SG_ 334 ApplyTrq 350;
BA_ "GenSigSNA" SG_ 334 ApplyTrq "0h";
BA_ "GenSigCycleTime" SG_ 334 ApplyTrq 100;
BA_ "FlexKomSigStartValue" SG_ 334 ApplyTrq "00FFFFFFFFFFFFFFh";
BA_ "FlexKomSigStartPos" SG_ 334 ApplyTrq 7;
BA_ "FlexKomSigName" SG_ 334 ApplyTrq "EDR_Pkt";
BA_ "FlexKomSigLaenge" SG_ 334 ApplyTrq 64;
BA_ "FlexKomSID" SG_ 334 ApplyTrq 762;
BA_ "FlexKomIsMotorola" SG_ 334 ApplyTrq 1;
BA_ "FlexKomComment" SG_ 334 ApplyTrq "EDR Only information packet";
BA_ "GenSigSNA" SG_ 334 BrkSw1Stat "0h";
BA_ "GenSigCycleTime" SG_ 334 BrkSw1Stat 100;
BA_ "FlexKomSigStartValue" SG_ 334 BrkSw1Stat "00FFFFFFFFFFFFFFh";
BA_ "FlexKomSigStartPos" SG_ 334 BrkSw1Stat 7;
BA_ "FlexKomSigName" SG_ 334 BrkSw1Stat "EDR_Pkt";
BA_ "FlexKomSigLaenge" SG_ 334 BrkSw1Stat 64;
BA_ "FlexKomSID" SG_ 334 BrkSw1Stat 762;
BA_ "FlexKomIsMotorola" SG_ 334 BrkSw1Stat 1;
BA_ "FlexKomComment" SG_ 334 BrkSw1Stat "EDR Only information packet";
BA_ "GenSigTimeout_ORC" SG_ 334 CruiseEGD 350;
BA_ "GenSigSNA" SG_ 334 CruiseEGD "0h";
BA_ "GenSigCycleTime" SG_ 334 CruiseEGD 100;
BA_ "FlexKomSigStartValue" SG_ 334 CruiseEGD "00FFFFFFFFFFFFFFh";
BA_ "FlexKomSigStartPos" SG_ 334 CruiseEGD 7;
BA_ "FlexKomSigName" SG_ 334 CruiseEGD "EDR_Pkt";
BA_ "FlexKomSigLaenge" SG_ 334 CruiseEGD 64;
BA_ "FlexKomSID" SG_ 334 CruiseEGD 762;
BA_ "FlexKomIsMotorola" SG_ 334 CruiseEGD 1;
BA_ "FlexKomComment" SG_ 334 CruiseEGD "EDR Only information packet";
BA_ "GenSigTimeout_ORC" SG_ 334 ESP_TrqRqEnabl 350;
BA_ "GenSigSNA" SG_ 334 ESP_TrqRqEnabl "0h";
BA_ "GenSigCycleTime" SG_ 334 ESP_TrqRqEnabl 100;
BA_ "FlexKomSigStartValue" SG_ 334 ESP_TrqRqEnabl "00FFFFFFFFFFFFFFh";
BA_ "FlexKomSigStartPos" SG_ 334 ESP_TrqRqEnabl 7;
BA_ "FlexKomSigName" SG_ 334 ESP_TrqRqEnabl "EDR_Pkt";
BA_ "FlexKomSigLaenge" SG_ 334 ESP_TrqRqEnabl 64;
BA_ "FlexKomSID" SG_ 334 ESP_TrqRqEnabl 762;
BA_ "FlexKomIsMotorola" SG_ 334 ESP_TrqRqEnabl 1;
BA_ "FlexKomComment" SG_ 334 ESP_TrqRqEnabl "EDR Only information packet";
BA_ "GenSigTimeout_ORC" SG_ 334 ETC_LmpFlash 350;
BA_ "GenSigSNA" SG_ 334 ETC_LmpFlash "0h";
BA_ "GenSigCycleTime" SG_ 334 ETC_LmpFlash 100;
BA_ "FlexKomSigStartValue" SG_ 334 ETC_LmpFlash "00FFFFFFFFFFFFFFh";
BA_ "FlexKomSigStartPos" SG_ 334 ETC_LmpFlash 7;
BA_ "FlexKomSigName" SG_ 334 ETC_LmpFlash "EDR_Pkt";
BA_ "FlexKomSigLaenge" SG_ 334 ETC_LmpFlash 64;
BA_ "FlexKomSID" SG_ 334 ETC_LmpFlash 762;
BA_ "FlexKomIsMotorola" SG_ 334 ETC_LmpFlash 1;
BA_ "FlexKomComment" SG_ 334 ETC_LmpFlash "EDR Only information packet";
BA_ "GenSigTimeout_ORC" SG_ 334 ETC_LmpOn 350;
BA_ "GenSigSNA" SG_ 334 ETC_LmpOn "0h";
BA_ "GenSigCycleTime" SG_ 334 ETC_LmpOn 100;
BA_ "FlexKomSigStartValue" SG_ 334 ETC_LmpOn "00FFFFFFFFFFFFFFh";
BA_ "FlexKomSigStartPos" SG_ 334 ETC_LmpOn 7;
BA_ "FlexKomSigName" SG_ 334 ETC_LmpOn "EDR_Pkt";
BA_ "FlexKomSigLaenge" SG_ 334 ETC_LmpOn 64;
BA_ "FlexKomSID" SG_ 334 ETC_LmpOn 762;
BA_ "FlexKomIsMotorola" SG_ 334 ETC_LmpOn 1;
BA_ "FlexKomComment" SG_ 334 ETC_LmpOn "EDR Only information packet";
BA_ "GenSigTimeout_ORC" SG_ 334 Lv1CrsCtrlOff 350;
BA_ "GenSigSNA" SG_ 334 Lv1CrsCtrlOff "0h";
BA_ "GenSigCycleTime" SG_ 334 Lv1CrsCtrlOff 100;
BA_ "FlexKomSigStartValue" SG_ 334 Lv1CrsCtrlOff "00FFFFFFFFFFFFFFh";
BA_ "FlexKomSigStartPos" SG_ 334 Lv1CrsCtrlOff 7;
BA_ "FlexKomSigName" SG_ 334 Lv1CrsCtrlOff "EDR_Pkt";
BA_ "FlexKomSigLaenge" SG_ 334 Lv1CrsCtrlOff 64;
BA_ "FlexKomSID" SG_ 334 Lv1CrsCtrlOff 762;
BA_ "FlexKomIsMotorola" SG_ 334 Lv1CrsCtrlOff 1;
BA_ "FlexKomComment" SG_ 334 Lv1CrsCtrlOff "EDR Only information packet";
BA_ "GenSigTimeout_ORC" SG_ 334 MAP 350;
BA_ "GenSigStartValue" SG_ 334 MAP 255;
BA_ "GenSigSNA" SG_ 334 MAP "FFh";
BA_ "GenSigCycleTime" SG_ 334 MAP 100;
BA_ "FlexKomSigStartValue" SG_ 334 MAP "00FFFFFFFFFFFFFFh";
BA_ "FlexKomSigStartPos" SG_ 334 MAP 7;
BA_ "FlexKomSigName" SG_ 334 MAP "EDR_Pkt";
BA_ "FlexKomSigLaenge" SG_ 334 MAP 64;
BA_ "FlexKomSID" SG_ 334 MAP 762;
BA_ "FlexKomIsMotorola" SG_ 334 MAP 1;
BA_ "FlexKomComment" SG_ 334 MAP "EDR Only information packet";
BA_ "GenSigTimeout_ORC" SG_ 334 RawPVS1 350;
BA_ "GenSigStartValue" SG_ 334 RawPVS1 255;
BA_ "GenSigSNA" SG_ 334 RawPVS1 "FFh";
BA_ "GenSigCycleTime" SG_ 334 RawPVS1 100;
BA_ "FlexKomSigStartValue" SG_ 334 RawPVS1 "00FFFFFFFFFFFFFFh";
BA_ "FlexKomSigStartPos" SG_ 334 RawPVS1 7;
BA_ "FlexKomSigName" SG_ 334 RawPVS1 "EDR_Pkt";
BA_ "FlexKomSigLaenge" SG_ 334 RawPVS1 64;
BA_ "FlexKomSID" SG_ 334 RawPVS1 762;
BA_ "FlexKomIsMotorola" SG_ 334 RawPVS1 1;
BA_ "FlexKomComment" SG_ 334 RawPVS1 "EDR Only information packet";
BA_ "GenSigTimeout_ORC" SG_ 334 RawPVS2 350;
BA_ "GenSigStartValue" SG_ 334 RawPVS2 255;
BA_ "GenSigSNA" SG_ 334 RawPVS2 "FFh";
BA_ "GenSigCycleTime" SG_ 334 RawPVS2 100;
BA_ "FlexKomSigStartValue" SG_ 334 RawPVS2 "00FFFFFFFFFFFFFFh";
BA_ "FlexKomSigStartPos" SG_ 334 RawPVS2 7;
BA_ "FlexKomSigName" SG_ 334 RawPVS2 "EDR_Pkt";
BA_ "FlexKomSigLaenge" SG_ 334 RawPVS2 64;
BA_ "FlexKomSID" SG_ 334 RawPVS2 762;
BA_ "FlexKomIsMotorola" SG_ 334 RawPVS2 1;
BA_ "FlexKomComment" SG_ 334 RawPVS2 "EDR Only information packet";
BA_ "GenSigTimeout_ORC" SG_ 334 RawTPS1 350;
BA_ "GenSigStartValue" SG_ 334 RawTPS1 255;
BA_ "GenSigSNA" SG_ 334 RawTPS1 "FFh";
BA_ "GenSigCycleTime" SG_ 334 RawTPS1 100;
BA_ "FlexKomSigStartValue" SG_ 334 RawTPS1 "00FFFFFFFFFFFFFFh";
BA_ "FlexKomSigStartPos" SG_ 334 RawTPS1 7;
BA_ "FlexKomSigName" SG_ 334 RawTPS1 "EDR_Pkt";
BA_ "FlexKomSigLaenge" SG_ 334 RawTPS1 64;
BA_ "FlexKomSID" SG_ 334 RawTPS1 762;
BA_ "FlexKomIsMotorola" SG_ 334 RawTPS1 1;
BA_ "FlexKomComment" SG_ 334 RawTPS1 "EDR Only information packet";
BA_ "GenSigTimeout_ORC" SG_ 334 RawTPS2 350;
BA_ "GenSigStartValue" SG_ 334 RawTPS2 255;
BA_ "GenSigSNA" SG_ 334 RawTPS2 "FFh";
BA_ "GenSigCycleTime" SG_ 334 RawTPS2 100;
BA_ "FlexKomSigStartValue" SG_ 334 RawTPS2 "00FFFFFFFFFFFFFFh";
BA_ "FlexKomSigStartPos" SG_ 334 RawTPS2 7;
BA_ "FlexKomSigName" SG_ 334 RawTPS2 "EDR_Pkt";
BA_ "FlexKomSigLaenge" SG_ 334 RawTPS2 64;
BA_ "FlexKomSID" SG_ 334 RawTPS2 762;
BA_ "FlexKomIsMotorola" SG_ 334 RawTPS2 1;
BA_ "FlexKomComment" SG_ 334 RawTPS2 "EDR Only information packet";
BA_ "GenSigTimeout_ORC" SG_ 334 RelativePdl 350;
BA_ "GenSigStartValue" SG_ 334 RelativePdl 255;
BA_ "GenSigSNA" SG_ 334 RelativePdl "FFh";
BA_ "GenSigCycleTime" SG_ 334 RelativePdl 100;
BA_ "FlexKomSigStartValue" SG_ 334 RelativePdl "00FFFFFFFFFFFFFFh";
BA_ "FlexKomSigStartPos" SG_ 334 RelativePdl 7;
BA_ "FlexKomSigName" SG_ 334 RelativePdl "EDR_Pkt";
BA_ "FlexKomSigLaenge" SG_ 334 RelativePdl 64;
BA_ "FlexKomSID" SG_ 334 RelativePdl 762;
BA_ "FlexKomIsMotorola" SG_ 334 RelativePdl 1;
BA_ "FlexKomComment" SG_ 334 RelativePdl "EDR Only information packet";
BA_ "GenSigTimeout_ORC" SG_ 334 RelativeThrt 350;
BA_ "GenSigStartValue" SG_ 334 RelativeThrt 255;
BA_ "GenSigSNA" SG_ 334 RelativeThrt "FFh";
BA_ "GenSigCycleTime" SG_ 334 RelativeThrt 100;
BA_ "FlexKomSigStartValue" SG_ 334 RelativeThrt "00FFFFFFFFFFFFFFh";
BA_ "FlexKomSigStartPos" SG_ 334 RelativeThrt 7;
BA_ "FlexKomSigName" SG_ 334 RelativeThrt "EDR_Pkt";
BA_ "FlexKomSigLaenge" SG_ 334 RelativeThrt 64;
BA_ "FlexKomSID" SG_ 334 RelativeThrt 762;
BA_ "FlexKomIsMotorola" SG_ 334 RelativeThrt 1;
BA_ "FlexKomComment" SG_ 334 RelativeThrt "EDR Only information packet";
BA_ "GenSigTimeout_ORC" SG_ 333 GF_Charge 350;
BA_ "GenSigSNA" SG_ 333 GF_Charge "FFFFh";
BA_ "GenSigCycleTime" SG_ 333 GF_Charge 100;
BA_ "FlexKomSigStartValue" SG_ 333 GF_Charge "FFFFFFFF0000FF00h";
BA_ "FlexKomSigStartPos" SG_ 333 GF_Charge 7;
BA_ "FlexKomSigName" SG_ 333 GF_Charge "EDR2_Pkt";
BA_ "FlexKomSigLaenge" SG_ 333 GF_Charge 64;
BA_ "FlexKomSID" SG_ 333 GF_Charge 1093;
BA_ "FlexKomIsMotorola" SG_ 333 GF_Charge 1;
BA_ "FlexKomComment" SG_ 333 GF_Charge "EDR2 information packet only";
BA_ "GenSigTimeout_ORC" SG_ 333 RelativeThrtPct 350;
BA_ "GenSigStartValue" SG_ 333 RelativeThrtPct 255;
BA_ "GenSigSNA" SG_ 333 RelativeThrtPct "FFh";
BA_ "GenSigCycleTime" SG_ 333 RelativeThrtPct 100;
BA_ "FlexKomSigStartValue" SG_ 333 RelativeThrtPct "FFFFFFFF0000FF00h";
BA_ "FlexKomSigStartPos" SG_ 333 RelativeThrtPct 7;
BA_ "FlexKomSigName" SG_ 333 RelativeThrtPct "EDR2_Pkt";
BA_ "FlexKomSigLaenge" SG_ 333 RelativeThrtPct 64;
BA_ "FlexKomSID" SG_ 333 RelativeThrtPct 1093;
BA_ "FlexKomIsMotorola" SG_ 333 RelativeThrtPct 1;
BA_ "FlexKomComment" SG_ 333 RelativeThrtPct "EDR2 information packet only";
BA_ "GenSigTimeout_ORC" SG_ 333 VVT_ExhCam1Pos 350;
BA_ "GenSigStartValue" SG_ 333 VVT_ExhCam1Pos 255;
BA_ "GenSigSNA" SG_ 333 VVT_ExhCam1Pos "0h";
BA_ "GenSigCycleTime" SG_ 333 VVT_ExhCam1Pos 100;
BA_ "FlexKomSigStartValue" SG_ 333 VVT_ExhCam1Pos "FFFFFFFF0000FF00h";
BA_ "FlexKomSigStartPos" SG_ 333 VVT_ExhCam1Pos 7;
BA_ "FlexKomSigName" SG_ 333 VVT_ExhCam1Pos "EDR2_Pkt";
BA_ "FlexKomSigLaenge" SG_ 333 VVT_ExhCam1Pos 64;
BA_ "FlexKomSID" SG_ 333 VVT_ExhCam1Pos 1093;
BA_ "FlexKomIsMotorola" SG_ 333 VVT_ExhCam1Pos 1;
BA_ "FlexKomComment" SG_ 333 VVT_ExhCam1Pos "EDR2 information packet only";
BA_ "GenSigTimeout_ORC" SG_ 333 VVT_ExhCam2Pos 350;
BA_ "GenSigStartValue" SG_ 333 VVT_ExhCam2Pos 255;
BA_ "GenSigSNA" SG_ 333 VVT_ExhCam2Pos "0h";
BA_ "GenSigCycleTime" SG_ 333 VVT_ExhCam2Pos 100;
BA_ "FlexKomSigStartValue" SG_ 333 VVT_ExhCam2Pos "FFFFFFFF0000FF00h";
BA_ "FlexKomSigStartPos" SG_ 333 VVT_ExhCam2Pos 7;
BA_ "FlexKomSigName" SG_ 333 VVT_ExhCam2Pos "EDR2_Pkt";
BA_ "FlexKomSigLaenge" SG_ 333 VVT_ExhCam2Pos 64;
BA_ "FlexKomSID" SG_ 333 VVT_ExhCam2Pos 1093;
BA_ "FlexKomIsMotorola" SG_ 333 VVT_ExhCam2Pos 1;
BA_ "FlexKomComment" SG_ 333 VVT_ExhCam2Pos "EDR2 information packet only";
BA_ "GenSigTimeout_ORC" SG_ 333 VVT_IntCam1Pos 350;
BA_ "GenSigStartValue" SG_ 333 VVT_IntCam1Pos 255;
BA_ "GenSigSNA" SG_ 333 VVT_IntCam1Pos "0h";
BA_ "GenSigCycleTime" SG_ 333 VVT_IntCam1Pos 100;
BA_ "FlexKomSigStartValue" SG_ 333 VVT_IntCam1Pos "FFFFFFFF0000FF00h";
BA_ "FlexKomSigStartPos" SG_ 333 VVT_IntCam1Pos 7;
BA_ "FlexKomSigName" SG_ 333 VVT_IntCam1Pos "EDR2_Pkt";
BA_ "FlexKomSigLaenge" SG_ 333 VVT_IntCam1Pos 64;
BA_ "FlexKomSID" SG_ 333 VVT_IntCam1Pos 1093;
BA_ "FlexKomIsMotorola" SG_ 333 VVT_IntCam1Pos 1;
BA_ "FlexKomComment" SG_ 333 VVT_IntCam1Pos "EDR2 information packet only";
BA_ "GenSigTimeout_ORC" SG_ 333 VVT_IntCam2Pos 350;
BA_ "GenSigStartValue" SG_ 333 VVT_IntCam2Pos 255;
BA_ "GenSigSNA" SG_ 333 VVT_IntCam2Pos "0h";
BA_ "GenSigCycleTime" SG_ 333 VVT_IntCam2Pos 100;
BA_ "FlexKomSigStartValue" SG_ 333 VVT_IntCam2Pos "FFFFFFFF0000FF00h";
BA_ "FlexKomSigStartPos" SG_ 333 VVT_IntCam2Pos 7;
BA_ "FlexKomSigName" SG_ 333 VVT_IntCam2Pos "EDR2_Pkt";
BA_ "FlexKomSigLaenge" SG_ 333 VVT_IntCam2Pos 64;
BA_ "FlexKomSID" SG_ 333 VVT_IntCam2Pos 1093;
BA_ "FlexKomIsMotorola" SG_ 333 VVT_IntCam2Pos 1;
BA_ "FlexKomComment" SG_ 333 VVT_IntCam2Pos "EDR2 information packet only";
BA_ "GenSigSNA" SG_ 584 Batt_ST_Crit "0h";
BA_ "GenSigSendType" SG_ 584 Batt_ST_Crit 5;
BA_ "GenSigCycleTime" SG_ 584 Batt_ST_Crit 500;
BA_ "FlexKomSigStartValue" SG_ 584 Batt_ST_Crit "0000FFFFFF03FFFFh";
BA_ "FlexKomSigStartPos" SG_ 584 Batt_ST_Crit 7;
BA_ "FlexKomSigName" SG_ 584 Batt_ST_Crit "PN14_LHC_Stat";
BA_ "FlexKomSigLaenge" SG_ 584 Batt_ST_Crit 64;
BA_ "FlexKomSID" SG_ 584 Batt_ST_Crit 1092;
BA_ "FlexKomIsMotorola" SG_ 584 Batt_ST_Crit 1;
BA_ "FlexKomComment" SG_ 584 Batt_ST_Crit "14 V powernet limp-home cutoff state";
BA_ "GenSigTimeout_IC" SG_ 584 PN14_LS_Actv 5250;
BA_ "GenSigSNA" SG_ 584 PN14_LS_Actv "0h";
BA_ "GenSigSendType" SG_ 584 PN14_LS_Actv 5;
BA_ "GenSigCycleTime" SG_ 584 PN14_LS_Actv 500;
BA_ "FlexKomSigStartValue" SG_ 584 PN14_LS_Actv "0000FFFFFF03FFFFh";
BA_ "FlexKomSigStartPos" SG_ 584 PN14_LS_Actv 7;
BA_ "FlexKomSigName" SG_ 584 PN14_LS_Actv "PN14_LHC_Stat";
BA_ "FlexKomSigLaenge" SG_ 584 PN14_LS_Actv 64;
BA_ "FlexKomSID" SG_ 584 PN14_LS_Actv 1092;
BA_ "FlexKomIsMotorola" SG_ 584 PN14_LS_Actv 1;
BA_ "FlexKomComment" SG_ 584 PN14_LS_Actv "14 V powernet limp-home cutoff state";
BA_ "RID" SG_ 502 PTS_AlrFC "2103";
BA_ "GenSigTimeout_IC" SG_ 502 PTS_AlrFC 5250;
BA_ "GenSigTimeout_CBC" SG_ 502 PTS_AlrFC 5250;
BA_ "GenSigSNA" SG_ 502 PTS_AlrFC "Fh";
BA_ "GenSigSendType" SG_ 502 PTS_AlrFC 5;
BA_ "GenSigCycleTime" SG_ 502 PTS_AlrFC 500;
BA_ "FlexKomSigStartValue" SG_ 502 PTS_AlrFC "F0h";
BA_ "FlexKomSigStartPos" SG_ 502 PTS_AlrFC 47;
BA_ "FlexKomSigName" SG_ 502 PTS_AlrFC "PTS_FC";
BA_ "FlexKomSigLaenge" SG_ 502 PTS_AlrFC 8;
BA_ "FlexKomSID" SG_ 502 PTS_AlrFC 1121;
BA_ "FlexKomIsMotorola" SG_ 502 PTS_AlrFC 1;
BA_ "FlexKomComment" SG_ 502 PTS_AlrFC "Park assist front center warnings";
BA_ "RID" SG_ 502 PTS_AlrFL "2104";
BA_ "GenSigTimeout_IC" SG_ 502 PTS_AlrFL 5250;
BA_ "GenSigTimeout_CBC" SG_ 502 PTS_AlrFL 5250;
BA_ "GenSigSNA" SG_ 502 PTS_AlrFL "Fh";
BA_ "GenSigSendType" SG_ 502 PTS_AlrFL 5;
BA_ "GenSigCycleTime" SG_ 502 PTS_AlrFL 500;
BA_ "FlexKomSigStartValue" SG_ 502 PTS_AlrFL "F0h";
BA_ "FlexKomSigStartPos" SG_ 502 PTS_AlrFL 15;
BA_ "FlexKomSigName" SG_ 502 PTS_AlrFL "PTS_FL";
BA_ "FlexKomSigLaenge" SG_ 502 PTS_AlrFL 8;
BA_ "FlexKomSID" SG_ 502 PTS_AlrFL 1117;
BA_ "FlexKomIsMotorola" SG_ 502 PTS_AlrFL 1;
BA_ "FlexKomComment" SG_ 502 PTS_AlrFL "Park assist front left warnings";
BA_ "RID" SG_ 502 PTS_AlrFR "2100";
BA_ "GenSigTimeout_IC" SG_ 502 PTS_AlrFR 5250;
BA_ "GenSigTimeout_CBC" SG_ 502 PTS_AlrFR 5250;
BA_ "GenSigSNA" SG_ 502 PTS_AlrFR "Fh";
BA_ "GenSigSendType" SG_ 502 PTS_AlrFR 5;
BA_ "GenSigCycleTime" SG_ 502 PTS_AlrFR 500;
BA_ "FlexKomSigStartValue" SG_ 502 PTS_AlrFR "F0h";
BA_ "FlexKomSigStartPos" SG_ 502 PTS_AlrFR 23;
BA_ "FlexKomSigName" SG_ 502 PTS_AlrFR "PTS_FR";
BA_ "FlexKomSigLaenge" SG_ 502 PTS_AlrFR 8;
BA_ "FlexKomSID" SG_ 502 PTS_AlrFR 1118;
BA_ "FlexKomIsMotorola" SG_ 502 PTS_AlrFR 1;
BA_ "FlexKomComment" SG_ 502 PTS_AlrFR "Park assist front right warnings";
BA_ "RID" SG_ 502 PTS_AlrRC "1026 2098";
BA_ "GenSigTimeout_IC" SG_ 502 PTS_AlrRC 5250;
BA_ "GenSigTimeout_CBC" SG_ 502 PTS_AlrRC 5250;
BA_ "GenSigSNA" SG_ 502 PTS_AlrRC "Fh";
BA_ "GenSigSendType" SG_ 502 PTS_AlrRC 5;
BA_ "GenSigCycleTime" SG_ 502 PTS_AlrRC 500;
BA_ "FlexKomSigStartValue" SG_ 502 PTS_AlrRC "F0h";
BA_ "FlexKomSigStartPos" SG_ 502 PTS_AlrRC 55;
BA_ "FlexKomSigName" SG_ 502 PTS_AlrRC "PTS_RC";
BA_ "FlexKomSigLaenge" SG_ 502 PTS_AlrRC 8;
BA_ "FlexKomSID" SG_ 502 PTS_AlrRC 1123;
BA_ "FlexKomIsMotorola" SG_ 502 PTS_AlrRC 1;
BA_ "FlexKomComment" SG_ 502 PTS_AlrRC "Park assist rear center warnings";
BA_ "RID" SG_ 502 PTS_AlrRL "1009 2101";
BA_ "GenSigTimeout_IC" SG_ 502 PTS_AlrRL 5250;
BA_ "GenSigTimeout_CBC" SG_ 502 PTS_AlrRL 5250;
BA_ "GenSigSNA" SG_ 502 PTS_AlrRL "Fh";
BA_ "GenSigSendType" SG_ 502 PTS_AlrRL 5;
BA_ "GenSigCycleTime" SG_ 502 PTS_AlrRL 500;
BA_ "FlexKomSigStartValue" SG_ 502 PTS_AlrRL "F0h";
BA_ "FlexKomSigStartPos" SG_ 502 PTS_AlrRL 31;
BA_ "FlexKomSigName" SG_ 502 PTS_AlrRL "PTS_RL";
BA_ "FlexKomSigLaenge" SG_ 502 PTS_AlrRL 8;
BA_ "FlexKomSID" SG_ 502 PTS_AlrRL 1119;
BA_ "FlexKomIsMotorola" SG_ 502 PTS_AlrRL 1;
BA_ "FlexKomComment" SG_ 502 PTS_AlrRL "Park assist rear left warnings";
BA_ "RID" SG_ 502 PTS_AlrRR "1005 2099";
BA_ "GenSigTimeout_IC" SG_ 502 PTS_AlrRR 5250;
BA_ "GenSigTimeout_CBC" SG_ 502 PTS_AlrRR 5250;
BA_ "GenSigSNA" SG_ 502 PTS_AlrRR "Fh";
BA_ "GenSigSendType" SG_ 502 PTS_AlrRR 5;
BA_ "GenSigCycleTime" SG_ 502 PTS_AlrRR 500;
BA_ "FlexKomSigStartValue" SG_ 502 PTS_AlrRR "F0h";
BA_ "FlexKomSigStartPos" SG_ 502 PTS_AlrRR 39;
BA_ "FlexKomSigName" SG_ 502 PTS_AlrRR "PTS_RR";
BA_ "FlexKomSigLaenge" SG_ 502 PTS_AlrRR 8;
BA_ "FlexKomSID" SG_ 502 PTS_AlrRR 1120;
BA_ "FlexKomIsMotorola" SG_ 502 PTS_AlrRR 1;
BA_ "FlexKomComment" SG_ 502 PTS_AlrRR "Park assist rear right warnings";
BA_ "RID" SG_ 502 PTS_CFG_STAT "1181";
BA_ "GenSigTimeout_IC" SG_ 502 PTS_CFG_STAT 5250;
BA_ "GenSigTimeout_CBC" SG_ 502 PTS_CFG_STAT 5250;
BA_ "GenSigSNA" SG_ 502 PTS_CFG_STAT "3h";
BA_ "GenSigSendType" SG_ 502 PTS_CFG_STAT 5;
BA_ "GenSigCycleTime" SG_ 502 PTS_CFG_STAT 500;
BA_ "FlexKomSigStartValue" SG_ 502 PTS_CFG_STAT "00h";
BA_ "FlexKomSigStartPos" SG_ 502 PTS_CFG_STAT 2;
BA_ "FlexKomSigName" SG_ 502 PTS_CFG_STAT "PTS_CFG_STAT";
BA_ "FlexKomSigLaenge" SG_ 502 PTS_CFG_STAT 2;
BA_ "FlexKomSID" SG_ 502 PTS_CFG_STAT 1114;
BA_ "FlexKomIsMotorola" SG_ 502 PTS_CFG_STAT 1;
BA_ "FlexKomComment" SG_ 502 PTS_CFG_STAT "Park assist configuration status";
BA_ "GenSigTimeout_IC" SG_ 502 PTS_FT_NA 5250;
BA_ "GenSigSNA" SG_ 502 PTS_FT_NA "0h";
BA_ "GenSigSendType" SG_ 502 PTS_FT_NA 5;
BA_ "GenSigCycleTime" SG_ 502 PTS_FT_NA 500;
BA_ "FlexKomSigStartValue" SG_ 502 PTS_FT_NA "00h";
BA_ "FlexKomSigStartPos" SG_ 502 PTS_FT_NA 3;
BA_ "FlexKomSigName" SG_ 502 PTS_FT_NA "PTS_FT_NA";
BA_ "FlexKomSigLaenge" SG_ 502 PTS_FT_NA 1;
BA_ "FlexKomSID" SG_ 502 PTS_FT_NA 1314;
BA_ "FlexKomIsMotorola" SG_ 502 PTS_FT_NA 1;
BA_ "FlexKomComment" SG_ 502 PTS_FT_NA "Front park assist not available - blinded sensor; ";
BA_ "GenSigTimeout_IC" SG_ 502 PTS_FT_SRV 5250;
BA_ "GenSigSNA" SG_ 502 PTS_FT_SRV "0h";
BA_ "GenSigSendType" SG_ 502 PTS_FT_SRV 5;
BA_ "GenSigCycleTime" SG_ 502 PTS_FT_SRV 500;
BA_ "FlexKomSigStartValue" SG_ 502 PTS_FT_SRV "00h";
BA_ "FlexKomSigStartPos" SG_ 502 PTS_FT_SRV 58;
BA_ "FlexKomSigName" SG_ 502 PTS_FT_SRV "PTS_FT_SRV";
BA_ "FlexKomSigLaenge" SG_ 502 PTS_FT_SRV 1;
BA_ "FlexKomSID" SG_ 502 PTS_FT_SRV 1354;
BA_ "FlexKomIsMotorola" SG_ 502 PTS_FT_SRV 1;
BA_ "FlexKomComment" SG_ 502 PTS_FT_SRV "Front PTS sensor service request; True = [1]";
BA_ "GenSigTimeout_IC" SG_ 502 PTS_GraphicFC 5250;
BA_ "GenSigStartValue" SG_ 502 PTS_GraphicFC 3;
BA_ "GenSigSNA" SG_ 502 PTS_GraphicFC "3h";
BA_ "GenSigSendType" SG_ 502 PTS_GraphicFC 5;
BA_ "GenSigCycleTime" SG_ 502 PTS_GraphicFC 500;
BA_ "FlexKomSigStartValue" SG_ 502 PTS_GraphicFC "F0h";
BA_ "FlexKomSigStartPos" SG_ 502 PTS_GraphicFC 47;
BA_ "FlexKomSigName" SG_ 502 PTS_GraphicFC "PTS_FC";
BA_ "FlexKomSigLaenge" SG_ 502 PTS_GraphicFC 8;
BA_ "FlexKomSID" SG_ 502 PTS_GraphicFC 1121;
BA_ "FlexKomIsMotorola" SG_ 502 PTS_GraphicFC 1;
BA_ "FlexKomComment" SG_ 502 PTS_GraphicFC "Park assist front center warnings";
BA_ "GenSigTimeout_IC" SG_ 502 PTS_GraphicFL 5250;
BA_ "GenSigStartValue" SG_ 502 PTS_GraphicFL 3;
BA_ "GenSigSNA" SG_ 502 PTS_GraphicFL "3h";
BA_ "GenSigSendType" SG_ 502 PTS_GraphicFL 5;
BA_ "GenSigCycleTime" SG_ 502 PTS_GraphicFL 500;
BA_ "FlexKomSigStartValue" SG_ 502 PTS_GraphicFL "F0h";
BA_ "FlexKomSigStartPos" SG_ 502 PTS_GraphicFL 15;
BA_ "FlexKomSigName" SG_ 502 PTS_GraphicFL "PTS_FL";
BA_ "FlexKomSigLaenge" SG_ 502 PTS_GraphicFL 8;
BA_ "FlexKomSID" SG_ 502 PTS_GraphicFL 1117;
BA_ "FlexKomIsMotorola" SG_ 502 PTS_GraphicFL 1;
BA_ "FlexKomComment" SG_ 502 PTS_GraphicFL "Park assist front left warnings";
BA_ "GenSigTimeout_IC" SG_ 502 PTS_GraphicFR 5250;
BA_ "GenSigStartValue" SG_ 502 PTS_GraphicFR 3;
BA_ "GenSigSNA" SG_ 502 PTS_GraphicFR "3h";
BA_ "GenSigSendType" SG_ 502 PTS_GraphicFR 5;
BA_ "GenSigCycleTime" SG_ 502 PTS_GraphicFR 500;
BA_ "FlexKomSigStartValue" SG_ 502 PTS_GraphicFR "F0h";
BA_ "FlexKomSigStartPos" SG_ 502 PTS_GraphicFR 23;
BA_ "FlexKomSigName" SG_ 502 PTS_GraphicFR "PTS_FR";
BA_ "FlexKomSigLaenge" SG_ 502 PTS_GraphicFR 8;
BA_ "FlexKomSID" SG_ 502 PTS_GraphicFR 1118;
BA_ "FlexKomIsMotorola" SG_ 502 PTS_GraphicFR 1;
BA_ "FlexKomComment" SG_ 502 PTS_GraphicFR "Park assist front right warnings";
BA_ "GenSigTimeout_IC" SG_ 502 PTS_GraphicRC 5250;
BA_ "GenSigStartValue" SG_ 502 PTS_GraphicRC 3;
BA_ "GenSigSNA" SG_ 502 PTS_GraphicRC "3h";
BA_ "GenSigSendType" SG_ 502 PTS_GraphicRC 5;
BA_ "GenSigCycleTime" SG_ 502 PTS_GraphicRC 500;
BA_ "FlexKomSigStartValue" SG_ 502 PTS_GraphicRC "F0h";
BA_ "FlexKomSigStartPos" SG_ 502 PTS_GraphicRC 55;
BA_ "FlexKomSigName" SG_ 502 PTS_GraphicRC "PTS_RC";
BA_ "FlexKomSigLaenge" SG_ 502 PTS_GraphicRC 8;
BA_ "FlexKomSID" SG_ 502 PTS_GraphicRC 1123;
BA_ "FlexKomIsMotorola" SG_ 502 PTS_GraphicRC 1;
BA_ "FlexKomComment" SG_ 502 PTS_GraphicRC "Park assist rear center warnings";
BA_ "GenSigTimeout_IC" SG_ 502 PTS_GraphicRL 5250;
BA_ "GenSigStartValue" SG_ 502 PTS_GraphicRL 3;
BA_ "GenSigSNA" SG_ 502 PTS_GraphicRL "3h";
BA_ "GenSigSendType" SG_ 502 PTS_GraphicRL 5;
BA_ "GenSigCycleTime" SG_ 502 PTS_GraphicRL 500;
BA_ "FlexKomSigStartValue" SG_ 502 PTS_GraphicRL "F0h";
BA_ "FlexKomSigStartPos" SG_ 502 PTS_GraphicRL 31;
BA_ "FlexKomSigName" SG_ 502 PTS_GraphicRL "PTS_RL";
BA_ "FlexKomSigLaenge" SG_ 502 PTS_GraphicRL 8;
BA_ "FlexKomSID" SG_ 502 PTS_GraphicRL 1119;
BA_ "FlexKomIsMotorola" SG_ 502 PTS_GraphicRL 1;
BA_ "FlexKomComment" SG_ 502 PTS_GraphicRL "Park assist rear left warnings";
BA_ "GenSigTimeout_IC" SG_ 502 PTS_GraphicRR 5250;
BA_ "GenSigStartValue" SG_ 502 PTS_GraphicRR 3;
BA_ "GenSigSNA" SG_ 502 PTS_GraphicRR "3h";
BA_ "GenSigSendType" SG_ 502 PTS_GraphicRR 5;
BA_ "GenSigCycleTime" SG_ 502 PTS_GraphicRR 500;
BA_ "FlexKomSigStartValue" SG_ 502 PTS_GraphicRR "F0h";
BA_ "FlexKomSigStartPos" SG_ 502 PTS_GraphicRR 39;
BA_ "FlexKomSigName" SG_ 502 PTS_GraphicRR "PTS_RR";
BA_ "FlexKomSigLaenge" SG_ 502 PTS_GraphicRR 8;
BA_ "FlexKomSID" SG_ 502 PTS_GraphicRR 1120;
BA_ "FlexKomIsMotorola" SG_ 502 PTS_GraphicRR 1;
BA_ "FlexKomComment" SG_ 502 PTS_GraphicRR "Park assist rear right warnings";
BA_ "GenSigTimeout_IC" SG_ 502 PTS_RR_NA 5250;
BA_ "GenSigSNA" SG_ 502 PTS_RR_NA "0h";
BA_ "GenSigSendType" SG_ 502 PTS_RR_NA 5;
BA_ "GenSigCycleTime" SG_ 502 PTS_RR_NA 500;
BA_ "FlexKomSigStartValue" SG_ 502 PTS_RR_NA "00h";
BA_ "FlexKomSigStartPos" SG_ 502 PTS_RR_NA 4;
BA_ "FlexKomSigName" SG_ 502 PTS_RR_NA "PTS_RR_NA";
BA_ "FlexKomSigLaenge" SG_ 502 PTS_RR_NA 1;
BA_ "FlexKomSID" SG_ 502 PTS_RR_NA 1315;
BA_ "FlexKomIsMotorola" SG_ 502 PTS_RR_NA 1;
BA_ "FlexKomComment" SG_ 502 PTS_RR_NA "Rear park assist not available - blinded sensor; T";
BA_ "GenSigTimeout_IC" SG_ 502 PTS_RR_SRV 5250;
BA_ "GenSigSNA" SG_ 502 PTS_RR_SRV "0h";
BA_ "GenSigSendType" SG_ 502 PTS_RR_SRV 5;
BA_ "GenSigCycleTime" SG_ 502 PTS_RR_SRV 500;
BA_ "FlexKomSigStartValue" SG_ 502 PTS_RR_SRV "00h";
BA_ "FlexKomSigStartPos" SG_ 502 PTS_RR_SRV 59;
BA_ "FlexKomSigName" SG_ 502 PTS_RR_SRV "PTS_RR_SRV";
BA_ "FlexKomSigLaenge" SG_ 502 PTS_RR_SRV 1;
BA_ "FlexKomSID" SG_ 502 PTS_RR_SRV 1353;
BA_ "FlexKomIsMotorola" SG_ 502 PTS_RR_SRV 1;
BA_ "FlexKomComment" SG_ 502 PTS_RR_SRV "Rear PTS sensor service request; True = [1]";
BA_ "GenSigTimeout_IC" SG_ 502 PTS_SRV_RQ 5250;
BA_ "GenSigSNA" SG_ 502 PTS_SRV_RQ "0h";
BA_ "GenSigSendType" SG_ 502 PTS_SRV_RQ 5;
BA_ "GenSigCycleTime" SG_ 502 PTS_SRV_RQ 500;
BA_ "FlexKomSigStartValue" SG_ 502 PTS_SRV_RQ "00h";
BA_ "FlexKomSigStartPos" SG_ 502 PTS_SRV_RQ 5;
BA_ "FlexKomSigName" SG_ 502 PTS_SRV_RQ "PTS_SRV_RQ";
BA_ "FlexKomSigLaenge" SG_ 502 PTS_SRV_RQ 1;
BA_ "FlexKomSID" SG_ 502 PTS_SRV_RQ 54;
BA_ "FlexKomIsMotorola" SG_ 502 PTS_SRV_RQ 1;
BA_ "FlexKomComment" SG_ 502 PTS_SRV_RQ "PTS service warning request; True = [1]";
BA_ "RID" SG_ 502 PTS_STAT "1877 1939 5117";
BA_ "GenSigTimeout_CBC" SG_ 502 PTS_STAT 5250;
BA_ "GenSigSNA" SG_ 502 PTS_STAT "3h";
BA_ "GenSigSendType" SG_ 502 PTS_STAT 5;
BA_ "GenSigCycleTime" SG_ 502 PTS_STAT 500;
BA_ "FlexKomSigStartValue" SG_ 502 PTS_STAT "00h";
BA_ "FlexKomSigStartPos" SG_ 502 PTS_STAT 61;
BA_ "FlexKomSigName" SG_ 502 PTS_STAT "PTS_STAT";
BA_ "FlexKomSigLaenge" SG_ 502 PTS_STAT 2;
BA_ "FlexKomSID" SG_ 502 PTS_STAT 1862;
BA_ "FlexKomIsMotorola" SG_ 502 PTS_STAT 1;
BA_ "FlexKomComment" SG_ 502 PTS_STAT "Park Assist System - LED control status";
BA_ "GenSigTimeout_IC" SG_ 489 PTS_FT_TEMP_NA 5250;
BA_ "GenSigSNA" SG_ 489 PTS_FT_TEMP_NA "0h";
BA_ "GenSigSendType" SG_ 489 PTS_FT_TEMP_NA 5;
BA_ "GenSigCycleTime" SG_ 489 PTS_FT_TEMP_NA 500;
BA_ "FlexKomSigStartValue" SG_ 489 PTS_FT_TEMP_NA "FF001400000004FFh";
BA_ "FlexKomSigStartPos" SG_ 489 PTS_FT_TEMP_NA 7;
BA_ "FlexKomSigName" SG_ 489 PTS_FT_TEMP_NA "PTS_2_Pkt";
BA_ "FlexKomSigLaenge" SG_ 489 PTS_FT_TEMP_NA 64;
BA_ "FlexKomSID" SG_ 489 PTS_FT_TEMP_NA 1954;
BA_ "FlexKomIsMotorola" SG_ 489 PTS_FT_TEMP_NA 1;
BA_ "FlexKomComment" SG_ 489 PTS_FT_TEMP_NA "PTS 2 message packet";
BA_ "GenSigTimeout_IC" SG_ 489 PTS_Off_Status 5250;
BA_ "GenSigSNA" SG_ 489 PTS_Off_Status "0h";
BA_ "GenSigSendType" SG_ 489 PTS_Off_Status 5;
BA_ "GenSigCycleTime" SG_ 489 PTS_Off_Status 500;
BA_ "FlexKomSigStartValue" SG_ 489 PTS_Off_Status "FF001400000004FFh";
BA_ "FlexKomSigStartPos" SG_ 489 PTS_Off_Status 7;
BA_ "FlexKomSigName" SG_ 489 PTS_Off_Status "PTS_2_Pkt";
BA_ "FlexKomSigLaenge" SG_ 489 PTS_Off_Status 64;
BA_ "FlexKomSID" SG_ 489 PTS_Off_Status 1954;
BA_ "FlexKomIsMotorola" SG_ 489 PTS_Off_Status 1;
BA_ "FlexKomComment" SG_ 489 PTS_Off_Status "PTS 2 message packet";
BA_ "GenSigTimeout_IC" SG_ 489 PTS_PopUpRqst 5250;
BA_ "GenSigSNA" SG_ 489 PTS_PopUpRqst "FFh";
BA_ "GenSigSendType" SG_ 489 PTS_PopUpRqst 5;
BA_ "GenSigCycleTime" SG_ 489 PTS_PopUpRqst 500;
BA_ "FlexKomSigStartValue" SG_ 489 PTS_PopUpRqst "FF001400000004FFh";
BA_ "FlexKomSigStartPos" SG_ 489 PTS_PopUpRqst 7;
BA_ "FlexKomSigName" SG_ 489 PTS_PopUpRqst "PTS_2_Pkt";
BA_ "FlexKomSigLaenge" SG_ 489 PTS_PopUpRqst 64;
BA_ "FlexKomSID" SG_ 489 PTS_PopUpRqst 1954;
BA_ "FlexKomIsMotorola" SG_ 489 PTS_PopUpRqst 1;
BA_ "FlexKomComment" SG_ 489 PTS_PopUpRqst "PTS 2 message packet";
BA_ "GenSigTimeout_IC" SG_ 489 PTS_RR_TEMP_NA 5250;
BA_ "GenSigSNA" SG_ 489 PTS_RR_TEMP_NA "0h";
BA_ "GenSigSendType" SG_ 489 PTS_RR_TEMP_NA 5;
BA_ "GenSigCycleTime" SG_ 489 PTS_RR_TEMP_NA 500;
BA_ "FlexKomSigStartValue" SG_ 489 PTS_RR_TEMP_NA "FF001400000004FFh";
BA_ "FlexKomSigStartPos" SG_ 489 PTS_RR_TEMP_NA 7;
BA_ "FlexKomSigName" SG_ 489 PTS_RR_TEMP_NA "PTS_2_Pkt";
BA_ "FlexKomSigLaenge" SG_ 489 PTS_RR_TEMP_NA 64;
BA_ "FlexKomSID" SG_ 489 PTS_RR_TEMP_NA 1954;
BA_ "FlexKomIsMotorola" SG_ 489 PTS_RR_TEMP_NA 1;
BA_ "FlexKomComment" SG_ 489 PTS_RR_TEMP_NA "PTS 2 message packet";
BA_ "RID" SG_ 825 PTS_CHIME_REP_RATE "1140";
BA_ "GenSigSNA" SG_ 825 PTS_CHIME_REP_RATE "0h";
BA_ "GenSigSendType" SG_ 825 PTS_CHIME_REP_RATE 5;
BA_ "GenSigCycleTime" SG_ 825 PTS_CHIME_REP_RATE 500;
BA_ "FlexKomSigStartValue" SG_ 825 PTS_CHIME_REP_RATE "0050h";
BA_ "FlexKomSigStartPos" SG_ 825 PTS_CHIME_REP_RATE 7;
BA_ "FlexKomSigName" SG_ 825 PTS_CHIME_REP_RATE "PTS_CHIME_STAT";
BA_ "FlexKomSigLaenge" SG_ 825 PTS_CHIME_REP_RATE 16;
BA_ "FlexKomSID" SG_ 825 PTS_CHIME_REP_RATE 1350;
BA_ "FlexKomIsMotorola" SG_ 825 PTS_CHIME_REP_RATE 1;
BA_ "FlexKomComment" SG_ 825 PTS_CHIME_REP_RATE "PTS chime status";
BA_ "RID" SG_ 825 PTS_CHIME_TYPE "1190";
BA_ "GenSigTimeout_CBC" SG_ 825 PTS_CHIME_TYPE 5250;
BA_ "GenSigSNA" SG_ 825 PTS_CHIME_TYPE "Fh";
BA_ "GenSigSendType" SG_ 825 PTS_CHIME_TYPE 5;
BA_ "GenSigCycleTime" SG_ 825 PTS_CHIME_TYPE 500;
BA_ "FlexKomSigStartValue" SG_ 825 PTS_CHIME_TYPE "0050h";
BA_ "FlexKomSigStartPos" SG_ 825 PTS_CHIME_TYPE 7;
BA_ "FlexKomSigName" SG_ 825 PTS_CHIME_TYPE "PTS_CHIME_STAT";
BA_ "FlexKomSigLaenge" SG_ 825 PTS_CHIME_TYPE 16;
BA_ "FlexKomSID" SG_ 825 PTS_CHIME_TYPE 1350;
BA_ "FlexKomIsMotorola" SG_ 825 PTS_CHIME_TYPE 1;
BA_ "FlexKomComment" SG_ 825 PTS_CHIME_TYPE "PTS chime status";
BA_ "RID" SG_ 825 PTS_FT_VOL "1886";
BA_ "GenSigTimeout_IC" SG_ 825 PTS_FT_VOL 5250;
BA_ "GenSigTimeout_CBC" SG_ 825 PTS_FT_VOL 5250;
BA_ "GenSigStartValue" SG_ 825 PTS_FT_VOL 1;
BA_ "GenSigSNA" SG_ 825 PTS_FT_VOL "3h";
BA_ "GenSigSendType" SG_ 825 PTS_FT_VOL 5;
BA_ "GenSigCycleTime" SG_ 825 PTS_FT_VOL 500;
BA_ "FlexKomSigStartValue" SG_ 825 PTS_FT_VOL "0050h";
BA_ "FlexKomSigStartPos" SG_ 825 PTS_FT_VOL 7;
BA_ "FlexKomSigName" SG_ 825 PTS_FT_VOL "PTS_CHIME_STAT";
BA_ "FlexKomSigLaenge" SG_ 825 PTS_FT_VOL 16;
BA_ "FlexKomSID" SG_ 825 PTS_FT_VOL 1350;
BA_ "FlexKomIsMotorola" SG_ 825 PTS_FT_VOL 1;
BA_ "FlexKomComment" SG_ 825 PTS_FT_VOL "PTS chime status";
BA_ "RID" SG_ 825 PTS_LF_CHIME_RQ "1083";
BA_ "GenSigSNA" SG_ 825 PTS_LF_CHIME_RQ "0h";
BA_ "GenSigSendType" SG_ 825 PTS_LF_CHIME_RQ 5;
BA_ "GenSigCycleTime" SG_ 825 PTS_LF_CHIME_RQ 500;
BA_ "FlexKomSigStartValue" SG_ 825 PTS_LF_CHIME_RQ "0050h";
BA_ "FlexKomSigStartPos" SG_ 825 PTS_LF_CHIME_RQ 7;
BA_ "FlexKomSigName" SG_ 825 PTS_LF_CHIME_RQ "PTS_CHIME_STAT";
BA_ "FlexKomSigLaenge" SG_ 825 PTS_LF_CHIME_RQ 16;
BA_ "FlexKomSID" SG_ 825 PTS_LF_CHIME_RQ 1350;
BA_ "FlexKomIsMotorola" SG_ 825 PTS_LF_CHIME_RQ 1;
BA_ "FlexKomComment" SG_ 825 PTS_LF_CHIME_RQ "PTS chime status";
BA_ "RID" SG_ 825 PTS_LR_CHIME_RQ "1054";
BA_ "GenSigSNA" SG_ 825 PTS_LR_CHIME_RQ "0h";
BA_ "GenSigSendType" SG_ 825 PTS_LR_CHIME_RQ 5;
BA_ "GenSigCycleTime" SG_ 825 PTS_LR_CHIME_RQ 500;
BA_ "FlexKomSigStartValue" SG_ 825 PTS_LR_CHIME_RQ "0050h";
BA_ "FlexKomSigStartPos" SG_ 825 PTS_LR_CHIME_RQ 7;
BA_ "FlexKomSigName" SG_ 825 PTS_LR_CHIME_RQ "PTS_CHIME_STAT";
BA_ "FlexKomSigLaenge" SG_ 825 PTS_LR_CHIME_RQ 16;
BA_ "FlexKomSID" SG_ 825 PTS_LR_CHIME_RQ 1350;
BA_ "FlexKomIsMotorola" SG_ 825 PTS_LR_CHIME_RQ 1;
BA_ "FlexKomComment" SG_ 825 PTS_LR_CHIME_RQ "PTS chime status";
BA_ "RID" SG_ 825 PTS_RF_CHIME_RQ "1240";
BA_ "GenSigSNA" SG_ 825 PTS_RF_CHIME_RQ "0h";
BA_ "GenSigSendType" SG_ 825 PTS_RF_CHIME_RQ 5;
BA_ "GenSigCycleTime" SG_ 825 PTS_RF_CHIME_RQ 500;
BA_ "FlexKomSigStartValue" SG_ 825 PTS_RF_CHIME_RQ "0050h";
BA_ "FlexKomSigStartPos" SG_ 825 PTS_RF_CHIME_RQ 7;
BA_ "FlexKomSigName" SG_ 825 PTS_RF_CHIME_RQ "PTS_CHIME_STAT";
BA_ "FlexKomSigLaenge" SG_ 825 PTS_RF_CHIME_RQ 16;
BA_ "FlexKomSID" SG_ 825 PTS_RF_CHIME_RQ 1350;
BA_ "FlexKomIsMotorola" SG_ 825 PTS_RF_CHIME_RQ 1;
BA_ "FlexKomComment" SG_ 825 PTS_RF_CHIME_RQ "PTS chime status";
BA_ "RID" SG_ 825 PTS_RR_CHIME_RQ "1090";
BA_ "GenSigSNA" SG_ 825 PTS_RR_CHIME_RQ "0h";
BA_ "GenSigSendType" SG_ 825 PTS_RR_CHIME_RQ 5;
BA_ "GenSigCycleTime" SG_ 825 PTS_RR_CHIME_RQ 500;
BA_ "FlexKomSigStartValue" SG_ 825 PTS_RR_CHIME_RQ "0050h";
BA_ "FlexKomSigStartPos" SG_ 825 PTS_RR_CHIME_RQ 7;
BA_ "FlexKomSigName" SG_ 825 PTS_RR_CHIME_RQ "PTS_CHIME_STAT";
BA_ "FlexKomSigLaenge" SG_ 825 PTS_RR_CHIME_RQ 16;
BA_ "FlexKomSID" SG_ 825 PTS_RR_CHIME_RQ 1350;
BA_ "FlexKomIsMotorola" SG_ 825 PTS_RR_CHIME_RQ 1;
BA_ "FlexKomComment" SG_ 825 PTS_RR_CHIME_RQ "PTS chime status";
BA_ "RID" SG_ 825 PTS_RR_VOL "1891";
BA_ "GenSigTimeout_IC" SG_ 825 PTS_RR_VOL 5250;
BA_ "GenSigTimeout_CBC" SG_ 825 PTS_RR_VOL 5250;
BA_ "GenSigStartValue" SG_ 825 PTS_RR_VOL 1;
BA_ "GenSigSNA" SG_ 825 PTS_RR_VOL "3h";
BA_ "GenSigSendType" SG_ 825 PTS_RR_VOL 5;
BA_ "GenSigCycleTime" SG_ 825 PTS_RR_VOL 500;
BA_ "FlexKomSigStartValue" SG_ 825 PTS_RR_VOL "0050h";
BA_ "FlexKomSigStartPos" SG_ 825 PTS_RR_VOL 7;
BA_ "FlexKomSigName" SG_ 825 PTS_RR_VOL "PTS_CHIME_STAT";
BA_ "FlexKomSigLaenge" SG_ 825 PTS_RR_VOL 16;
BA_ "FlexKomSID" SG_ 825 PTS_RR_VOL 1350;
BA_ "FlexKomIsMotorola" SG_ 825 PTS_RR_VOL 1;
BA_ "FlexKomComment" SG_ 825 PTS_RR_VOL "PTS chime status";
BA_ "GenSigSNA" SG_ 297 CustKeyInIgn "3h";
BA_ "GenSigSendType" SG_ 297 CustKeyInIgn 5;
BA_ "GenSigCycleTime" SG_ 297 CustKeyInIgn 100;
BA_ "FlexKomSigStartValue" SG_ 297 CustKeyInIgn "1C000000h";
BA_ "FlexKomSigStartPos" SG_ 297 CustKeyInIgn 7;
BA_ "FlexKomSigName" SG_ 297 CustKeyInIgn "CustIgnPkt";
BA_ "FlexKomSigLaenge" SG_ 297 CustKeyInIgn 32;
BA_ "FlexKomSID" SG_ 297 CustKeyInIgn 1034;
BA_ "FlexKomIsMotorola" SG_ 297 CustKeyInIgn 1;
BA_ "FlexKomComment" SG_ 297 CustKeyInIgn "Customer ignition packet";
BA_ "GenSigTimeout_CBC" SG_ 297 IgnPos 1050;
BA_ "GenSigStartValue" SG_ 297 IgnPos 7;
BA_ "GenSigSNA" SG_ 297 IgnPos "7h";
BA_ "GenSigSendType" SG_ 297 IgnPos 5;
BA_ "GenSigCycleTime" SG_ 297 IgnPos 100;
BA_ "FlexKomSigStartValue" SG_ 297 IgnPos "1C000000h";
BA_ "FlexKomSigStartPos" SG_ 297 IgnPos 7;
BA_ "FlexKomSigName" SG_ 297 IgnPos "CustIgnPkt";
BA_ "FlexKomSigLaenge" SG_ 297 IgnPos 32;
BA_ "FlexKomSID" SG_ 297 IgnPos 1034;
BA_ "FlexKomIsMotorola" SG_ 297 IgnPos 1;
BA_ "FlexKomComment" SG_ 297 IgnPos "Customer ignition packet";
BA_ "GenSigSNA" SG_ 297 ValImmKey "3h";
BA_ "GenSigSendType" SG_ 297 ValImmKey 5;
BA_ "GenSigCycleTime" SG_ 297 ValImmKey 100;
BA_ "FlexKomSigStartValue" SG_ 297 ValImmKey "1C000000h";
BA_ "FlexKomSigStartPos" SG_ 297 ValImmKey 7;
BA_ "FlexKomSigName" SG_ 297 ValImmKey "CustIgnPkt";
BA_ "FlexKomSigLaenge" SG_ 297 ValImmKey 32;
BA_ "FlexKomSID" SG_ 297 ValImmKey 1034;
BA_ "FlexKomIsMotorola" SG_ 297 ValImmKey 1;
BA_ "FlexKomComment" SG_ 297 ValImmKey "Customer ignition packet";
BA_ "GenSigTimeout_IC" SG_ 448 MsgCrankInGear 2100;
BA_ "GenSigSNA" SG_ 448 MsgCrankInGear "3h";
BA_ "GenSigSendType" SG_ 448 MsgCrankInGear 5;
BA_ "GenSigCycleTime" SG_ 448 MsgCrankInGear 200;
BA_ "FlexKomSigStartValue" SG_ 448 MsgCrankInGear "000000000000h";
BA_ "FlexKomSigStartPos" SG_ 448 MsgCrankInGear 7;
BA_ "FlexKomSigName" SG_ 448 MsgCrankInGear "RFHUB_A2_Pkt";
BA_ "FlexKomSigLaenge" SG_ 448 MsgCrankInGear 48;
BA_ "FlexKomSID" SG_ 448 MsgCrankInGear 1037;
BA_ "FlexKomIsMotorola" SG_ 448 MsgCrankInGear 1;
BA_ "FlexKomComment" SG_ 448 MsgCrankInGear "RFHUB_A2_Pkt";
BA_ "RID" SG_ 448 PE_ENABLE "1166";
BA_ "GenSigTimeout_IC" SG_ 448 PE_ENABLE 2100;
BA_ "GenSigSNA" SG_ 448 PE_ENABLE "0h";
BA_ "GenSigSendType" SG_ 448 PE_ENABLE 5;
BA_ "GenSigCycleTime" SG_ 448 PE_ENABLE 200;
BA_ "FlexKomSigStartValue" SG_ 448 PE_ENABLE "000000000000h";
BA_ "FlexKomSigStartPos" SG_ 448 PE_ENABLE 7;
BA_ "FlexKomSigName" SG_ 448 PE_ENABLE "RFHUB_A2_Pkt";
BA_ "FlexKomSigLaenge" SG_ 448 PE_ENABLE 48;
BA_ "FlexKomSID" SG_ 448 PE_ENABLE 1037;
BA_ "FlexKomIsMotorola" SG_ 448 PE_ENABLE 1;
BA_ "FlexKomComment" SG_ 448 PE_ENABLE "RFHUB_A2_Pkt";
BA_ "RID" SG_ 448 RFCfgReq "1151";
BA_ "GenSigSNA" SG_ 448 RFCfgReq "7h";
BA_ "GenSigSendType" SG_ 448 RFCfgReq 5;
BA_ "GenSigCycleTime" SG_ 448 RFCfgReq 200;
BA_ "FlexKomSigStartValue" SG_ 448 RFCfgReq "000000000000h";
BA_ "FlexKomSigStartPos" SG_ 448 RFCfgReq 7;
BA_ "FlexKomSigName" SG_ 448 RFCfgReq "RFHUB_A2_Pkt";
BA_ "FlexKomSigLaenge" SG_ 448 RFCfgReq 48;
BA_ "FlexKomSID" SG_ 448 RFCfgReq 1037;
BA_ "FlexKomIsMotorola" SG_ 448 RFCfgReq 1;
BA_ "FlexKomComment" SG_ 448 RFCfgReq "RFHUB_A2_Pkt";
BA_ "RID" SG_ 448 RFFobNum "1157";
BA_ "GenSigSNA" SG_ 448 RFFobNum "Fh";
BA_ "GenSigSendType" SG_ 448 RFFobNum 5;
BA_ "GenSigCycleTime" SG_ 448 RFFobNum 200;
BA_ "FlexKomSigStartValue" SG_ 448 RFFobNum "000000000000h";
BA_ "FlexKomSigStartPos" SG_ 448 RFFobNum 7;
BA_ "FlexKomSigName" SG_ 448 RFFobNum "RFHUB_A2_Pkt";
BA_ "FlexKomSigLaenge" SG_ 448 RFFobNum 48;
BA_ "FlexKomSID" SG_ 448 RFFobNum 1037;
BA_ "FlexKomIsMotorola" SG_ 448 RFFobNum 1;
BA_ "FlexKomComment" SG_ 448 RFFobNum "RFHUB_A2_Pkt";
BA_ "RID" SG_ 448 RFFuncReq "1255";
BA_ "GenSigTimeout_IC" SG_ 448 RFFuncReq 2100;
BA_ "GenSigSNA" SG_ 448 RFFuncReq "1Fh";
BA_ "GenSigSendType" SG_ 448 RFFuncReq 5;
BA_ "GenSigCycleTime" SG_ 448 RFFuncReq 200;
BA_ "FlexKomSigStartValue" SG_ 448 RFFuncReq "000000000000h";
BA_ "FlexKomSigStartPos" SG_ 448 RFFuncReq 7;
BA_ "FlexKomSigName" SG_ 448 RFFuncReq "RFHUB_A2_Pkt";
BA_ "FlexKomSigLaenge" SG_ 448 RFFuncReq 48;
BA_ "FlexKomSID" SG_ 448 RFFuncReq 1037;
BA_ "FlexKomIsMotorola" SG_ 448 RFFuncReq 1;
BA_ "FlexKomComment" SG_ 448 RFFuncReq "RFHUB_A2_Pkt";
BA_ "RID" SG_ 448 RFReq "1288";
BA_ "GenSigSNA" SG_ 448 RFReq "7h";
BA_ "GenSigSendType" SG_ 448 RFReq 5;
BA_ "GenSigCycleTime" SG_ 448 RFReq 200;
BA_ "FlexKomSigStartValue" SG_ 448 RFReq "000000000000h";
BA_ "FlexKomSigStartPos" SG_ 448 RFReq 7;
BA_ "FlexKomSigName" SG_ 448 RFReq "RFHUB_A2_Pkt";
BA_ "FlexKomSigLaenge" SG_ 448 RFReq 48;
BA_ "FlexKomSID" SG_ 448 RFReq 1037;
BA_ "FlexKomIsMotorola" SG_ 448 RFReq 1;
BA_ "FlexKomComment" SG_ 448 RFReq "RFHUB_A2_Pkt";
BA_ "GenSigSNA" SG_ 679 FOB_ExtLT "0h";
BA_ "GenSigSendType" SG_ 679 FOB_ExtLT 5;
BA_ "GenSigCycleTime" SG_ 679 FOB_ExtLT 1000;
BA_ "FlexKomSigStartValue" SG_ 679 FOB_ExtLT "000000h";
BA_ "FlexKomSigStartPos" SG_ 679 FOB_ExtLT 7;
BA_ "FlexKomSigName" SG_ 679 FOB_ExtLT "RFMsgPkt";
BA_ "FlexKomSigLaenge" SG_ 679 FOB_ExtLT 64;
BA_ "FlexKomSID" SG_ 679 FOB_ExtLT 1038;
BA_ "FlexKomIsMotorola" SG_ 679 FOB_ExtLT 1;
BA_ "FlexKomComment" SG_ 679 FOB_ExtLT "RF message packet";
BA_ "GenSigSNA" SG_ 679 FOB_ExtRR "0h";
BA_ "GenSigSendType" SG_ 679 FOB_ExtRR 5;
BA_ "GenSigCycleTime" SG_ 679 FOB_ExtRR 1000;
BA_ "FlexKomSigStartValue" SG_ 679 FOB_ExtRR "0000000000000000h";
BA_ "FlexKomSigStartPos" SG_ 679 FOB_ExtRR 7;
BA_ "FlexKomSigName" SG_ 679 FOB_ExtRR "RFMsgPkt";
BA_ "FlexKomSigLaenge" SG_ 679 FOB_ExtRR 64;
BA_ "FlexKomSID" SG_ 679 FOB_ExtRR 1038;
BA_ "FlexKomIsMotorola" SG_ 679 FOB_ExtRR 1;
BA_ "FlexKomComment" SG_ 679 FOB_ExtRR "RF message packet";
BA_ "GenSigSNA" SG_ 679 FOB_ExtRT "0h";
BA_ "GenSigSendType" SG_ 679 FOB_ExtRT 5;
BA_ "GenSigCycleTime" SG_ 679 FOB_ExtRT 1000;
BA_ "FlexKomSigStartValue" SG_ 679 FOB_ExtRT "0000000000000000h";
BA_ "FlexKomSigStartPos" SG_ 679 FOB_ExtRT 7;
BA_ "FlexKomSigName" SG_ 679 FOB_ExtRT "RFMsgPkt";
BA_ "FlexKomSigLaenge" SG_ 679 FOB_ExtRT 64;
BA_ "FlexKomSID" SG_ 679 FOB_ExtRT 1038;
BA_ "FlexKomIsMotorola" SG_ 679 FOB_ExtRT 1;
BA_ "FlexKomComment" SG_ 679 FOB_ExtRT "RF message packet";
BA_ "GenSigSNA" SG_ 679 FOB_SrchFLT "0h";
BA_ "GenSigSendType" SG_ 679 FOB_SrchFLT 5;
BA_ "GenSigCycleTime" SG_ 679 FOB_SrchFLT 1000;
BA_ "FlexKomSigStartValue" SG_ 679 FOB_SrchFLT "0000000000000000h";
BA_ "FlexKomSigStartPos" SG_ 679 FOB_SrchFLT 7;
BA_ "FlexKomSigName" SG_ 679 FOB_SrchFLT "RFMsgPkt";
BA_ "FlexKomSigLaenge" SG_ 679 FOB_SrchFLT 64;
BA_ "FlexKomSID" SG_ 679 FOB_SrchFLT 1038;
BA_ "FlexKomIsMotorola" SG_ 679 FOB_SrchFLT 1;
BA_ "FlexKomComment" SG_ 679 FOB_SrchFLT "RF message packet";
BA_ "GenSigTimeout_CBC" SG_ 679 FOB_SrchRslt 10500;
BA_ "GenSigSNA" SG_ 679 FOB_SrchRslt "0h";
BA_ "GenSigSendType" SG_ 679 FOB_SrchRslt 5;
BA_ "GenSigCycleTime" SG_ 679 FOB_SrchRslt 1000;
BA_ "FlexKomSigStartValue" SG_ 679 FOB_SrchRslt "0000000000000000h";
BA_ "FlexKomSigStartPos" SG_ 679 FOB_SrchRslt 7;
BA_ "FlexKomSigName" SG_ 679 FOB_SrchRslt "RFMsgPkt";
BA_ "FlexKomSigLaenge" SG_ 679 FOB_SrchRslt 64;
BA_ "FlexKomSID" SG_ 679 FOB_SrchRslt 1038;
BA_ "FlexKomIsMotorola" SG_ 679 FOB_SrchRslt 1;
BA_ "FlexKomComment" SG_ 679 FOB_SrchRslt "RF message packet";
BA_ "GenSigSNA" SG_ 679 FOBinINT "0h";
BA_ "GenSigSendType" SG_ 679 FOBinINT 5;
BA_ "GenSigCycleTime" SG_ 679 FOBinINT 1000;
BA_ "FlexKomSigStartValue" SG_ 679 FOBinINT "0000000000000000h";
BA_ "FlexKomSigStartPos" SG_ 679 FOBinINT 7;
BA_ "FlexKomSigName" SG_ 679 FOBinINT "RFMsgPkt";
BA_ "FlexKomSigLaenge" SG_ 679 FOBinINT 64;
BA_ "FlexKomSID" SG_ 679 FOBinINT 1038;
BA_ "FlexKomIsMotorola" SG_ 679 FOBinINT 1;
BA_ "FlexKomComment" SG_ 679 FOBinINT "RF message packet";
BA_ "GenSigSNA" SG_ 679 FOBinTRUNK "0h";
BA_ "GenSigSendType" SG_ 679 FOBinTRUNK 5;
BA_ "GenSigCycleTime" SG_ 679 FOBinTRUNK 1000;
BA_ "FlexKomSigStartValue" SG_ 679 FOBinTRUNK "0000000000000000h";
BA_ "FlexKomSigStartPos" SG_ 679 FOBinTRUNK 7;
BA_ "FlexKomSigName" SG_ 679 FOBinTRUNK "RFMsgPkt";
BA_ "FlexKomSigLaenge" SG_ 679 FOBinTRUNK 64;
BA_ "FlexKomSID" SG_ 679 FOBinTRUNK 1038;
BA_ "FlexKomIsMotorola" SG_ 679 FOBinTRUNK 1;
BA_ "FlexKomComment" SG_ 679 FOBinTRUNK "RF message packet";
BA_ "GenSigTimeout_IC" SG_ 679 MsgFobBattLow 10500;
BA_ "GenSigSNA" SG_ 679 MsgFobBattLow "3h";
BA_ "GenSigSendType" SG_ 679 MsgFobBattLow 5;
BA_ "GenSigCycleTime" SG_ 679 MsgFobBattLow 1000;
BA_ "FlexKomSigStartValue" SG_ 679 MsgFobBattLow "0000000000000000h";
BA_ "FlexKomSigStartPos" SG_ 679 MsgFobBattLow 7;
BA_ "FlexKomSigName" SG_ 679 MsgFobBattLow "RFMsgPkt";
BA_ "FlexKomSigLaenge" SG_ 679 MsgFobBattLow 64;
BA_ "FlexKomSID" SG_ 679 MsgFobBattLow 1038;
BA_ "FlexKomIsMotorola" SG_ 679 MsgFobBattLow 1;
BA_ "FlexKomComment" SG_ 679 MsgFobBattLow "RF message packet";
BA_ "GenSigTimeout_IC" SG_ 679 MsgFobNotFnd 10500;
BA_ "GenSigSNA" SG_ 679 MsgFobNotFnd "3h";
BA_ "GenSigSendType" SG_ 679 MsgFobNotFnd 5;
BA_ "GenSigCycleTime" SG_ 679 MsgFobNotFnd 1000;
BA_ "FlexKomSigStartValue" SG_ 679 MsgFobNotFnd "0000000000000000h";
BA_ "FlexKomSigStartPos" SG_ 679 MsgFobNotFnd 7;
BA_ "FlexKomSigName" SG_ 679 MsgFobNotFnd "RFMsgPkt";
BA_ "FlexKomSigLaenge" SG_ 679 MsgFobNotFnd 64;
BA_ "FlexKomSID" SG_ 679 MsgFobNotFnd 1038;
BA_ "FlexKomIsMotorola" SG_ 679 MsgFobNotFnd 1;
BA_ "FlexKomComment" SG_ 679 MsgFobNotFnd "RF message packet";
BA_ "GenSigTimeout_IC" SG_ 679 MsgKG1 10500;
BA_ "GenSigSNA" SG_ 679 MsgKG1 "3h";
BA_ "GenSigSendType" SG_ 679 MsgKG1 5;
BA_ "GenSigCycleTime" SG_ 679 MsgKG1 1000;
BA_ "FlexKomSigStartValue" SG_ 679 MsgKG1 "0000000000000000h";
BA_ "FlexKomSigStartPos" SG_ 679 MsgKG1 7;
BA_ "FlexKomSigName" SG_ 679 MsgKG1 "RFMsgPkt";
BA_ "FlexKomSigLaenge" SG_ 679 MsgKG1 64;
BA_ "FlexKomSID" SG_ 679 MsgKG1 1038;
BA_ "FlexKomIsMotorola" SG_ 679 MsgKG1 1;
BA_ "FlexKomComment" SG_ 679 MsgKG1 "RF message packet";
BA_ "GenSigTimeout_IC" SG_ 679 MsgKG2 10500;
BA_ "GenSigSNA" SG_ 679 MsgKG2 "3h";
BA_ "GenSigSendType" SG_ 679 MsgKG2 5;
BA_ "GenSigCycleTime" SG_ 679 MsgKG2 1000;
BA_ "FlexKomSigStartValue" SG_ 679 MsgKG2 "0000000000000000h";
BA_ "FlexKomSigStartPos" SG_ 679 MsgKG2 7;
BA_ "FlexKomSigName" SG_ 679 MsgKG2 "RFMsgPkt";
BA_ "FlexKomSigLaenge" SG_ 679 MsgKG2 64;
BA_ "FlexKomSID" SG_ 679 MsgKG2 1038;
BA_ "FlexKomIsMotorola" SG_ 679 MsgKG2 1;
BA_ "FlexKomComment" SG_ 679 MsgKG2 "RF message packet";
BA_ "GenSigTimeout_IC" SG_ 679 MsgNotInPark 10500;
BA_ "GenSigSNA" SG_ 679 MsgNotInPark "3h";
BA_ "GenSigSendType" SG_ 679 MsgNotInPark 5;
BA_ "GenSigCycleTime" SG_ 679 MsgNotInPark 1000;
BA_ "FlexKomSigStartValue" SG_ 679 MsgNotInPark "0000000000000000h";
BA_ "FlexKomSigStartPos" SG_ 679 MsgNotInPark 7;
BA_ "FlexKomSigName" SG_ 679 MsgNotInPark "RFMsgPkt";
BA_ "FlexKomSigLaenge" SG_ 679 MsgNotInPark 64;
BA_ "FlexKomSID" SG_ 679 MsgNotInPark 1038;
BA_ "FlexKomIsMotorola" SG_ 679 MsgNotInPark 1;
BA_ "FlexKomComment" SG_ 679 MsgNotInPark "RF message packet";
BA_ "GenSigSNA" SG_ 656 UConnSeed1 "0h";
BA_ "GenSigSendType" SG_ 656 UConnSeed1 1;
BA_ "FlexKomSigStartValue" SG_ 656 UConnSeed1 "00000000h";
BA_ "FlexKomSigStartPos" SG_ 656 UConnSeed1 7;
BA_ "FlexKomSigName" SG_ 656 UConnSeed1 "RF_CharPkt";
BA_ "FlexKomSigLaenge" SG_ 656 UConnSeed1 32;
BA_ "FlexKomSID" SG_ 656 UConnSeed1 1794;
BA_ "FlexKomIsMotorola" SG_ 656 UConnSeed1 1;
BA_ "FlexKomComment" SG_ 656 UConnSeed1 "RF hub characters";
BA_ "GenSigSNA" SG_ 656 UConnSeed2 "0h";
BA_ "GenSigSendType" SG_ 656 UConnSeed2 1;
BA_ "FlexKomSigStartValue" SG_ 656 UConnSeed2 "00000000h";
BA_ "FlexKomSigStartPos" SG_ 656 UConnSeed2 7;
BA_ "FlexKomSigName" SG_ 656 UConnSeed2 "RF_CharPkt";
BA_ "FlexKomSigLaenge" SG_ 656 UConnSeed2 32;
BA_ "FlexKomSID" SG_ 656 UConnSeed2 1794;
BA_ "FlexKomIsMotorola" SG_ 656 UConnSeed2 1;
BA_ "FlexKomComment" SG_ 656 UConnSeed2 "RF hub characters";
BA_ "GenSigSNA" SG_ 656 UConnSeed3 "0h";
BA_ "GenSigSendType" SG_ 656 UConnSeed3 1;
BA_ "FlexKomSigStartValue" SG_ 656 UConnSeed3 "00000000h";
BA_ "FlexKomSigStartPos" SG_ 656 UConnSeed3 7;
BA_ "FlexKomSigName" SG_ 656 UConnSeed3 "RF_CharPkt";
BA_ "FlexKomSigLaenge" SG_ 656 UConnSeed3 32;
BA_ "FlexKomSID" SG_ 656 UConnSeed3 1794;
BA_ "FlexKomIsMotorola" SG_ 656 UConnSeed3 1;
BA_ "FlexKomComment" SG_ 656 UConnSeed3 "RF hub characters";
BA_ "GenSigSNA" SG_ 656 UConnSeed4 "0h";
BA_ "GenSigSendType" SG_ 656 UConnSeed4 1;
BA_ "FlexKomSigStartValue" SG_ 656 UConnSeed4 "00000000h";
BA_ "FlexKomSigStartPos" SG_ 656 UConnSeed4 7;
BA_ "FlexKomSigName" SG_ 656 UConnSeed4 "RF_CharPkt";
BA_ "FlexKomSigLaenge" SG_ 656 UConnSeed4 32;
BA_ "FlexKomSID" SG_ 656 UConnSeed4 1794;
BA_ "FlexKomIsMotorola" SG_ 656 UConnSeed4 1;
BA_ "FlexKomComment" SG_ 656 UConnSeed4 "RF hub characters";
BA_ "RID" SG_ 929 DateTmFormat2 "5015";
BA_ "GenSigTimeout_IC" SG_ 929 DateTmFormat2 10500;
BA_ "GenSigStartValue" SG_ 929 DateTmFormat2 7;
BA_ "GenSigSNA" SG_ 929 DateTmFormat2 "7h";
BA_ "GenSigSendType" SG_ 929 DateTmFormat2 5;
BA_ "GenSigCycleTime" SG_ 929 DateTmFormat2 1000;
BA_ "FlexKomSigStartValue" SG_ 929 DateTmFormat2 "07FFFFFFFF004000h";
BA_ "FlexKomSigStartPos" SG_ 929 DateTmFormat2 7;
BA_ "FlexKomSigName" SG_ 929 DateTmFormat2 "Radio_A3_Pkt";
BA_ "FlexKomSigLaenge" SG_ 929 DateTmFormat2 64;
BA_ "FlexKomSID" SG_ 929 DateTmFormat2 2562;
BA_ "FlexKomIsMotorola" SG_ 929 DateTmFormat2 1;
BA_ "FlexKomComment" SG_ 929 DateTmFormat2 "Radio A3 packet";
BA_ "RID" SG_ 929 WeekdayTmHour_End "5014";
BA_ "GenSigTimeout_IC" SG_ 929 WeekdayTmHour_End 10500;
BA_ "GenSigStartValue" SG_ 929 WeekdayTmHour_End 31;
BA_ "GenSigSNA" SG_ 929 WeekdayTmHour_End "1Fh";
BA_ "GenSigSendType" SG_ 929 WeekdayTmHour_End 5;
BA_ "GenSigCycleTime" SG_ 929 WeekdayTmHour_End 1000;
BA_ "FlexKomSigStartValue" SG_ 929 WeekdayTmHour_End "07FFFFFFFF004000h";
BA_ "FlexKomSigStartPos" SG_ 929 WeekdayTmHour_End 7;
BA_ "FlexKomSigName" SG_ 929 WeekdayTmHour_End "Radio_A3_Pkt";
BA_ "FlexKomSigLaenge" SG_ 929 WeekdayTmHour_End 64;
BA_ "FlexKomSID" SG_ 929 WeekdayTmHour_End 2562;
BA_ "FlexKomIsMotorola" SG_ 929 WeekdayTmHour_End 1;
BA_ "FlexKomComment" SG_ 929 WeekdayTmHour_End "Radio A3 packet";
BA_ "RID" SG_ 929 WeekdayTmHour_Start "5008";
BA_ "GenSigTimeout_IC" SG_ 929 WeekdayTmHour_Start 10500;
BA_ "GenSigStartValue" SG_ 929 WeekdayTmHour_Start 31;
BA_ "GenSigSNA" SG_ 929 WeekdayTmHour_Start "1Fh";
BA_ "GenSigSendType" SG_ 929 WeekdayTmHour_Start 5;
BA_ "GenSigCycleTime" SG_ 929 WeekdayTmHour_Start 1000;
BA_ "FlexKomSigStartValue" SG_ 929 WeekdayTmHour_Start "07FFFFFFFF004000h";
BA_ "FlexKomSigStartPos" SG_ 929 WeekdayTmHour_Start 7;
BA_ "FlexKomSigName" SG_ 929 WeekdayTmHour_Start "Radio_A3_Pkt";
BA_ "FlexKomSigLaenge" SG_ 929 WeekdayTmHour_Start 64;
BA_ "FlexKomSID" SG_ 929 WeekdayTmHour_Start 2562;
BA_ "FlexKomIsMotorola" SG_ 929 WeekdayTmHour_Start 1;
BA_ "FlexKomComment" SG_ 929 WeekdayTmHour_Start "Radio A3 packet";
BA_ "RID" SG_ 929 WeekdayTmMinute_End "5011";
BA_ "GenSigTimeout_IC" SG_ 929 WeekdayTmMinute_End 10500;
BA_ "GenSigStartValue" SG_ 929 WeekdayTmMinute_End 7;
BA_ "GenSigSNA" SG_ 929 WeekdayTmMinute_End "7h";
BA_ "GenSigSendType" SG_ 929 WeekdayTmMinute_End 5;
BA_ "GenSigCycleTime" SG_ 929 WeekdayTmMinute_End 1000;
BA_ "FlexKomSigStartValue" SG_ 929 WeekdayTmMinute_End "07FFFFFFFF004000h";
BA_ "FlexKomSigStartPos" SG_ 929 WeekdayTmMinute_End 7;
BA_ "FlexKomSigName" SG_ 929 WeekdayTmMinute_End "Radio_A3_Pkt";
BA_ "FlexKomSigLaenge" SG_ 929 WeekdayTmMinute_End 64;
BA_ "FlexKomSID" SG_ 929 WeekdayTmMinute_End 2562;
BA_ "FlexKomIsMotorola" SG_ 929 WeekdayTmMinute_End 1;
BA_ "FlexKomComment" SG_ 929 WeekdayTmMinute_End "Radio A3 packet";
BA_ "RID" SG_ 929 WeekdayTmMinute_Start "5009";
BA_ "GenSigTimeout_IC" SG_ 929 WeekdayTmMinute_Start 10500;
BA_ "GenSigStartValue" SG_ 929 WeekdayTmMinute_Start 7;
BA_ "GenSigSNA" SG_ 929 WeekdayTmMinute_Start "7h";
BA_ "GenSigSendType" SG_ 929 WeekdayTmMinute_Start 5;
BA_ "GenSigCycleTime" SG_ 929 WeekdayTmMinute_Start 1000;
BA_ "FlexKomSigStartValue" SG_ 929 WeekdayTmMinute_Start "07FFFFFFFF004000h";
BA_ "FlexKomSigStartPos" SG_ 929 WeekdayTmMinute_Start 7;
BA_ "FlexKomSigName" SG_ 929 WeekdayTmMinute_Start "Radio_A3_Pkt";
BA_ "FlexKomSigLaenge" SG_ 929 WeekdayTmMinute_Start 64;
BA_ "FlexKomSID" SG_ 929 WeekdayTmMinute_Start 2562;
BA_ "FlexKomIsMotorola" SG_ 929 WeekdayTmMinute_Start 1;
BA_ "FlexKomComment" SG_ 929 WeekdayTmMinute_Start "Radio A3 packet";
BA_ "RID" SG_ 929 WeekendTmHour_End "5016";
BA_ "GenSigTimeout_IC" SG_ 929 WeekendTmHour_End 10500;
BA_ "GenSigStartValue" SG_ 929 WeekendTmHour_End 31;
BA_ "GenSigSNA" SG_ 929 WeekendTmHour_End "1Fh";
BA_ "GenSigSendType" SG_ 929 WeekendTmHour_End 5;
BA_ "GenSigCycleTime" SG_ 929 WeekendTmHour_End 1000;
BA_ "FlexKomSigStartValue" SG_ 929 WeekendTmHour_End "07FFFFFFFF004000h";
BA_ "FlexKomSigStartPos" SG_ 929 WeekendTmHour_End 7;
BA_ "FlexKomSigName" SG_ 929 WeekendTmHour_End "Radio_A3_Pkt";
BA_ "FlexKomSigLaenge" SG_ 929 WeekendTmHour_End 64;
BA_ "FlexKomSID" SG_ 929 WeekendTmHour_End 2562;
BA_ "FlexKomIsMotorola" SG_ 929 WeekendTmHour_End 1;
BA_ "FlexKomComment" SG_ 929 WeekendTmHour_End "Radio A3 packet";
BA_ "RID" SG_ 929 WeekendTmHour_Start "5010";
BA_ "GenSigTimeout_IC" SG_ 929 WeekendTmHour_Start 10500;
BA_ "GenSigStartValue" SG_ 929 WeekendTmHour_Start 31;
BA_ "GenSigSNA" SG_ 929 WeekendTmHour_Start "1Fh";
BA_ "GenSigSendType" SG_ 929 WeekendTmHour_Start 5;
BA_ "GenSigCycleTime" SG_ 929 WeekendTmHour_Start 1000;
BA_ "FlexKomSigStartValue" SG_ 929 WeekendTmHour_Start "07FFFFFFFF004000h";
BA_ "FlexKomSigStartPos" SG_ 929 WeekendTmHour_Start 7;
BA_ "FlexKomSigName" SG_ 929 WeekendTmHour_Start "Radio_A3_Pkt";
BA_ "FlexKomSigLaenge" SG_ 929 WeekendTmHour_Start 64;
BA_ "FlexKomSID" SG_ 929 WeekendTmHour_Start 2562;
BA_ "FlexKomIsMotorola" SG_ 929 WeekendTmHour_Start 1;
BA_ "FlexKomComment" SG_ 929 WeekendTmHour_Start "Radio A3 packet";
BA_ "RID" SG_ 929 WeekendTmMinute_End "5012";
BA_ "GenSigTimeout_IC" SG_ 929 WeekendTmMinute_End 10500;
BA_ "GenSigStartValue" SG_ 929 WeekendTmMinute_End 7;
BA_ "GenSigSNA" SG_ 929 WeekendTmMinute_End "7h";
BA_ "GenSigSendType" SG_ 929 WeekendTmMinute_End 5;
BA_ "GenSigCycleTime" SG_ 929 WeekendTmMinute_End 1000;
BA_ "FlexKomSigStartValue" SG_ 929 WeekendTmMinute_End "07FFFFFFFF004000h";
BA_ "FlexKomSigStartPos" SG_ 929 WeekendTmMinute_End 7;
BA_ "FlexKomSigName" SG_ 929 WeekendTmMinute_End "Radio_A3_Pkt";
BA_ "FlexKomSigLaenge" SG_ 929 WeekendTmMinute_End 64;
BA_ "FlexKomSID" SG_ 929 WeekendTmMinute_End 2562;
BA_ "FlexKomIsMotorola" SG_ 929 WeekendTmMinute_End 1;
BA_ "FlexKomComment" SG_ 929 WeekendTmMinute_End "Radio A3 packet";
BA_ "RID" SG_ 929 WeekendTmMinute_Start "5013";
BA_ "GenSigTimeout_IC" SG_ 929 WeekendTmMinute_Start 10500;
BA_ "GenSigStartValue" SG_ 929 WeekendTmMinute_Start 7;
BA_ "GenSigSNA" SG_ 929 WeekendTmMinute_Start "7h";
BA_ "GenSigSendType" SG_ 929 WeekendTmMinute_Start 5;
BA_ "GenSigCycleTime" SG_ 929 WeekendTmMinute_Start 1000;
BA_ "FlexKomSigStartValue" SG_ 929 WeekendTmMinute_Start "07FFFFFFFF004000h";
BA_ "FlexKomSigStartPos" SG_ 929 WeekendTmMinute_Start 7;
BA_ "FlexKomSigName" SG_ 929 WeekendTmMinute_Start "Radio_A3_Pkt";
BA_ "FlexKomSigLaenge" SG_ 929 WeekendTmMinute_Start 64;
BA_ "FlexKomSID" SG_ 929 WeekendTmMinute_Start 2562;
BA_ "FlexKomIsMotorola" SG_ 929 WeekendTmMinute_Start 1;
BA_ "FlexKomComment" SG_ 929 WeekendTmMinute_Start "Radio A3 packet";
BA_ "RID" SG_ 302 STFAFtAlertPress "6442";
BA_ "GenSigStartValue" SG_ 302 STFAFtAlertPress 255;
BA_ "GenSigSNA" SG_ 302 STFAFtAlertPress "FFh";
BA_ "GenSigSendType" SG_ 302 STFAFtAlertPress 1;
BA_ "FlexKomSigStartValue" SG_ 302 STFAFtAlertPress "FFFF000032000000h";
BA_ "FlexKomSigStartPos" SG_ 302 STFAFtAlertPress 7;
BA_ "FlexKomSigName" SG_ 302 STFAFtAlertPress "Radio_A4_Pkt";
BA_ "FlexKomSigLaenge" SG_ 302 STFAFtAlertPress 64;
BA_ "FlexKomSID" SG_ 302 STFAFtAlertPress 16780074;
BA_ "FlexKomIsMotorola" SG_ 302 STFAFtAlertPress 1;
BA_ "FlexKomComment" SG_ 302 STFAFtAlertPress "Radio A4 packet";
BA_ "RID" SG_ 302 STFARrAlertPress "6443";
BA_ "GenSigStartValue" SG_ 302 STFARrAlertPress 255;
BA_ "GenSigSNA" SG_ 302 STFARrAlertPress "FFh";
BA_ "GenSigSendType" SG_ 302 STFARrAlertPress 1;
BA_ "FlexKomSigStartValue" SG_ 302 STFARrAlertPress "FFFF000032000000h";
BA_ "FlexKomSigStartPos" SG_ 302 STFARrAlertPress 7;
BA_ "FlexKomSigName" SG_ 302 STFARrAlertPress "Radio_A4_Pkt";
BA_ "FlexKomSigLaenge" SG_ 302 STFARrAlertPress 64;
BA_ "FlexKomSID" SG_ 302 STFARrAlertPress 16780074;
BA_ "FlexKomIsMotorola" SG_ 302 STFARrAlertPress 1;
BA_ "FlexKomComment" SG_ 302 STFARrAlertPress "Radio A4 packet";
BA_ "GenSigStartValue" SG_ 173 CRC_SBW_ROT1 255;
BA_ "GenSigSNA" SG_ 173 CRC_SBW_ROT1 "FFh";
BA_ "GenSigCycleTime" SG_ 173 CRC_SBW_ROT1 20;
BA_ "FlexKomSigStartValue" SG_ 173 CRC_SBW_ROT1 "00000000FFh";
BA_ "FlexKomSigStartPos" SG_ 173 CRC_SBW_ROT1 7;
BA_ "FlexKomSigName" SG_ 173 CRC_SBW_ROT1 "SBW_ROT1_PKT";
BA_ "FlexKomSigLaenge" SG_ 173 CRC_SBW_ROT1 40;
BA_ "FlexKomSID" SG_ 173 CRC_SBW_ROT1 1661;
BA_ "FlexKomIsMotorola" SG_ 173 CRC_SBW_ROT1 1;
BA_ "FlexKomComment" SG_ 173 CRC_SBW_ROT1 "Shift by wire - rotary 1 packet";
BA_ "GenSigTimeout_RF_HUB" SG_ 173 DrvRqShftROT 210;
BA_ "GenSigSNA" SG_ 173 DrvRqShftROT "7h";
BA_ "GenSigCycleTime" SG_ 173 DrvRqShftROT 20;
BA_ "FlexKomSigStartValue" SG_ 173 DrvRqShftROT "00000000FFh";
BA_ "FlexKomSigStartPos" SG_ 173 DrvRqShftROT 7;
BA_ "FlexKomSigName" SG_ 173 DrvRqShftROT "SBW_ROT1_PKT";
BA_ "FlexKomSigLaenge" SG_ 173 DrvRqShftROT 40;
BA_ "FlexKomSID" SG_ 173 DrvRqShftROT 1661;
BA_ "FlexKomIsMotorola" SG_ 173 DrvRqShftROT 1;
BA_ "FlexKomComment" SG_ 173 DrvRqShftROT "Shift by wire - rotary 1 packet";
BA_ "GenSigSNA" SG_ 173 MC_SBW_ROT1 "0h";
BA_ "GenSigCycleTime" SG_ 173 MC_SBW_ROT1 20;
BA_ "FlexKomSigStartValue" SG_ 173 MC_SBW_ROT1 "00000000FFh";
BA_ "FlexKomSigStartPos" SG_ 173 MC_SBW_ROT1 7;
BA_ "FlexKomSigName" SG_ 173 MC_SBW_ROT1 "SBW_ROT1_PKT";
BA_ "FlexKomSigLaenge" SG_ 173 MC_SBW_ROT1 40;
BA_ "FlexKomSID" SG_ 173 MC_SBW_ROT1 1661;
BA_ "FlexKomIsMotorola" SG_ 173 MC_SBW_ROT1 1;
BA_ "FlexKomComment" SG_ 173 MC_SBW_ROT1 "Shift by wire - rotary 1 packet";
BA_ "GenSigSNA" SG_ 173 Manual_Gate_Request "7h";
BA_ "GenSigCycleTime" SG_ 173 Manual_Gate_Request 20;
BA_ "FlexKomSigStartValue" SG_ 173 Manual_Gate_Request "00000000FFh";
BA_ "FlexKomSigStartPos" SG_ 173 Manual_Gate_Request 7;
BA_ "FlexKomSigName" SG_ 173 Manual_Gate_Request "SBW_ROT1_PKT";
BA_ "FlexKomSigLaenge" SG_ 173 Manual_Gate_Request 40;
BA_ "FlexKomSID" SG_ 173 Manual_Gate_Request 1661;
BA_ "FlexKomIsMotorola" SG_ 173 Manual_Gate_Request 1;
BA_ "FlexKomComment" SG_ 173 Manual_Gate_Request "Shift by wire - rotary 1 packet";
BA_ "GenSigSNA" SG_ 173 ShftDispFltROT "0h";
BA_ "GenSigCycleTime" SG_ 173 ShftDispFltROT 20;
BA_ "FlexKomSigStartValue" SG_ 173 ShftDispFltROT "00000000FFh";
BA_ "FlexKomSigStartPos" SG_ 173 ShftDispFltROT 7;
BA_ "FlexKomSigName" SG_ 173 ShftDispFltROT "SBW_ROT1_PKT";
BA_ "FlexKomSigLaenge" SG_ 173 ShftDispFltROT 40;
BA_ "FlexKomSID" SG_ 173 ShftDispFltROT 1661;
BA_ "FlexKomIsMotorola" SG_ 173 ShftDispFltROT 1;
BA_ "FlexKomComment" SG_ 173 ShftDispFltROT "Shift by wire - rotary 1 packet";
BA_ "GenSigSNA" SG_ 173 ShftLkFltROT "0h";
BA_ "GenSigCycleTime" SG_ 173 ShftLkFltROT 20;
BA_ "FlexKomSigStartValue" SG_ 173 ShftLkFltROT "00000000FFh";
BA_ "FlexKomSigStartPos" SG_ 173 ShftLkFltROT 7;
BA_ "FlexKomSigName" SG_ 173 ShftLkFltROT "SBW_ROT1_PKT";
BA_ "FlexKomSigLaenge" SG_ 173 ShftLkFltROT 40;
BA_ "FlexKomSID" SG_ 173 ShftLkFltROT 1661;
BA_ "FlexKomIsMotorola" SG_ 173 ShftLkFltROT 1;
BA_ "FlexKomComment" SG_ 173 ShftLkFltROT "Shift by wire - rotary 1 packet";
BA_ "GenSigTimeout_IC" SG_ 173 ShftSensFltROT 210;
BA_ "GenSigSNA" SG_ 173 ShftSensFltROT "0h";
BA_ "GenSigCycleTime" SG_ 173 ShftSensFltROT 20;
BA_ "FlexKomSigStartValue" SG_ 173 ShftSensFltROT "00000000FFh";
BA_ "FlexKomSigStartPos" SG_ 173 ShftSensFltROT 7;
BA_ "FlexKomSigName" SG_ 173 ShftSensFltROT "SBW_ROT1_PKT";
BA_ "FlexKomSigLaenge" SG_ 173 ShftSensFltROT 40;
BA_ "FlexKomSID" SG_ 173 ShftSensFltROT 1661;
BA_ "FlexKomIsMotorola" SG_ 173 ShftSensFltROT 1;
BA_ "FlexKomComment" SG_ 173 ShftSensFltROT "Shift by wire - rotary 1 packet";
BA_ "GenSigSNA" SG_ 177 ACC_DistSwDec "0h";
BA_ "GenSigSendType" SG_ 177 ACC_DistSwDec 1;
BA_ "FlexKomSigStartValue" SG_ 177 ACC_DistSwDec "0000FFh";
BA_ "FlexKomSigStartPos" SG_ 177 ACC_DistSwDec 7;
BA_ "FlexKomSigName" SG_ 177 ACC_DistSwDec "CrsCtrlLvrSts";
BA_ "FlexKomSigLaenge" SG_ 177 ACC_DistSwDec 24;
BA_ "FlexKomSID" SG_ 177 ACC_DistSwDec 1848;
BA_ "FlexKomIsMotorola" SG_ 177 ACC_DistSwDec 1;
BA_ "FlexKomComment" SG_ 177 ACC_DistSwDec "Cruise Control Lever Status";
BA_ "GenSigSNA" SG_ 177 ACC_DistSwInc "0h";
BA_ "GenSigSendType" SG_ 177 ACC_DistSwInc 1;
BA_ "FlexKomSigStartValue" SG_ 177 ACC_DistSwInc "0000FFh";
BA_ "FlexKomSigStartPos" SG_ 177 ACC_DistSwInc 7;
BA_ "FlexKomSigName" SG_ 177 ACC_DistSwInc "CrsCtrlLvrSts";
BA_ "FlexKomSigLaenge" SG_ 177 ACC_DistSwInc 24;
BA_ "FlexKomSID" SG_ 177 ACC_DistSwInc 1848;
BA_ "FlexKomIsMotorola" SG_ 177 ACC_DistSwInc 1;
BA_ "FlexKomComment" SG_ 177 ACC_DistSwInc "Cruise Control Lever Status";
BA_ "GenSigSNA" SG_ 177 ACC_On "0h";
BA_ "GenSigSendType" SG_ 177 ACC_On 1;
BA_ "FlexKomSigStartValue" SG_ 177 ACC_On "0000FFh";
BA_ "FlexKomSigStartPos" SG_ 177 ACC_On 7;
BA_ "FlexKomSigName" SG_ 177 ACC_On "CrsCtrlLvrSts";
BA_ "FlexKomSigLaenge" SG_ 177 ACC_On 24;
BA_ "FlexKomSID" SG_ 177 ACC_On 1848;
BA_ "FlexKomIsMotorola" SG_ 177 ACC_On 1;
BA_ "FlexKomComment" SG_ 177 ACC_On "Cruise Control Lever Status";
BA_ "GenSigSNA" SG_ 177 AcceleratorSts "0h";
BA_ "GenSigSendType" SG_ 177 AcceleratorSts 1;
BA_ "FlexKomSigStartValue" SG_ 177 AcceleratorSts "0000FFh";
BA_ "FlexKomSigStartPos" SG_ 177 AcceleratorSts 7;
BA_ "FlexKomSigName" SG_ 177 AcceleratorSts "CrsCtrlLvrSts";
BA_ "FlexKomSigLaenge" SG_ 177 AcceleratorSts 24;
BA_ "FlexKomSID" SG_ 177 AcceleratorSts 1848;
BA_ "FlexKomIsMotorola" SG_ 177 AcceleratorSts 1;
BA_ "FlexKomComment" SG_ 177 AcceleratorSts "Cruise Control Lever Status";
BA_ "GenSigStartValue" SG_ 177 CRC_CSWC_1 255;
BA_ "GenSigSNA" SG_ 177 CRC_CSWC_1 "FFh";
BA_ "GenSigSendType" SG_ 177 CRC_CSWC_1 1;
BA_ "FlexKomSigStartValue" SG_ 177 CRC_CSWC_1 "0000FFh";
BA_ "FlexKomSigStartPos" SG_ 177 CRC_CSWC_1 7;
BA_ "FlexKomSigName" SG_ 177 CRC_CSWC_1 "CrsCtrlLvrSts";
BA_ "FlexKomSigLaenge" SG_ 177 CRC_CSWC_1 24;
BA_ "FlexKomSID" SG_ 177 CRC_CSWC_1 1848;
BA_ "FlexKomIsMotorola" SG_ 177 CRC_CSWC_1 1;
BA_ "FlexKomComment" SG_ 177 CRC_CSWC_1 "Cruise Control Lever Status";
BA_ "GenSigSNA" SG_ 177 CruiseControlFailSts "0h";
BA_ "GenSigSendType" SG_ 177 CruiseControlFailSts 1;
BA_ "FlexKomSigStartValue" SG_ 177 CruiseControlFailSts "0000FFh";
BA_ "FlexKomSigStartPos" SG_ 177 CruiseControlFailSts 7;
BA_ "FlexKomSigName" SG_ 177 CruiseControlFailSts "CrsCtrlLvrSts";
BA_ "FlexKomSigLaenge" SG_ 177 CruiseControlFailSts 24;
BA_ "FlexKomSID" SG_ 177 CruiseControlFailSts 1848;
BA_ "FlexKomIsMotorola" SG_ 177 CruiseControlFailSts 1;
BA_ "FlexKomComment" SG_ 177 CruiseControlFailSts "Cruise Control Lever Status";
BA_ "GenSigSNA" SG_ 177 CruiseControlOnOffSts "0h";
BA_ "GenSigSendType" SG_ 177 CruiseControlOnOffSts 1;
BA_ "FlexKomSigStartValue" SG_ 177 CruiseControlOnOffSts "0000FFh";
BA_ "FlexKomSigStartPos" SG_ 177 CruiseControlOnOffSts 7;
BA_ "FlexKomSigName" SG_ 177 CruiseControlOnOffSts "CrsCtrlLvrSts";
BA_ "FlexKomSigLaenge" SG_ 177 CruiseControlOnOffSts 24;
BA_ "FlexKomSID" SG_ 177 CruiseControlOnOffSts 1848;
BA_ "FlexKomIsMotorola" SG_ 177 CruiseControlOnOffSts 1;
BA_ "FlexKomComment" SG_ 177 CruiseControlOnOffSts "Cruise Control Lever Status";
BA_ "GenSigSNA" SG_ 177 CrusCnclSwitch "0h";
BA_ "GenSigSendType" SG_ 177 CrusCnclSwitch 1;
BA_ "FlexKomSigStartValue" SG_ 177 CrusCnclSwitch "0000FFh";
BA_ "FlexKomSigStartPos" SG_ 177 CrusCnclSwitch 7;
BA_ "FlexKomSigName" SG_ 177 CrusCnclSwitch "CrsCtrlLvrSts";
BA_ "FlexKomSigLaenge" SG_ 177 CrusCnclSwitch 24;
BA_ "FlexKomSID" SG_ 177 CrusCnclSwitch 1848;
BA_ "FlexKomIsMotorola" SG_ 177 CrusCnclSwitch 1;
BA_ "FlexKomComment" SG_ 177 CrusCnclSwitch "Cruise Control Lever Status";
BA_ "GenSigSNA" SG_ 177 DeceleratorSts "0h";
BA_ "GenSigSendType" SG_ 177 DeceleratorSts 1;
BA_ "FlexKomSigStartValue" SG_ 177 DeceleratorSts "0000FFh";
BA_ "FlexKomSigStartPos" SG_ 177 DeceleratorSts 7;
BA_ "FlexKomSigName" SG_ 177 DeceleratorSts "CrsCtrlLvrSts";
BA_ "FlexKomSigLaenge" SG_ 177 DeceleratorSts 24;
BA_ "FlexKomSID" SG_ 177 DeceleratorSts 1848;
BA_ "FlexKomIsMotorola" SG_ 177 DeceleratorSts 1;
BA_ "FlexKomComment" SG_ 177 DeceleratorSts "Cruise Control Lever Status";
BA_ "GenSigSNA" SG_ 177 MC_CSWC_1 "0h";
BA_ "GenSigSendType" SG_ 177 MC_CSWC_1 1;
BA_ "FlexKomSigStartValue" SG_ 177 MC_CSWC_1 "0000FFh";
BA_ "FlexKomSigStartPos" SG_ 177 MC_CSWC_1 7;
BA_ "FlexKomSigName" SG_ 177 MC_CSWC_1 "CrsCtrlLvrSts";
BA_ "FlexKomSigLaenge" SG_ 177 MC_CSWC_1 24;
BA_ "FlexKomSID" SG_ 177 MC_CSWC_1 1848;
BA_ "FlexKomIsMotorola" SG_ 177 MC_CSWC_1 1;
BA_ "FlexKomComment" SG_ 177 MC_CSWC_1 "Cruise Control Lever Status";
BA_ "GenSigSNA" SG_ 177 ResumeSwitch "0h";
BA_ "GenSigSendType" SG_ 177 ResumeSwitch 1;
BA_ "FlexKomSigStartValue" SG_ 177 ResumeSwitch "0000FFh";
BA_ "FlexKomSigStartPos" SG_ 177 ResumeSwitch 7;
BA_ "FlexKomSigName" SG_ 177 ResumeSwitch "CrsCtrlLvrSts";
BA_ "FlexKomSigLaenge" SG_ 177 ResumeSwitch 24;
BA_ "FlexKomSID" SG_ 177 ResumeSwitch 1848;
BA_ "FlexKomIsMotorola" SG_ 177 ResumeSwitch 1;
BA_ "FlexKomComment" SG_ 177 ResumeSwitch "Cruise Control Lever Status";
BA_ "GenSigSNA" SG_ 177 SpeedLimiterOnOffSts "0h";
BA_ "GenSigSendType" SG_ 177 SpeedLimiterOnOffSts 1;
BA_ "FlexKomSigStartValue" SG_ 177 SpeedLimiterOnOffSts "0000FFh";
BA_ "FlexKomSigStartPos" SG_ 177 SpeedLimiterOnOffSts 7;
BA_ "FlexKomSigName" SG_ 177 SpeedLimiterOnOffSts "CrsCtrlLvrSts";
BA_ "FlexKomSigLaenge" SG_ 177 SpeedLimiterOnOffSts 24;
BA_ "FlexKomSID" SG_ 177 SpeedLimiterOnOffSts 1848;
BA_ "FlexKomIsMotorola" SG_ 177 SpeedLimiterOnOffSts 1;
BA_ "FlexKomComment" SG_ 177 SpeedLimiterOnOffSts "Cruise Control Lever Status";
BA_ "GenSigTimeout_ORC" SG_ 35 CRC_STW_Angle_STAT 35;
BA_ "GenSigTimeout_ETM" SG_ 35 CRC_STW_Angle_STAT 105;
BA_ "GenSigStartValue" SG_ 35 CRC_STW_Angle_STAT 255;
BA_ "GenSigSNA" SG_ 35 CRC_STW_Angle_STAT "FFh";
BA_ "GenSigCycleTime" SG_ 35 CRC_STW_Angle_STAT 10;
BA_ "FlexKomSigStartValue" SG_ 35 CRC_STW_Angle_STAT "3FFF3FFF030000FFh";
BA_ "FlexKomSigStartPos" SG_ 35 CRC_STW_Angle_STAT 7;
BA_ "FlexKomSigName" SG_ 35 CRC_STW_Angle_STAT "LRW_ST";
BA_ "FlexKomSigLaenge" SG_ 35 CRC_STW_Angle_STAT 64;
BA_ "FlexKomSID" SG_ 35 CRC_STW_Angle_STAT 418;
BA_ "FlexKomIsMotorola" SG_ 35 CRC_STW_Angle_STAT 1;
BA_ "FlexKomComment" SG_ 35 CRC_STW_Angle_STAT "Steering wheel angle state";
BA_ "RID" SG_ 35 LRW "1020 1197";
BA_ "GenSigTimeout_ORC" SG_ 35 LRW 35;
BA_ "GenSigTimeout_IC" SG_ 35 LRW 105;
BA_ "GenSigTimeout_EHPS" SG_ 35 LRW 105;
BA_ "GenSigTimeout_DTCM" SG_ 35 LRW 105;
BA_ "GenSigTimeout_CBC" SG_ 35 LRW 105;
BA_ "GenSigStartValue" SG_ 35 LRW 16383;
BA_ "GenSigSNA" SG_ 35 LRW "3FFFh";
BA_ "GenSigCycleTime" SG_ 35 LRW 10;
BA_ "FlexKomSigStartValue" SG_ 35 LRW "3FFF3FFF030000FFh";
BA_ "FlexKomSigStartPos" SG_ 35 LRW 7;
BA_ "FlexKomSigName" SG_ 35 LRW "LRW_ST";
BA_ "FlexKomSigLaenge" SG_ 35 LRW 64;
BA_ "FlexKomSID" SG_ 35 LRW 418;
BA_ "FlexKomIsMotorola" SG_ 35 LRW 1;
BA_ "FlexKomComment" SG_ 35 LRW "Steering wheel angle state";
BA_ "RID" SG_ 35 LRWS_ST "1206";
BA_ "GenSigTimeout_ORC" SG_ 35 LRWS_ST 35;
BA_ "GenSigTimeout_ETM" SG_ 35 LRWS_ST 105;
BA_ "GenSigTimeout_DTCM" SG_ 35 LRWS_ST 105;
BA_ "GenSigStartValue" SG_ 35 LRWS_ST 3;
BA_ "GenSigSNA" SG_ 35 LRWS_ST "3h";
BA_ "GenSigCycleTime" SG_ 35 LRWS_ST 10;
BA_ "FlexKomSigStartValue" SG_ 35 LRWS_ST "3FFF3FFF030000FFh";
BA_ "FlexKomSigStartPos" SG_ 35 LRWS_ST 7;
BA_ "FlexKomSigName" SG_ 35 LRWS_ST "LRW_ST";
BA_ "FlexKomSigLaenge" SG_ 35 LRWS_ST 64;
BA_ "FlexKomSID" SG_ 35 LRWS_ST 418;
BA_ "FlexKomIsMotorola" SG_ 35 LRWS_ST 1;
BA_ "FlexKomComment" SG_ 35 LRWS_ST "Steering wheel angle state";
BA_ "RID" SG_ 35 LRW_PLRTY "5030";
BA_ "GenSigTimeout_ORC" SG_ 35 LRW_PLRTY 35;
BA_ "GenSigTimeout_ETM" SG_ 35 LRW_PLRTY 105;
BA_ "GenSigTimeout_DTCM" SG_ 35 LRW_PLRTY 105;
BA_ "GenSigSNA" SG_ 35 LRW_PLRTY "0h";
BA_ "GenSigCycleTime" SG_ 35 LRW_PLRTY 10;
BA_ "FlexKomSigStartValue" SG_ 35 LRW_PLRTY "3FFF3FFF030000FFh";
BA_ "FlexKomSigStartPos" SG_ 35 LRW_PLRTY 7;
BA_ "FlexKomSigName" SG_ 35 LRW_PLRTY "LRW_ST";
BA_ "FlexKomSigLaenge" SG_ 35 LRW_PLRTY 64;
BA_ "FlexKomSID" SG_ 35 LRW_PLRTY 418;
BA_ "FlexKomIsMotorola" SG_ 35 LRW_PLRTY 1;
BA_ "FlexKomComment" SG_ 35 LRW_PLRTY "Steering wheel angle state";
BA_ "GenSigTimeout_ETM" SG_ 35 LRW_RHP 105;
BA_ "GenSigTimeout_EHPS" SG_ 35 LRW_RHP 105;
BA_ "GenSigSNA" SG_ 35 LRW_RHP "0h";
BA_ "GenSigCycleTime" SG_ 35 LRW_RHP 10;
BA_ "FlexKomSigStartValue" SG_ 35 LRW_RHP "3FFF3FFF030000FFh";
BA_ "FlexKomSigStartPos" SG_ 35 LRW_RHP 7;
BA_ "FlexKomSigName" SG_ 35 LRW_RHP "LRW_ST";
BA_ "FlexKomSigLaenge" SG_ 35 LRW_RHP 64;
BA_ "FlexKomSID" SG_ 35 LRW_RHP 418;
BA_ "FlexKomIsMotorola" SG_ 35 LRW_RHP 1;
BA_ "FlexKomComment" SG_ 35 LRW_RHP "Steering wheel angle state";
BA_ "GenSigTimeout_ORC" SG_ 35 MC_STW_Angle_STAT 35;
BA_ "GenSigTimeout_ETM" SG_ 35 MC_STW_Angle_STAT 105;
BA_ "GenSigSNA" SG_ 35 MC_STW_Angle_STAT "0h";
BA_ "GenSigCycleTime" SG_ 35 MC_STW_Angle_STAT 10;
BA_ "FlexKomSigStartValue" SG_ 35 MC_STW_Angle_STAT "3FFF3FFF030000FFh";
BA_ "FlexKomSigStartPos" SG_ 35 MC_STW_Angle_STAT 7;
BA_ "FlexKomSigName" SG_ 35 MC_STW_Angle_STAT "LRW_ST";
BA_ "FlexKomSigLaenge" SG_ 35 MC_STW_Angle_STAT 64;
BA_ "FlexKomSID" SG_ 35 MC_STW_Angle_STAT 418;
BA_ "FlexKomIsMotorola" SG_ 35 MC_STW_Angle_STAT 1;
BA_ "FlexKomComment" SG_ 35 MC_STW_Angle_STAT "Steering wheel angle state";
BA_ "GenSigTimeout_ETM" SG_ 35 Pad_Shft 105;
BA_ "GenSigSNA" SG_ 35 Pad_Shft "7h";
BA_ "GenSigCycleTime" SG_ 35 Pad_Shft 10;
BA_ "FlexKomSigStartValue" SG_ 35 Pad_Shft "3FFF3FFF030000FFh";
BA_ "FlexKomSigStartPos" SG_ 35 Pad_Shft 7;
BA_ "FlexKomSigName" SG_ 35 Pad_Shft "LRW_ST";
BA_ "FlexKomSigLaenge" SG_ 35 Pad_Shft 64;
BA_ "FlexKomSID" SG_ 35 Pad_Shft 418;
BA_ "FlexKomIsMotorola" SG_ 35 Pad_Shft 1;
BA_ "FlexKomComment" SG_ 35 Pad_Shft "Steering wheel angle state";
BA_ "GenSigTimeout_ORC" SG_ 35 VLRW 35;
BA_ "GenSigTimeout_ETM" SG_ 35 VLRW 105;
BA_ "GenSigTimeout_EHPS" SG_ 35 VLRW 105;
BA_ "GenSigTimeout_DTCM" SG_ 35 VLRW 105;
BA_ "GenSigStartValue" SG_ 35 VLRW 16383;
BA_ "GenSigSNA" SG_ 35 VLRW "3FFFh";
BA_ "GenSigCycleTime" SG_ 35 VLRW 10;
BA_ "FlexKomSigStartValue" SG_ 35 VLRW "3FFF3FFF030000FFh";
BA_ "FlexKomSigStartPos" SG_ 35 VLRW 7;
BA_ "FlexKomSigName" SG_ 35 VLRW "LRW_ST";
BA_ "FlexKomSigLaenge" SG_ 35 VLRW 64;
BA_ "FlexKomSID" SG_ 35 VLRW 418;
BA_ "FlexKomIsMotorola" SG_ 35 VLRW 1;
BA_ "FlexKomComment" SG_ 35 VLRW "Steering wheel angle state";
BA_ "GenSigSNA" SG_ 1577 SD_RS_AHLM "0h";
BA_ "GenSigSendType" SG_ 1577 SD_RS_AHLM 9;
BA_ "GenSigCycleTime" SG_ 1577 SD_RS_AHLM 200;
BA_ "FlexKomSigStartValue" SG_ 1577 SD_RS_AHLM "0000000000000000h";
BA_ "FlexKomSigStartPos" SG_ 1577 SD_RS_AHLM 7;
BA_ "FlexKomSigName" SG_ 1577 SD_RS_AHLM "SD_RS_AHLM";
BA_ "FlexKomSigLaenge" SG_ 1577 SD_RS_AHLM 64;
BA_ "FlexKomSID" SG_ 1577 SD_RS_AHLM 180;
BA_ "FlexKomIsMotorola" SG_ 1577 SD_RS_AHLM 1;
BA_ "FlexKomComment" SG_ 1577 SD_RS_AHLM "Response on Event - light";
BA_ "GenSigSNA" SG_ 1546 SD_RS_ASBS "0h";
BA_ "GenSigSendType" SG_ 1546 SD_RS_ASBS 9;
BA_ "GenSigCycleTime" SG_ 1546 SD_RS_ASBS 200;
BA_ "FlexKomSigStartValue" SG_ 1546 SD_RS_ASBS "0000000000000000h";
BA_ "FlexKomSigStartPos" SG_ 1546 SD_RS_ASBS 7;
BA_ "FlexKomSigName" SG_ 1546 SD_RS_ASBS "SD_RS_ASBS";
BA_ "FlexKomSigLaenge" SG_ 1546 SD_RS_ASBS 64;
BA_ "FlexKomSID" SG_ 1546 SD_RS_ASBS 2624;
BA_ "FlexKomIsMotorola" SG_ 1546 SD_RS_ASBS 1;
BA_ "FlexKomComment" SG_ 1546 SD_RS_ASBS "Response on Event - light";
BA_ "GenSigSNA" SG_ 1596 SD_RS_BSMO "0h";
BA_ "GenSigSendType" SG_ 1596 SD_RS_BSMO 9;
BA_ "GenSigCycleTime" SG_ 1596 SD_RS_BSMO 200;
BA_ "FlexKomSigStartValue" SG_ 1596 SD_RS_BSMO "0000000000000000h";
BA_ "FlexKomSigStartPos" SG_ 1596 SD_RS_BSMO 7;
BA_ "FlexKomSigName" SG_ 1596 SD_RS_BSMO "SD_RS_BSMO";
BA_ "FlexKomSigLaenge" SG_ 1596 SD_RS_BSMO 64;
BA_ "FlexKomSID" SG_ 1596 SD_RS_BSMO 2282;
BA_ "FlexKomIsMotorola" SG_ 1596 SD_RS_BSMO 1;
BA_ "FlexKomComment" SG_ 1596 SD_RS_BSMO "Response on Event - light";
BA_ "GenSigSNA" SG_ 1537 SD_RS_CBC "0h";
BA_ "GenSigSendType" SG_ 1537 SD_RS_CBC 9;
BA_ "GenSigCycleTime" SG_ 1537 SD_RS_CBC 200;
BA_ "FlexKomSigStartValue" SG_ 1537 SD_RS_CBC "0000000000000000h";
BA_ "FlexKomSigStartPos" SG_ 1537 SD_RS_CBC 7;
BA_ "FlexKomSigName" SG_ 1537 SD_RS_CBC "SD_RS_CBC";
BA_ "FlexKomSigLaenge" SG_ 1537 SD_RS_CBC 64;
BA_ "FlexKomSID" SG_ 1537 SD_RS_CBC 185;
BA_ "FlexKomIsMotorola" SG_ 1537 SD_RS_CBC 1;
BA_ "FlexKomComment" SG_ 1537 SD_RS_CBC "Response on Event - light";
BA_ "GenSigSNA" SG_ 1555 SD_RS_DASM "0h";
BA_ "GenSigSendType" SG_ 1555 SD_RS_DASM 9;
BA_ "GenSigCycleTime" SG_ 1555 SD_RS_DASM 200;
BA_ "FlexKomSigStartValue" SG_ 1555 SD_RS_DASM "0000000000000000h";
BA_ "FlexKomSigStartPos" SG_ 1555 SD_RS_DASM 7;
BA_ "FlexKomSigName" SG_ 1555 SD_RS_DASM "SD_RS_DASM";
BA_ "FlexKomSigLaenge" SG_ 1555 SD_RS_DASM 64;
BA_ "FlexKomSID" SG_ 1555 SD_RS_DASM 203;
BA_ "FlexKomIsMotorola" SG_ 1555 SD_RS_DASM 1;
BA_ "FlexKomComment" SG_ 1555 SD_RS_DASM "Response on Event - light";
BA_ "GenSigSNA" SG_ 1553 SD_RS_DPDM "0h";
BA_ "GenSigSendType" SG_ 1553 SD_RS_DPDM 9;
BA_ "GenSigCycleTime" SG_ 1553 SD_RS_DPDM 200;
BA_ "FlexKomSigStartValue" SG_ 1553 SD_RS_DPDM "0000000000000000h";
BA_ "FlexKomSigStartPos" SG_ 1553 SD_RS_DPDM 7;
BA_ "FlexKomSigName" SG_ 1553 SD_RS_DPDM "SD_RS_DPDM";
BA_ "FlexKomSigLaenge" SG_ 1553 SD_RS_DPDM 64;
BA_ "FlexKomSID" SG_ 1553 SD_RS_DPDM 2662;
BA_ "FlexKomIsMotorola" SG_ 1553 SD_RS_DPDM 1;
BA_ "FlexKomComment" SG_ 1553 SD_RS_DPDM "Response on Event - light";
BA_ "GenSigSNA" SG_ 1547 SD_RS_DTCM "0h";
BA_ "GenSigSendType" SG_ 1547 SD_RS_DTCM 9;
BA_ "GenSigCycleTime" SG_ 1547 SD_RS_DTCM 200;
BA_ "FlexKomSigStartValue" SG_ 1547 SD_RS_DTCM "0000000000000000h";
BA_ "FlexKomSigStartPos" SG_ 1547 SD_RS_DTCM 7;
BA_ "FlexKomSigName" SG_ 1547 SD_RS_DTCM "SD_RS_DTCM";
BA_ "FlexKomSigLaenge" SG_ 1547 SD_RS_DTCM 64;
BA_ "FlexKomSID" SG_ 1547 SD_RS_DTCM 191;
BA_ "FlexKomIsMotorola" SG_ 1547 SD_RS_DTCM 1;
BA_ "FlexKomComment" SG_ 1547 SD_RS_DTCM "Response on Event - light";
BA_ "GenSigSNA" SG_ 1592 SD_RS_ECM "0h";
BA_ "GenSigSendType" SG_ 1592 SD_RS_ECM 9;
BA_ "GenSigCycleTime" SG_ 1592 SD_RS_ECM 200;
BA_ "FlexKomSigStartValue" SG_ 1592 SD_RS_ECM "0000000000000000h";
BA_ "FlexKomSigStartPos" SG_ 1592 SD_RS_ECM 7;
BA_ "FlexKomSigName" SG_ 1592 SD_RS_ECM "SD_RS_ECM";
BA_ "FlexKomSigLaenge" SG_ 1592 SD_RS_ECM 64;
BA_ "FlexKomSID" SG_ 1592 SD_RS_ECM 192;
BA_ "FlexKomIsMotorola" SG_ 1592 SD_RS_ECM 1;
BA_ "FlexKomComment" SG_ 1592 SD_RS_ECM "Response on Event - light";
VAL_ 1026 NM_Mode 252 "LHOM" 253 "RING" 254 "ALIVE" 255 "SNA" ;
VAL_ 1026 NM_Successor 255 "SNA" ;
VAL_ 1026 NM_Ud_Launch 4 "BROADCAST" 63 "SNA" ;
VAL_ 1026 NM_Ud_Srv 2 "WAKEUP_SA" 15 "AWAKE_BC" 255 "NO_USER_DATA" ;
VAL_ 1026 Nw_Id 0 "POWERTRAIN" 1 "BODY" 2 "AUDIO_TELE" 255 "SNA" ;
VAL_ 1026 WakeupCnt 255 "SNA" ;
VAL_ 1026 WakeupRsn_IC 0 "NETWORK" 1 "IGN" 255 "SNA" ;
VAL_ 1024 NM_Mode 252 "LHOM" 253 "RING" 254 "ALIVE" 255 "SNA" ;
VAL_ 1024 NM_Successor 255 "SNA" ;
VAL_ 1024 NM_Ud_Launch 4 "BROADCAST" 63 "SNA" ;
VAL_ 1024 NM_Ud_Srv 2 "WAKEUP_SA" 15 "AWAKE_BC" 255 "NO_USER_DATA" ;
VAL_ 1024 Nw_Id 0 "POWERTRAIN" 1 "BODY" 2 "AUDIO_TELE" 255 "SNA" ;
VAL_ 1024 WakeupCnt 255 "SNA" ;
VAL_ 1024 WakeupRsn_RF_HUB 0 "NETWORK" 1 "SSB" 2 "AP1" 3 "AP2" 4 "AP3" 5 "AP4" 6 "AP5" 7 "RF_INPUT" 8 "RESET" 9 "TIMER" 10 "CLUTCH" 255 "SNA" ;
VAL_ 1033 NM_Mode 252 "LHOM" 253 "RING" 254 "ALIVE" 255 "SNA" ;
VAL_ 1033 NM_Successor 255 "SNA" ;
VAL_ 1033 NM_Ud_Launch 4 "BROADCAST" 63 "SNA" ;
VAL_ 1033 NM_Ud_Srv 2 "WAKEUP_SA" 15 "AWAKE_BC" 255 "NO_USER_DATA" ;
VAL_ 1033 Nw_Id 0 "POWERTRAIN" 1 "BODY" 2 "AUDIO_TELE" 255 "SNA" ;
VAL_ 1033 WakeupCnt 255 "SNA" ;
VAL_ 1033 WakeupRsn_SBWM 0 "NETWORK" 1 "UNLK_R_S" 255 "SNA" ;
VAL_ 1059 NM_Mode 252 "LHOM" 253 "RING" 254 "ALIVE" 255 "SNA" ;
VAL_ 1059 NM_Successor 255 "SNA" ;
VAL_ 1059 NM_Ud_Launch 4 "BROADCAST" 63 "SNA" ;
VAL_ 1059 NM_Ud_Srv 2 "WAKEUP_SA" 15 "AWAKE_BC" 255 "NO_USER_DATA" ;
VAL_ 1059 Nw_Id 0 "POWERTRAIN" 1 "BODY" 2 "AUDIO_TELE" 255 "SNA" ;
VAL_ 1059 WakeupCnt 255 "SNA" ;
VAL_ 1059 WakeupRsn_SCCM 0 "NETWORK" 71 "TILT" 72 "FP_LVR" 73 "HRN_SW" 76 "STW_SW" 255 "SNA" ;
VAL_ 1027 NM_Mode 252 "LHOM" 253 "RING" 254 "ALIVE" 255 "SNA" ;
VAL_ 1027 NM_Successor 255 "SNA" ;
VAL_ 1027 NM_Ud_Launch 4 "BROADCAST" 63 "SNA" ;
VAL_ 1027 NM_Ud_Srv 2 "WAKEUP_SA" 15 "AWAKE_BC" 255 "NO_USER_DATA" ;
VAL_ 1027 Nw_Id 0 "POWERTRAIN" 1 "BODY" 2 "AUDIO_TELE" 255 "SNA" ;
VAL_ 1027 WakeupCnt 255 "SNA" ;
VAL_ 1027 WakeupRsn_TPM 0 "NETWORK" 255 "SNA" ;
VAL_ 601 PsgSeatOCSts 0 "CLASS0" 1 "CLASS1" 3 "CLASS3" 4 "CLASS4" 15 "SNA" ;
VAL_ 601 PsgSeatSBRSts 0 "CLASS0" 1 "CLASS1" 15 "SNA" ;
VAL_ 464 DRV_SEATBELT 0 "DRV_SEATBELT_OK" 1 "DRV_SEATBELT_NOK" 2 "SEATBELT_FAIL" 3 "SNA" ;
VAL_ 464 DrvSbltUnFltr 0 "BUCKLED" 1 "UNBUCKLED" 2 "LOW" 3 "HIGH" 7 "SNA" ;
VAL_ 464 PSG_ODS_STAT 0 "ODS_STAT_NOCC" 1 "ODS_STAT_OCC" 2 "ODS_FAULT" 3 "SNA" ;
VAL_ 464 PSG_SEATBELT 0 "PSG_SEATBELT_OK" 1 "PSG_SEATBELT_NOK" 2 "SEATBELT_FAIL" 3 "SNA" ;
VAL_ 464 PsngrBagChargeSts 0 "Active" 1 "Not_Active" 2 "Not_Present" 3 "SNA" ;
VAL_ 464 SRS_IndLmp_Rq 0 "OFF" 1 "CONT" 2 "BLINK" 3 "SNA" ;
VAL_ 599 SBR2ndRowCSeatSts 0 "PSG_SEAT_OK" 2 "PSG_SEAT_NOK" 3 "SEAT_EMPTY" 4 "FAULT_OC" 5 "FAULT_SC" 6 "SNA" 7 "REMOVE_SEAT" ;
VAL_ 599 SBR2ndRowLSeatSts 0 "PSG_SEAT_OK" 2 "PSG_SEAT_NOK" 3 "SEAT_EMPTY" 4 "FAULT_OC" 5 "FAULT_SC" 6 "SNA" 7 "REMOVE_SEAT" ;
VAL_ 599 SBR2ndRowRSeatSts 0 "PSG_SEAT_OK" 2 "PSG_SEAT_NOK" 3 "SEAT_EMPTY" 4 "FAULT_OC" 5 "FAULT_SC" 6 "SNA" 7 "REMOVE_SEAT" ;
VAL_ 43 AXSStat 0 "SISL" 1 "TSE" 2 "PSE" 3 "SEII" ;
VAL_ 43 AYSStat 0 "SISL" 1 "TSE" 2 "PSE" 3 "SEII" ;
VAL_ 43 LatAcceleration 4095 "SNA" ;
VAL_ 43 LongAcceleration 4095 "SNA" ;
VAL_ 43 YRSStat 0 "SISL" 1 "TSE" 2 "PSE" 3 "SEII" ;
VAL_ 43 YawRate 4095 "SNA" ;
VAL_ 305 PTRInfo 0 "SN" 1 "CPN" 3 "SUPPLIER" ;
VAL_ 334 MAP 255 "SNA" ;
VAL_ 334 RawPVS1 255 "SNA" ;
VAL_ 334 RawPVS2 255 "SNA" ;
VAL_ 334 RawTPS1 255 "SNA" ;
VAL_ 334 RawTPS2 255 "SNA" ;
VAL_ 334 RelativePdl 255 "SNA" ;
VAL_ 334 RelativeThrt 255 "SNA" ;
VAL_ 333 GF_Charge 65535 "SNA" ;
VAL_ 333 RelativeThrtPct 255 "SNA" ;
VAL_ 333 VVT_ExhCam1Pos 0 "SNA" ;
VAL_ 333 VVT_ExhCam2Pos 0 "SNA" ;
VAL_ 333 VVT_IntCam1Pos 0 "SNA" ;
VAL_ 333 VVT_IntCam2Pos 0 "SNA" ;
VAL_ 502 PTS_AlrFC 0 "PTS_ALR_NOD" 1 "ARC1" 2 "ARC2" 3 "ARC3" 4 "ARC4" 5 "ARC5" 6 "ARC6" 7 "ARC7" 8 "ARC8" 15 "SNA" ;
VAL_ 502 PTS_AlrFL 0 "PTS_ALR_NOD" 1 "ARC1" 2 "ARC2" 3 "ARC3" 4 "ARC4" 5 "ARC5" 6 "ARC6" 7 "ARC7" 8 "ARC8" 15 "SNA" ;
VAL_ 502 PTS_AlrFR 0 "PTS_ALR_NOD" 1 "ARC1" 2 "ARC2" 3 "ARC3" 4 "ARC4" 5 "ARC5" 6 "ARC6" 7 "ARC7" 8 "ARC8" 15 "SNA" ;
VAL_ 502 PTS_AlrRC 0 "PTS_ALR_NOD" 1 "ARC1" 2 "ARC2" 3 "ARC3" 4 "ARC4" 5 "ARC5" 6 "ARC6" 7 "ARC7" 8 "ARC8" 15 "SNA" ;
VAL_ 502 PTS_AlrRL 0 "PTS_ALR_NOD" 1 "ARC1" 2 "ARC2" 3 "ARC3" 4 "ARC4" 5 "ARC5" 6 "ARC6" 7 "ARC7" 8 "ARC8" 15 "SNA" ;
VAL_ 502 PTS_AlrRR 0 "PTS_ALR_NOD" 1 "ARC1" 2 "ARC2" 3 "ARC3" 4 "ARC4" 5 "ARC5" 6 "ARC6" 7 "ARC7" 8 "ARC8" 15 "SNA" ;
VAL_ 502 PTS_CFG_STAT 0 "OFF" 1 "SND" 2 "SND_DISP" 3 "SNA" ;
VAL_ 502 PTS_GraphicFC 0 "SLOW_FLS_RQ" 1 "FAST_FLS_RQ" 2 "CONT_FLS_RQ" 3 "None" ;
VAL_ 502 PTS_GraphicFL 0 "SLOW_FLS_RQ" 1 "FAST_FLS_RQ" 2 "CONT_FLS_RQ" 3 "None" ;
VAL_ 502 PTS_GraphicFR 0 "SLOW_FLS_RQ" 1 "FAST_FLS_RQ" 2 "CONT_FLS_RQ" 3 "None" ;
VAL_ 502 PTS_GraphicRC 0 "SLOW_FLS_RQ" 1 "FAST_FLS_RQ" 2 "CONT_FLS_RQ" 3 "None" ;
VAL_ 502 PTS_GraphicRL 0 "SLOW_FLS_RQ" 1 "FAST_FLS_RQ" 2 "CONT_FLS_RQ" 3 "None" ;
VAL_ 502 PTS_GraphicRR 0 "SLOW_FLS_RQ" 1 "FAST_FLS_RQ" 2 "CONT_FLS_RQ" 3 "None" ;
VAL_ 502 PTS_STAT 0 "OFF" 1 "CONT" 2 "BLINK" 3 "SNA" ;
VAL_ 489 PTS_PopUpRqst 0 "TM0" 1 "TM1" 2 "TM2" 3 "TM3" 4 "TM4" 5 "TM5" 6 "TM6" 7 "TM7" 8 "TM8" 9 "TM9" 10 "TM10" 11 "TM11" 12 "TM12" 13 "TM13" 14 "TM14" 15 "TM15" 16 "TM16" 17 "TM17" 18 "TM18" 19 "TM19" 20 "TM20" 21 "TM21" 22 "TM22" 23 "TM23" 24 "TM24" 25 "TM25" 26 "TM26" 27 "TM27" 28 "TM28" 29 "TM29" 30 "TM30" 31 "TM31" 32 "TM32" 33 "TM33" 34 "TM34" 35 "TM35" 36 "TM36" 37 "TM37" 38 "TM38" 39 "TM39" 40 "TM40" 41 "TM41" 42 "TM42" 43 "TM43" 44 "TM44" 45 "TM45" 46 "TM46" 47 "TM47" 48 "TM48" 49 "TM49" 50 "TM50" 51 "TM51" 52 "TM52" 53 "TM53" 54 "TM54" 55 "TM55" 56 "TM56" 57 "TM57" 58 "TM58" 59 "TM59" 60 "TM60" 61 "TM61" 62 "TM62" 63 "TM63" 64 "TM64" 65 "TM65" 66 "TM66" 67 "TM67" 68 "TM68" 69 "TM69" 70 "TM70" 71 "TM71" 72 "TM72" 73 "TM73" 74 "TM74" 75 "TM75" 76 "TM76" 77 "TM77" 78 "TM78" 79 "TM79" 80 "TM80" 81 "TM81" 82 "TM82" 83 "TM83" 84 "TM84" 85 "TM85" 86 "TM86" 87 "TM87" 88 "TM88" 89 "TM89" 90 "TM90" 91 "TM91" 92 "TM92" 93 "TM93" 94 "TM94" 95 "TM95" 96 "TM96" 97 "TM97" 98 "TM98" 99 "TM99" 100 "TM100" 255 "SNA" ;
VAL_ 825 PTS_CHIME_TYPE 0 "NONE" 1 "TYP_1" 2 "TYP_2" 3 "TYP_3" 4 "TYP_4" 5 "TYP_5" 6 "TYP_6" 7 "TYP_7" 8 "TYP_8" 9 "TYP_9" 10 "TYP_10" 11 "TYP_11" 12 "TYP_12" 13 "TYP_13" 14 "TYP_14" 15 "SNA" ;
VAL_ 825 PTS_FT_VOL 0 "LOW" 1 "MED" 2 "HIGH" 3 "SNA" ;
VAL_ 825 PTS_RR_VOL 0 "LOW" 1 "MED" 2 "HIGH" 3 "SNA" ;
VAL_ 297 CustKeyInIgn 0 "CUST_KEY_DEFAULT" 1 "CUST_KEY_NOT_IN_IGNITION" 2 "CUST_KEY_IN_IGNITION" 3 "SNA" ;
VAL_ 297 IgnPos 0 "IGN_LK" 3 "IGN_OFF_ACC" 4 "IGN_RUN" 5 "IGN_START" 7 "SNA" ;
VAL_ 297 ValImmKey 0 "CUST_IMMOB_KEY_DEFAULT" 1 "CUST_IMMOB_KEY_VALID" 3 "SNA" ;
VAL_ 448 MsgCrankInGear 0 "MSG_DEFAULT" 1 "MSG_ACTIVE" 3 "SNA" ;
VAL_ 448 RFCfgReq 0 "DEFAULT" 1 "HORN_CHIRP_TOGGLE" 2 "OPTICAL_CHIRP_TOGGLE" 3 "DRIVER_UNLOCK_FIRST_TOGGLE" 7 "SNA" ;
VAL_ 448 RFFobNum 0 "FOB_DEFAULT" 1 "FOB_1" 2 "FOB_2" 3 "FOB_3" 4 "FOB_4" 5 "FOB_5" 6 "FOB_6" 7 "FOB_7" 8 "FOB_8" 15 "SNA" ;
VAL_ 448 RFFuncReq 0 "NO_BASIC_REQUEST" 1 "LOCK_REQUEST" 2 "RELOCK_REQUEST" 3 "DRIVER_UNLOCK_REQUEST" 4 "ALL_UNLOCK_REQUEST" 5 "TRUNK_PLG_TOGGLE_REQUEST" 6 "LEFT_SLIDER_TOGGLE_REQUEST" 7 "RIGHT_SLIDER_TOGGLE_REQUEST" 8 "FLIPPER_GLASS_REQUEST" 9 "REMOTE_START_ON" 10 "REMOTE_START_OFF" 11 "GLOBAL_WINDOW_DOWN_REQUEST" 12 "OPEN_CONVERTIBLE_TOP" 13 "CLOSE_CONVERTIBLE_TOP" 14 "PANIC_TOGGLE_REQUEST" 15 "DRIVER_TOGGLE_REQUEST" 16 "PASSENGER_TOGGLE_REQUEST" 17 "ExtLightReq" 18 "AirSuspReq" 19 "AirSuspCancel" 20 "GLBL_WIN_UP_RQ" 21 "CAR_FINDER_REQUEST" 22 "TRUNK_PLG_BTN_PRESSED" 23 "TRUNK_PLG_STOP_REQUEST" 24 "TRUNK_PLG_OPEN_REQUEST" 25 "TRUNK_PLG_CLOSE_REQUEST" 26 "VTA_RQ" 27 "RAP_UNLOCK_REQUEST" 28 "ABORT_CRANKING_ON_REQUEST" 29 "ABORT_CRANKING_OFF_REQUEST" 30 "HEADLIGHTS_OFF_DELAY" 31 "SNA" ;
VAL_ 448 RFReq 0 "REQUESTOR_DEFAULT" 1 "REQUESTOR_RKE" 2 "REQUESTOR_PE" 3 "REQUESTOR_REMOTESTART" 4 "REQUESTOR_UCONNECT" 5 "REQUESTOR_PE_HANDSFREE" 7 "SNA" ;
VAL_ 679 FOB_SrchRslt 0 "NO_ACT" 1 "SIP" 2 "COMPLETE" 3 "TIMEOUT" ;
VAL_ 679 MsgFobBattLow 0 "MSG_DEFAULT" 1 "MSG_ACTIVE" 3 "SNA" ;
VAL_ 679 MsgFobNotFnd 0 "MSG_DEFAULT" 1 "MSG_ACTIVE" 3 "SNA" ;
VAL_ 679 MsgKG1 0 "MSG_DEFAULT" 1 "MSG_ACTIVE" 3 "SNA" ;
VAL_ 679 MsgKG2 0 "MSG_DEFAULT" 1 "MSG_ACTIVE" 3 "SNA" ;
VAL_ 679 MsgNotInPark 0 "MSG_DEFAULT" 1 "MSG_ACTIVE" 3 "SNA" ;
VAL_ 929 DateTmFormat2 0 "NDEF0" 1 "FORMAT_12H" 2 "FORMAT_24H" 3 "FORMAT_0" 4 "FORMAT_1" 5 "FORMAT_2" 6 "FORMAT_3" 7 "SNA" ;
VAL_ 929 WeekdayTmHour_End 25 "Charge_Full" 31 "SNA" ;
VAL_ 929 WeekdayTmHour_Start 31 "SNA" ;
VAL_ 929 WeekdayTmMinute_End 0 "ZERO" 1 "FIFTEEN" 2 "THIRTY" 3 "FOURTY_FIVE" 7 "SNA" ;
VAL_ 929 WeekdayTmMinute_Start 0 "ZERO" 1 "FIFTEEN" 2 "THIRTY" 3 "FOURTY_FIVE" 7 "SNA" ;
VAL_ 929 WeekendTmHour_End 25 "Charge_Full" 31 "SNA" ;
VAL_ 929 WeekendTmHour_Start 31 "SNA" ;
VAL_ 929 WeekendTmMinute_End 0 "ZERO" 1 "FIFTEEN" 2 "THIRTY" 3 "FOURTY_FIVE" 7 "SNA" ;
VAL_ 929 WeekendTmMinute_Start 0 "ZERO" 1 "FIFTEEN" 2 "THIRTY" 3 "FOURTY_FIVE" 7 "SNA" ;
VAL_ 302 STFAFtAlertPress 255 "SNA" ;
VAL_ 302 STFARrAlertPress 255 "SNA" ;
VAL_ 173 DrvRqShftROT 0 "INIT" 1 "PARK" 2 "REV" 3 "NEUT" 4 "DRIVE" 5 "FIFTH" 7 "SNA" ;
VAL_ 173 Manual_Gate_Request 0 "Not_Active" 2 "PLUS" 3 "MINUS" 4 "BOTH" 7 "SNA" ;
VAL_ 35 LRW 16383 "SNA" ;
VAL_ 35 LRWS_ST 0 "OK" 1 "INI" 2 "ERR" 3 "ERR_INI" ;
VAL_ 35 Pad_Shft 0 "PS_OFF" 1 "PS_RIGHT" 2 "PS_LEFT" 3 "PS_BOTH" 7 "SNA" ;
VAL_ 35 VLRW 16383 "SNA" ;
